VERSION ""

NS_ :

BS_:

BU_: AHLM ASBS CADM CBC DIAGNOST DPDM DTCM ECM EHPS ESC ESL ESM ETM EVCU2 GPF IC IRCM LTM OCM ORC PTS RF_HUB SCCM SGW TBM TCM

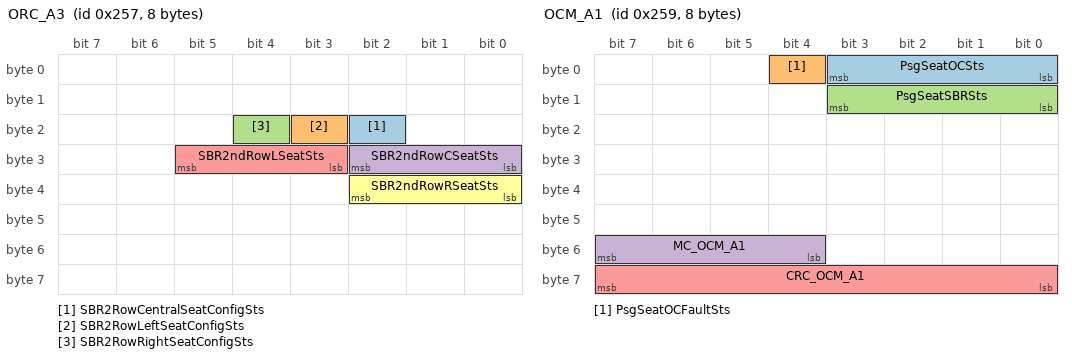
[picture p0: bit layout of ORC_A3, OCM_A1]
BO_ 599 ORC_A3: 8 ORC
 SG_ SBR2RowCentralSeatConfigSts : 18|1@1+ (1,0) [0|0] ""  IC,SGW
 SG_ SBR2RowLeftSeatConfigSts : 19|1@1+ (1,0) [0|0] ""  IC,SGW
 SG_ SBR2RowRightSeatConfigSts : 20|1@1+ (1,0) [0|0] ""  IC,SGW
 SG_ SBR2ndRowCSeatSts : 24|3@1+ (1,0) [0|0] ""  IC,SGW,TBM
 SG_ SBR2ndRowLSeatSts : 27|3@1+ (1,0) [0|0] ""  IC,SGW,TBM
 SG_ SBR2ndRowRSeatSts : 32|3@1+ (1,0) [0|0] ""  IC,SGW,TBM

BO_ 601 OCM_A1: 8 OCM
 SG_ PsgSeatOCSts : 0|4@1+ (1,0) [0|0] ""  ORC,RF_HUB,SGW
 SG_ PsgSeatOCFaultSts : 4|1@1+ (1,0) [0|0] ""  ORC,SGW
 SG_ PsgSeatSBRSts : 8|4@1+ (1,0) [0|0] ""  ORC,SGW
 SG_ MC_OCM_A1 : 52|4@1+ (1,0) [0|15] ""  ORC,SGW
 SG_ CRC_OCM_A1 : 56|8@1+ (1,0) [0|0] ""  ORC,SGW

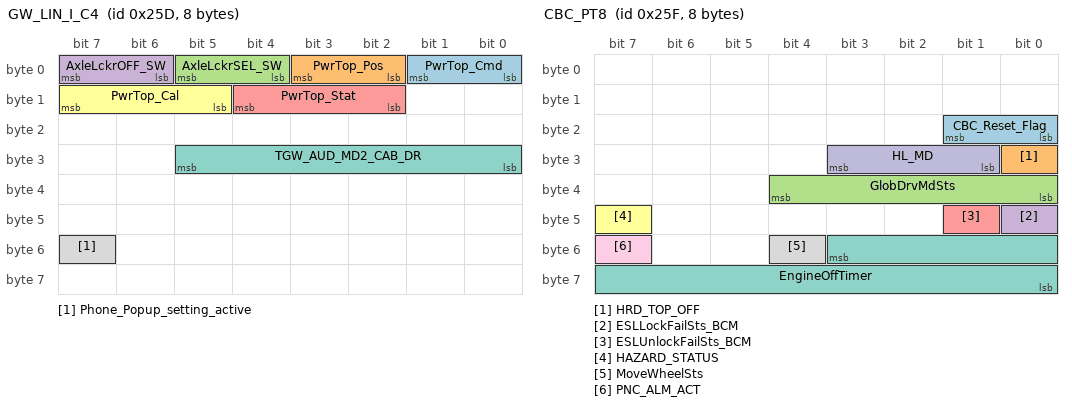
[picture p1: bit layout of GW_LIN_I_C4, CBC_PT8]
BO_ 605 GW_LIN_I_C4: 8 CBC
 SG_ PwrTop_Cmd : 0|2@1+ (1,0) [0|0] ""  SGW
 SG_ PwrTop_Pos : 2|2@1+ (1,0) [0|0] ""  SGW
 SG_ AxleLckrSEL_SW : 4|2@1+ (1,0) [0|0] ""  DTCM,SGW
 SG_ AxleLckrOFF_SW : 6|2@1+ (1,0) [0|0] ""  DTCM,SGW
 SG_ PwrTop_Stat : 10|3@1+ (1,0) [0|0] ""  IC,SGW
 SG_ PwrTop_Cal : 13|3@1+ (1,0) [0|0] ""  IC,SGW
 SG_ TGW_AUD_MD2_CAB_DR : 24|6@1+ (1,0) [0|0] ""  IC,SGW
 SG_ Phone_Popup_setting_active : 55|1@1+ (1,0) [0|0] ""  IC,SGW

BO_ 607 CBC_PT8: 8 CBC
 SG_ CBC_Reset_Flag : 16|2@1+ (1,0) [0|0] ""  ECM,SGW
 SG_ HRD_TOP_OFF : 24|1@1+ (1,0) [0|0] ""  SGW
 SG_ GlobDrvMdSts : 32|5@1+ (1,0) [0|0] ""  CADM,DTCM,ECM,ESC,EVCU2,IC,IRCM,ORC,SGW
 SG_ ESLLockFailSts_BCM : 40|1@1+ (1,0) [0|0] ""  IC,SGW
 SG_ ESLUnlockFailSts_BCM : 41|1@1+ (1,0) [0|0] ""  IC,SGW
 SG_ HAZARD_STATUS : 47|1@1+ (1,0) [0|0] ""  CADM,ORC,SGW
 SG_ EngineOffTimer : 51|12@0+ (1,0) [0|4080] "min"  ECM,ETM,SGW,TBM
 SG_ MoveWheelSts : 52|1@1+ (1,0) [0|0] ""  IC,SGW
 SG_ PNC_ALM_ACT : 55|1@1+ (1,0) [0|0] ""  SGW
 SG_ HL_MD : 25|3@1+ (1,0) [0|0] ""  CADM,SGW

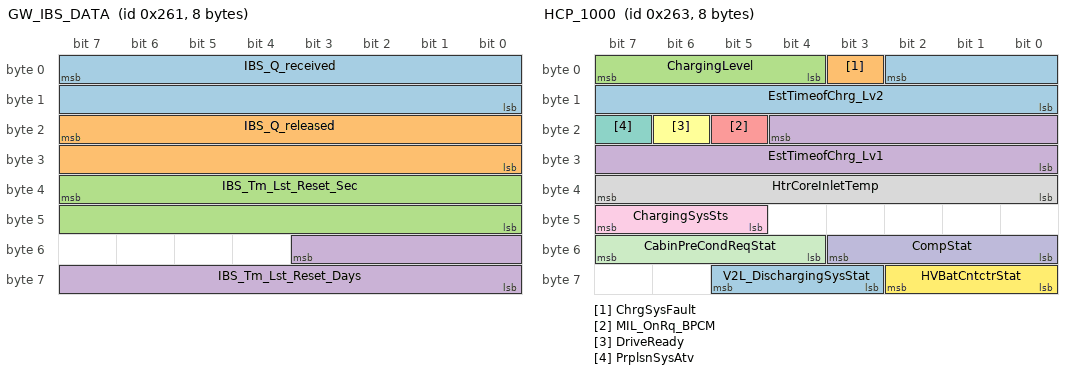
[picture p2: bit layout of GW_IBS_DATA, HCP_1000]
BO_ 609 GW_IBS_DATA: 8 CBC
 SG_ IBS_Q_received : 7|16@0+ (0.125,0) [0|8191.75] "Ah"  SGW
 SG_ IBS_Q_released : 23|16@0+ (0.125,0) [0|8191.75] "Ah"  SGW
 SG_ IBS_Tm_Lst_Reset_Sec : 39|16@0+ (2,0) [0|86398] "sec"  SGW
 SG_ IBS_Tm_Lst_Reset_Days : 51|12@0+ (1,0) [0|4094] "Days"  SGW

BO_ 611 HCP_1000: 8 EVCU2
 SG_ EstTimeofChrg_Lv2 : 2|11@0+ (1,0) [0|2046] "min"  CBC,ETM,IC,SGW,TBM
 SG_ ChrgSysFault : 3|1@1+ (1,0) [0|0] ""  ETM,IC,SGW,TBM
 SG_ ChargingLevel : 4|4@1+ (1,0) [0|0] ""  CBC,ETM,IC,SGW,TBM
 SG_ EstTimeofChrg_Lv1 : 20|13@0+ (1,0) [0|8190] "min"  CBC,ETM,IC,SGW,TBM
 SG_ MIL_OnRq_BPCM : 21|1@1+ (1,0) [0|0] ""  IC,SGW,TBM
 SG_ DriveReady : 22|1@1+ (1,0) [0|0] ""  AHLM,CADM,CBC,ETM,IC,IRCM,SGW,TBM
 SG_ PrplsnSysAtv : 23|1@1+ (1,0) [0|0] ""  CBC,ECM,EHPS,ESC,ETM,IC,RF_HUB,SGW,TBM
 SG_ HtrCoreInletTemp : 32|8@1+ (1,-40) [-40|214] "∞C"  CBC,ECM,SGW
 SG_ ChargingSysSts : 45|3@1+ (1,0) [0|0] ""  CBC,ETM,IC,SGW,TBM
 SG_ CompStat : 48|4@1+ (1,0) [0|0] ""  CBC,SGW
 SG_ CabinPreCondReqStat : 52|4@1+ (1,0) [0|0] ""  IC,SGW
 SG_ HVBatCntctrStat : 56|3@1+ (1,0) [0|0] ""  ETM,IC,ORC,SGW,TBM
 SG_ V2L_DischargingSysStat : 59|3@1+ (1,0) [0|0] ""  RF_HUB,SGW

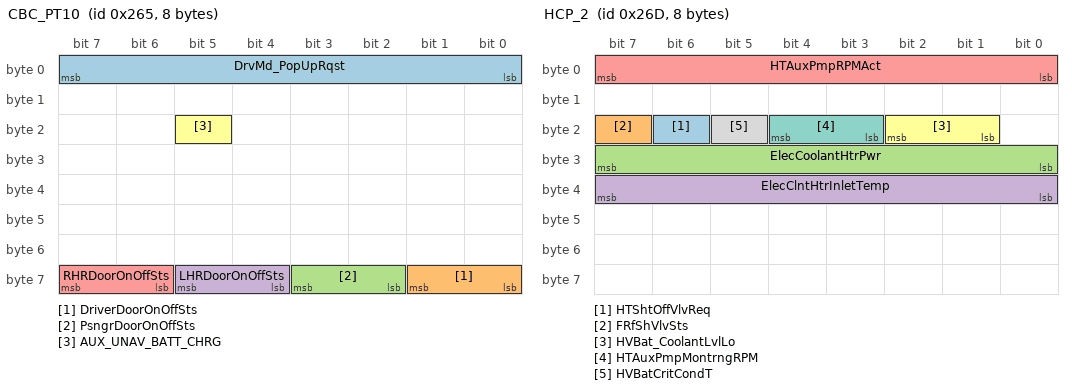
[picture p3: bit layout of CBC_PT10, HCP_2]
BO_ 613 CBC_PT10: 8 CBC
 SG_ DrvMd_PopUpRqst : 0|8@1+ (1,0) [0|0] ""  IC,SGW
 SG_ DriverDoorOnOffSts : 56|2@1+ (1,0) [0|0] ""  CADM,ESC,EVCU2,IC,IRCM,RF_HUB,SGW
 SG_ PsngrDoorOnOffSts : 58|2@1+ (1,0) [0|0] ""  RF_HUB,SGW
 SG_ LHRDoorOnOffSts : 60|2@1+ (1,0) [0|0] ""  RF_HUB,SGW
 SG_ RHRDoorOnOffSts : 62|2@1+ (1,0) [0|0] ""  RF_HUB,SGW
 SG_ AUX_UNAV_BATT_CHRG : 21|1@1+ (1,0) [0|0] ""  IC,SGW

BO_ 621 HCP_2: 8 EVCU2
 SG_ HTShtOffVlvReq : 22|1@1+ (1,0) [0|0] ""  CBC,ECM,SGW
 SG_ FRfShVlvSts : 23|1@1+ (1,0) [0|0] ""  CBC,SGW
 SG_ ElecCoolantHtrPwr : 24|8@1+ (0.04,0) [0|10.16] "kW"  CBC,ECM,SGW
 SG_ ElecClntHtrInletTemp : 32|8@1+ (1,-40) [-40|214] "∞C"  ECM,SGW
 SG_ HTAuxPmpRPMAct : 0|8@1+ (24,0) [0|6096] "rpm"  CBC,ECM,SGW
 SG_ HVBat_CoolantLvlLo : 17|2@1+ (1,0) [0|0] ""  IC,SGW
 SG_ HTAuxPmpMontrngRPM : 19|2@1+ (1,0) [0|0] ""  ECM,SGW
 SG_ HVBatCritCondT : 21|1@1+ (1,0) [0|0] ""  CBC,SGW

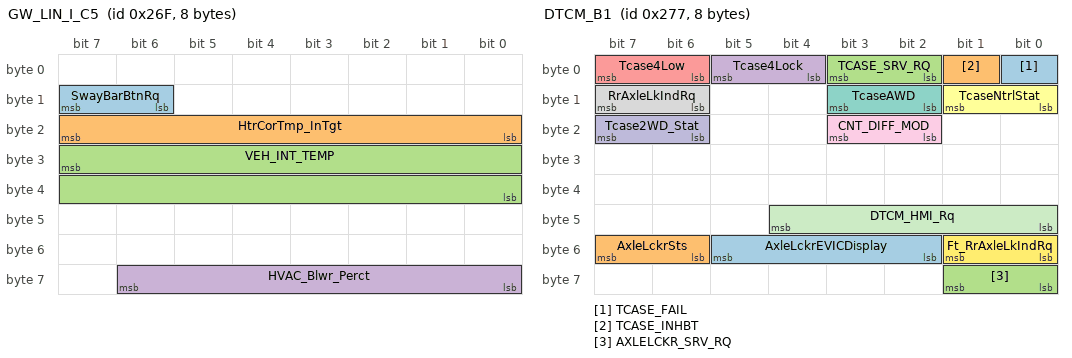
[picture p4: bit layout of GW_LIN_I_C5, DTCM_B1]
BO_ 623 GW_LIN_I_C5: 8 CBC
 SG_ SwayBarBtnRq : 14|2@1+ (1,0) [0|0] ""  ASBS,SGW
 SG_ HtrCorTmp_InTgt : 16|8@1+ (1,-40) [-40|214] "∞C"  EVCU2,SGW
 SG_ VEH_INT_TEMP : 31|16@0+ (0.01,-40) [-40|85] "∞C"  EVCU2,SGW
 SG_ HVAC_Blwr_Perct : 56|7@1+ (1,0) [0|100] "%"  EVCU2,SGW

BO_ 631 DTCM_B1: 8 DTCM
 SG_ TCASE_FAIL : 0|1@1+ (1,0) [0|0] ""  ECM,SGW
 SG_ TCASE_INHBT : 1|1@1+ (1,0) [0|0] ""  SGW
 SG_ TCASE_SRV_RQ : 2|2@1+ (1,0) [0|0] ""  ESC,ETM,EVCU2,IC,SGW,TBM
 SG_ Tcase4Lock : 4|2@1+ (1,0) [0|0] ""  CBC,ETM,IC,SGW
 SG_ Tcase4Low : 6|2@1+ (1,0) [0|0] ""  CBC,ETM,IC,SGW
 SG_ TcaseNtrlStat : 8|2@1+ (1,0) [0|0] ""  CBC,ETM,IC,SGW
 SG_ TcaseAWD : 10|2@1+ (1,0) [0|0] ""  CBC,ETM,IC,SGW
 SG_ RrAxleLkIndRq : 14|2@1+ (1,0) [0|0] ""  CBC,ETM,IC,ORC,SGW
 SG_ CNT_DIFF_MOD : 18|2@1+ (1,0) [0|0] ""  SGW
 SG_ Tcase2WD_Stat : 22|2@1+ (1,0) [0|0] ""  CBC,ETM,EVCU2,IC,SGW
 SG_ DTCM_HMI_Rq : 40|5@1+ (1,0) [0|0] ""  IC,SGW
 SG_ Ft_RrAxleLkIndRq : 48|2@1+ (1,0) [0|0] ""  CBC,ETM,IC,SGW
 SG_ AxleLckrEVICDisplay : 50|4@1+ (1,0) [0|0] ""  ETM,IC,SGW
 SG_ AxleLckrSts : 54|2@1+ (1,0) [0|0] ""  ESC,ETM,IC,ORC,SGW
 SG_ AXLELCKR_SRV_RQ : 56|2@1+ (1,0) [0|0] ""  IC,SGW

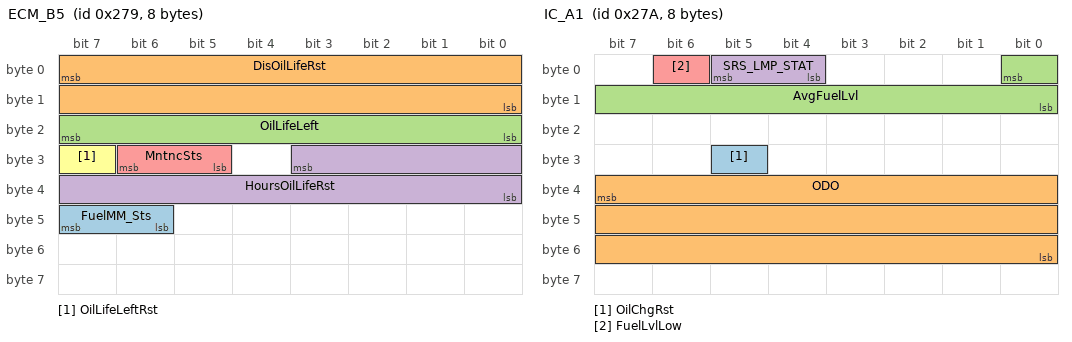
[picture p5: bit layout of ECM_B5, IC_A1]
BO_ 633 ECM_B5: 8 ECM
 SG_ FuelMM_Sts : 46|2@1+ (1,0) [0|0] ""  IC
 SG_ DisOilLifeRst : 7|16@0+ (1,0) [0|65534] "km"  CBC,IC,SGW
 SG_ OilLifeLeft : 16|8@1+ (1,0) [0|100] "%"  ETM,IC,SGW,TBM
 SG_ HoursOilLifeRst : 27|12@0+ (1,0) [0|4000] "Hours"  CBC,SGW
 SG_ MntncSts : 29|2@1+ (1,0) [0|0] ""  ETM,IC,SGW,TBM
 SG_ OilLifeLeftRst : 31|1@1+ (1,0) [0|0] ""  ETM,IC,SGW,TBM

BO_ 634 IC_A1: 8 IC
 SG_ OilChgRst : 29|1@1+ (1,0) [0|0] ""  ECM,SGW
 SG_ ODO : 39|24@0+ (0.1,0) [0|1677721.4] "km"  AHLM,ASBS,CADM,CBC,DPDM,DTCM,ECM,EHPS,ESC,ESL,ESM,ETM,EVCU2,IRCM,OCM,ORC,PTS,RF_HUB,SCCM,SGW,TBM,TCM
 SG_ AvgFuelLvl : 0|9@0+ (0.5,0) [0|255] "liters"  CBC,ECM,ETM,SGW,TBM
 SG_ SRS_LMP_STAT : 4|2@1+ (1,0) [0|0] ""  ETM,ORC,SGW,TBM
 SG_ FuelLvlLow : 6|1@1+ (1,0) [0|0] ""  CBC,ECM,ETM,EVCU2,SGW,TBM

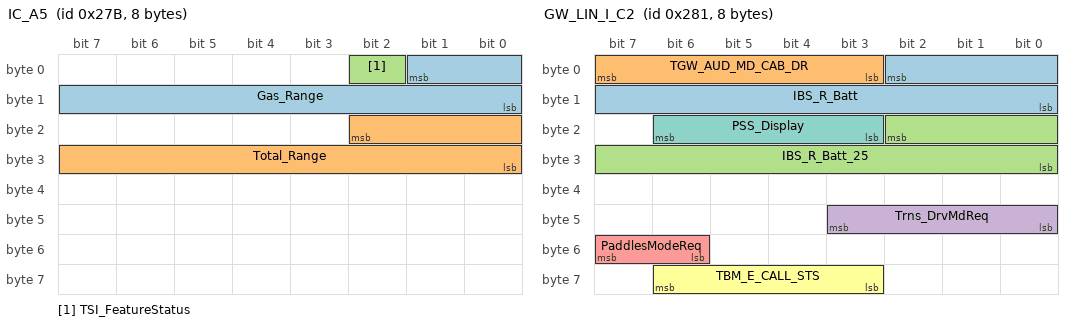
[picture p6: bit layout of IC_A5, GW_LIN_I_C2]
BO_ 635 IC_A5: 8 IC
 SG_ Gas_Range : 1|10@0+ (1,0) [0|1022] "km"  CBC,ETM,SGW,TBM
 SG_ Total_Range : 18|11@0+ (1,0) [0|2046] "km"  CBC,ETM,SGW,TBM
 SG_ TSI_FeatureStatus : 2|1@1+ (1,0) [0|0] ""  CBC,SGW

BO_ 641 GW_LIN_I_C2: 8 CBC
 SG_ IBS_R_Batt : 2|11@0+ (0.05,0) [0|20] "mOhm"  SGW
 SG_ TGW_AUD_MD_CAB_DR : 3|5@1+ (1,0) [0|0] ""  IC,SGW
 SG_ IBS_R_Batt_25 : 18|11@0+ (0.05,0) [0|20] "mOhm"  SGW
 SG_ Trns_DrvMdReq : 40|4@1+ (1,0) [0|0] ""  SGW,TCM
 SG_ PaddlesModeReq : 54|2@1+ (1,0) [0|0] ""  SGW,TCM
 SG_ TBM_E_CALL_STS : 59|4@1+ (1,0) [0|0] ""  IC,ORC,SGW
 SG_ PSS_Display : 19|4@1+ (1,0) [0|0] ""  IC,SGW

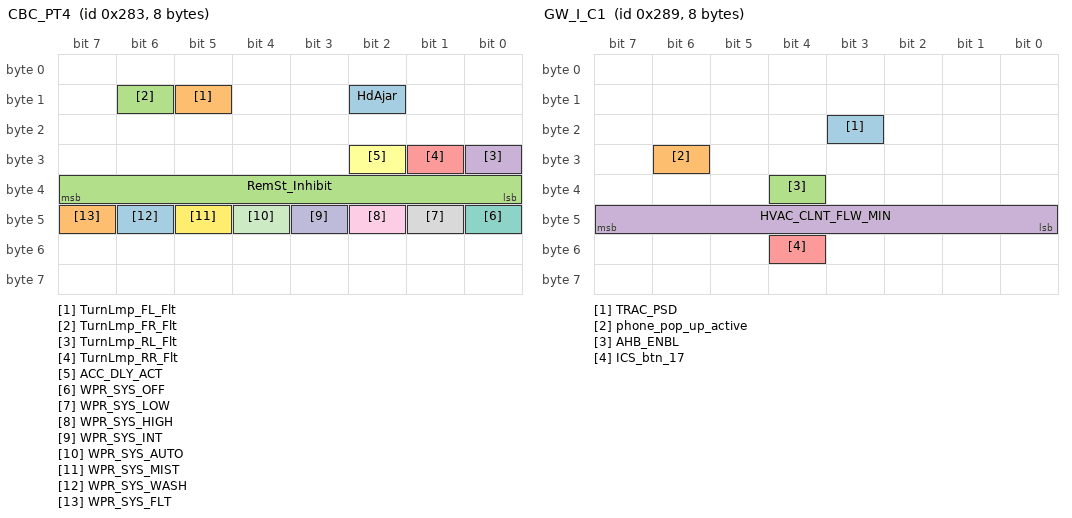
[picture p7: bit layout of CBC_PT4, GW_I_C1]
BO_ 643 CBC_PT4: 8 CBC
 SG_ HdAjar : 10|1@1+ (1,0) [0|0] ""  ETM,EVCU2,IC,SGW,TBM
 SG_ TurnLmp_FL_Flt : 13|1@1+ (1,0) [0|0] ""  ETM,IC,SGW,TBM
 SG_ TurnLmp_FR_Flt : 14|1@1+ (1,0) [0|0] ""  ETM,IC,SGW,TBM
 SG_ TurnLmp_RL_Flt : 24|1@1+ (1,0) [0|0] ""  ETM,IC,SGW,TBM
 SG_ TurnLmp_RR_Flt : 25|1@1+ (1,0) [0|0] ""  ETM,IC,SGW,TBM
 SG_ ACC_DLY_ACT : 26|1@1+ (1,0) [0|0] ""  EVCU2,IC,SGW
 SG_ WPR_SYS_OFF : 40|1@1+ (1,0) [0|0] ""  CADM,ESC,IRCM,SGW
 SG_ WPR_SYS_LOW : 41|1@1+ (1,0) [0|0] ""  CADM,ESC,IRCM,SGW
 SG_ WPR_SYS_HIGH : 42|1@1+ (1,0) [0|0] ""  CADM,ESC,IRCM,SGW
 SG_ WPR_SYS_INT : 43|1@1+ (1,0) [0|0] ""  CADM,ESC,IRCM,SGW
 SG_ WPR_SYS_AUTO : 44|1@1+ (1,0) [0|0] ""  CADM,ESC,IRCM,SGW
 SG_ WPR_SYS_MIST : 45|1@1+ (1,0) [0|0] ""  CADM,DTCM,ESC,IRCM,SGW
 SG_ WPR_SYS_WASH : 46|1@1+ (1,0) [0|0] ""  CADM,ESC,IRCM,SGW
 SG_ WPR_SYS_FLT : 47|1@1+ (1,0) [0|0] ""  CADM,ESC,IRCM,SGW
 SG_ RemSt_Inhibit : 32|8@1+ (1,0) [0|0] ""  IC,SGW,TBM

BO_ 649 GW_I_C1: 8 CBC
 SG_ TRAC_PSD : 19|1@1+ (1,0) [0|0] ""  ESC,ETM,SGW,TBM
 SG_ phone_pop_up_active : 30|1@1+ (1,0) [0|0] ""  IC,SGW
 SG_ AHB_ENBL : 36|1@1+ (1,0) [0|0] ""  CADM,IC,SGW
 SG_ HVAC_CLNT_FLW_MIN : 40|8@1+ (0.521555,0) [0.521555|131.953415] "LpM"  ECM,SGW
 SG_ ICS_btn_17 : 52|1@1+ (1,0) [0|0] ""  PTS,SGW

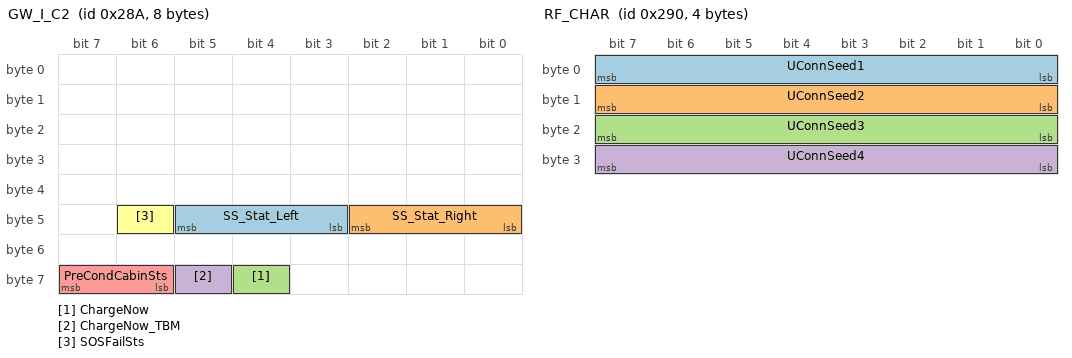
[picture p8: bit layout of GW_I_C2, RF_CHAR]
BO_ 650 GW_I_C2: 8 CBC
 SG_ SS_Stat_Left : 43|3@1+ (1,0) [0|0] ""  SGW
 SG_ SS_Stat_Right : 40|3@1+ (1,0) [0|0] ""  SGW
 SG_ ChargeNow : 60|1@1+ (1,0) [0|0] ""  EVCU2,SGW
 SG_ ChargeNow_TBM : 61|1@1+ (1,0) [0|0] ""  EVCU2,SGW
 SG_ PreCondCabinSts : 62|2@1+ (1,0) [0|0] ""  SGW
 SG_ SOSFailSts : 46|1@1+ (1,0) [0|0] ""  ORC,SGW

BO_ 651 GW_LIN_I_C3: 8 CBC
 SG_ HILL_DES_RQ_ICS : 49|2@1+ (1,0) [0|0] ""  ESC,SGW

BO_ 656 RF_CHAR: 4 RF_HUB
 SG_ UConnSeed1 : 0|8@1+ (1,0) [0|0] ""  SGW,TBM
 SG_ UConnSeed2 : 8|8@1+ (1,0) [0|0] ""  SGW,TBM
 SG_ UConnSeed3 : 16|8@1+ (1,0) [0|0] ""  SGW,TBM
 SG_ UConnSeed4 : 24|8@1+ (1,0) [0|0] ""  SGW,TBM

BO_ 657 CBC_PT1: 8 CBC
 SG_ FT_FOG_RQ : 2|1@1+ (1,0) [0|0] ""  CADM,ECM,ETM,IC,SGW,TBM
 SG_ R_FOG_RQ : 3|1@1+ (1,0) [0|0] ""  CADM,ECM,ETM,IC,SGW,TBM
 SG_ REV_GEAR : 4|1@1+ (1,0) [0|0] ""  DTCM,ESC,IC,ORC,PTS,SGW
 SG_ DR_LK_STAT : 5|2@1+ (1,0) [0|0] ""  SGW
 SG_ FOB_SrchRq : 8|2@1+ (1,0) [0|0] ""  RF_HUB,SGW
 SG_ AHB_ACT : 14|1@1+ (1,0) [0|0] ""  IC,SGW
 SG_ PARK_LMP_ON : 16|1@1+ (1,0) [0|0] ""  ETM,IC,SGW,TBM
 SG_ DRV_AJAR : 17|1@1+ (1,0) [0|0] ""  CADM,ECM,ESC,ETM,EVCU2,IC,IRCM,RF_HUB,SGW,TBM,TCM
 SG_ PSG_AJAR : 18|1@1+ (1,0) [0|0] ""  ESC,ETM,IC,RF_HUB,SGW,TBM
 SG_ L_R_AJAR : 19|1@1+ (1,0) [0|0] ""  ETM,IC,RF_HUB,SGW,TBM
 SG_ R_R_AJAR : 20|1@1+ (1,0) [0|0] ""  ETM,IC,RF_HUB,SGW,TBM
 SG_ TLG_AJAR : 22|1@1+ (1,0) [0|0] ""  ETM,IC,RF_HUB,SGW,TBM
 SG_ PARK_BRK_EGD : 23|1@1+ (1,0) [0|0] ""  CADM,ECM,ESC,EVCU2,IC,IRCM,ORC,RF_HUB,SGW,TCM
 SG_ IGN_OFF_TIME_LNG : 27|12@0+ (1,0) [0|4080] "min"  CADM,DTCM,ECM,ESC,IRCM,SGW,TCM
 SG_ SHIP_STAT : 28|2@1+ (1,0) [0|0] ""  CADM,DTCM,EVCU2,IC,IRCM,RF_HUB,SGW
 SG_ TurnInd_LT_ON : 30|1@1+ (1,0) [0|0] ""  ETM,IC,SGW,TBM
 SG_ TurnInd_RT_ON : 31|1@1+ (1,0) [0|0] ""  ETM,IC,SGW,TBM
 SG_ DAY_LGT_MD : 40|1@1+ (1,0) [0|0] ""  ESM,EVCU2,IC,ORC,RF_HUB,SGW
 SG_ PTC_REL1_STAT : 42|2@1+ (1,0) [0|0] ""  ECM,SGW
 SG_ PTC_REL2_STAT : 44|2@1+ (1,0) [0|0] ""  ECM,SGW
 SG_ PTC_REL3_STAT : 46|2@1+ (1,0) [0|0] ""  ECM,SGW
 SG_ PANEL_INTS : 48|8@1+ (0.5,0) [0|100] "%"  ESM,EVCU2,IC,RF_HUB,SGW
 SG_ FT_WPR_NOT_PRK : 56|1@1+ (1,0) [0|0] ""  CADM,DTCM,ECM,IRCM,SGW
 SG_ LOBEAM_ON : 57|1@1+ (1,0) [0|0] ""  AHLM,ECM,ETM,SGW,TBM
 SG_ HIBEAM_ON : 58|1@1+ (1,0) [0|0] ""  CADM,ECM,ETM,IC,IRCM,SGW,TBM
 SG_ BRK_FLUID_LO : 62|1@1+ (1,0) [0|0] ""  ESC,ETM,IC,SGW,TBM
 SG_ WASH_FLUID_LO : 63|1@1+ (1,0) [0|0] ""  ETM,IC,SGW,TBM

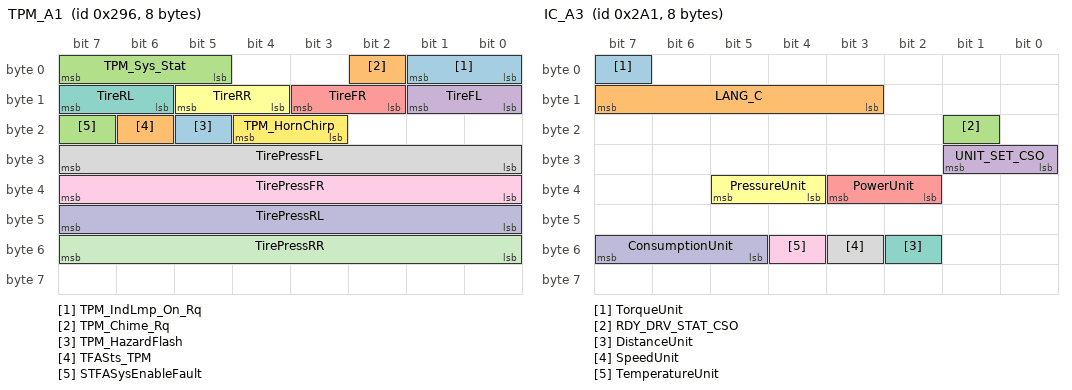
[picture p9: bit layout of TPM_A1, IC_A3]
BO_ 662 TPM_A1: 8 RF_HUB
 SG_ TPM_IndLmp_On_Rq : 0|2@1+ (1,0) [0|0] ""  ETM,IC,ORC,SGW,TBM
 SG_ TPM_Chime_Rq : 2|1@1+ (1,0) [0|0] ""  IC,SGW
 SG_ TPM_Sys_Stat : 5|3@1+ (1,0) [0|0] ""  IC,SGW
 SG_ TireFL : 8|2@1+ (1,0) [0|0] ""  ETM,IC,ORC,SGW,TBM
 SG_ TireFR : 10|2@1+ (1,0) [0|0] ""  ETM,IC,ORC,SGW,TBM
 SG_ TireRR : 12|2@1+ (1,0) [0|0] ""  ETM,IC,ORC,SGW,TBM
 SG_ TireRL : 14|2@1+ (1,0) [0|0] ""  ETM,IC,ORC,SGW,TBM
 SG_ TirePressFL : 24|8@1+ (1,0) [0|126] "psi"  ETM,IC,ORC,SGW,TBM
 SG_ TirePressFR : 32|8@1+ (1,0) [0|126] "psi"  ETM,IC,ORC,SGW,TBM
 SG_ TirePressRL : 40|8@1+ (1,0) [0|126] "psi"  ETM,IC,ORC,SGW,TBM
 SG_ TirePressRR : 48|8@1+ (1,0) [0|126] "psi"  ETM,IC,ORC,SGW,TBM
 SG_ TPM_HornChirp : 19|2@1+ (1,0) [0|0] ""  CBC,SGW
 SG_ TPM_HazardFlash : 21|1@1+ (1,0) [0|0] ""  CBC,IC,SGW
 SG_ TFASts_TPM : 22|1@1+ (1,0) [0|0] ""  CBC,SGW
 SG_ STFASysEnableFault : 23|1@1+ (1,0) [0|0] ""  CBC,SGW

BO_ 663 GW_LIN_I_C1: 8 CBC
 SG_ SpSt_Pad1 : 50|3@1+ (1,0) [0|0] ""  ECM,EVCU2,SGW
 SG_ SpSt_Pad2 : 53|3@1+ (1,0) [0|0] ""  ECM,EVCU2,SGW

BO_ 673 IC_A3: 8 IC
 SG_ TorqueUnit : 7|1@1+ (1,0) [0|0] ""  CBC,SGW
 SG_ LANG_C : 11|5@1+ (1,0) [0|0] ""  CBC,SGW,TBM
 SG_ RDY_DRV_STAT_CSO : 17|1@1+ (1,0) [0|0] ""  CBC,SGW
 SG_ UNIT_SET_CSO : 24|2@1+ (1,0) [0|0] ""  CBC,SGW
 SG_ PowerUnit : 34|2@1+ (1,0) [0|0] ""  CBC,SGW
 SG_ PressureUnit : 36|2@1+ (1,0) [0|0] ""  CBC,SGW
 SG_ DistanceUnit : 50|1@1+ (1,0) [0|0] ""  CBC,SGW
 SG_ SpeedUnit : 51|1@1+ (1,0) [0|0] ""  ASBS,CADM,CBC,ECM,EVCU2,IRCM,SGW
 SG_ TemperatureUnit : 52|1@1+ (1,0) [0|0] ""  CBC,SGW
 SG_ ConsumptionUnit : 53|3@1+ (1,0) [0|0] ""  CBC,SGW

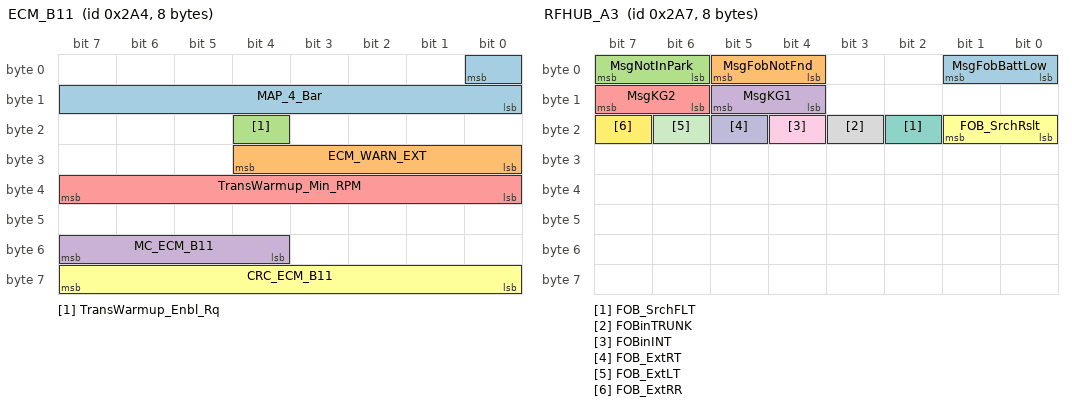
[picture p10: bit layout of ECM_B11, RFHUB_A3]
BO_ 676 ECM_B11: 8 ECM
 SG_ MAP_4_Bar : 0|9@0+ (0.8,0) [0|408] "kPa"  ETM,ORC,SGW,TBM
 SG_ ECM_WARN_EXT : 24|5@1+ (1,0) [0|0] ""  ETM,IC,SGW,TBM
 SG_ TransWarmup_Enbl_Rq : 20|1@1+ (1,0) [0|0] ""  SGW,TCM
 SG_ MC_ECM_B11 : 52|4@1+ (1,0) [0|15] ""  SGW,TCM
 SG_ TransWarmup_Min_RPM : 32|8@1+ (25,0) [0|6350] "rpm"  SGW,TCM
 SG_ CRC_ECM_B11 : 56|8@1+ (1,0) [0|0] ""  SGW,TCM

BO_ 679 RFHUB_A3: 8 RF_HUB
 SG_ MsgFobBattLow : 0|2@1+ (1,0) [0|0] ""  IC,SGW
 SG_ MsgFobNotFnd : 4|2@1+ (1,0) [0|0] ""  IC,SGW
 SG_ MsgNotInPark : 6|2@1+ (1,0) [0|0] ""  IC,SGW
 SG_ MsgKG1 : 12|2@1+ (1,0) [0|0] ""  CBC,IC,SGW
 SG_ MsgKG2 : 14|2@1+ (1,0) [0|0] ""  IC,SGW
 SG_ FOB_SrchRslt : 16|2@1+ (1,0) [0|0] ""  CBC,SGW
 SG_ FOB_SrchFLT : 18|1@1+ (1,0) [0|0] ""  CBC,SGW
 SG_ FOBinTRUNK : 19|1@1+ (1,0) [0|0] ""  SGW
 SG_ FOBinINT : 20|1@1+ (1,0) [0|0] ""  CBC,SGW
 SG_ FOB_ExtRT : 21|1@1+ (1,0) [0|0] ""  CBC,SGW
 SG_ FOB_ExtLT : 22|1@1+ (1,0) [0|0] ""  CBC,SGW
 SG_ FOB_ExtRR : 23|1@1+ (1,0) [0|0] ""  CBC,SGW

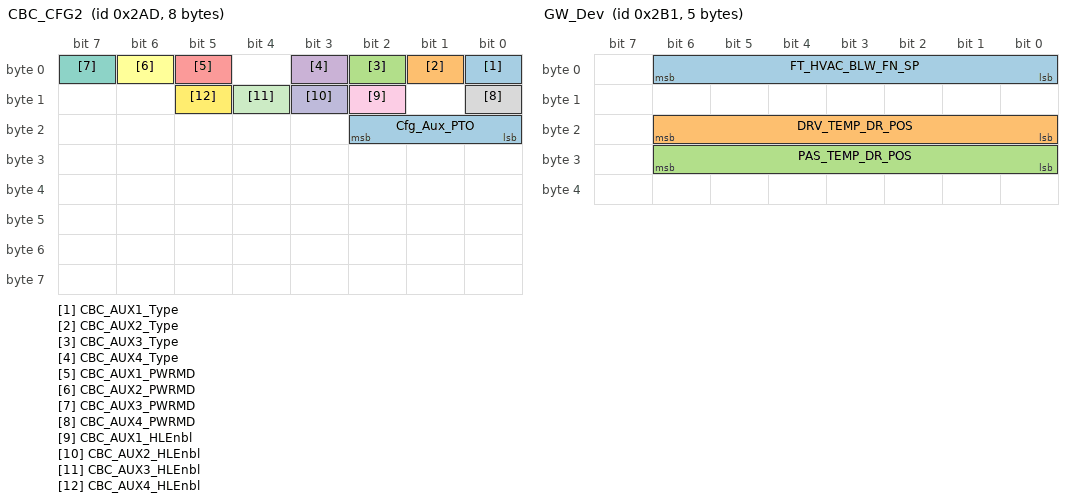
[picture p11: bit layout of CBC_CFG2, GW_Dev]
BO_ 685 CBC_CFG2: 8 CBC
 SG_ CBC_AUX1_Type : 0|1@1+ (1,0) [0|0] ""  SGW
 SG_ CBC_AUX2_Type : 1|1@1+ (1,0) [0|0] ""  SGW
 SG_ CBC_AUX3_Type : 2|1@1+ (1,0) [0|0] ""  SGW
 SG_ CBC_AUX4_Type : 3|1@1+ (1,0) [0|0] ""  SGW
 SG_ CBC_AUX1_PWRMD : 5|1@1+ (1,0) [0|0] ""  SGW
 SG_ CBC_AUX2_PWRMD : 6|1@1+ (1,0) [0|0] ""  SGW
 SG_ CBC_AUX3_PWRMD : 7|1@1+ (1,0) [0|0] ""  SGW
 SG_ CBC_AUX4_PWRMD : 8|1@1+ (1,0) [0|0] ""  SGW
 SG_ CBC_AUX1_HLEnbl : 10|1@1+ (1,0) [0|0] ""  SGW
 SG_ CBC_AUX2_HLEnbl : 11|1@1+ (1,0) [0|0] ""  SGW
 SG_ CBC_AUX3_HLEnbl : 12|1@1+ (1,0) [0|0] ""  SGW
 SG_ CBC_AUX4_HLEnbl : 13|1@1+ (1,0) [0|0] ""  SGW
 SG_ Cfg_Aux_PTO : 16|3@1+ (1,0) [0|0] ""  SGW

BO_ 689 GW_Dev: 5 CBC
 SG_ FT_HVAC_BLW_FN_SP : 0|7@1+ (1,0) [0|100] "Bars"  ECM,SGW
 SG_ DRV_TEMP_DR_POS : 16|7@1+ (1,0) [0|100] "%"  ECM,EVCU2,SGW
 SG_ PAS_TEMP_DR_POS : 24|7@1+ (1,0) [0|100] "%"  EVCU2,SGW

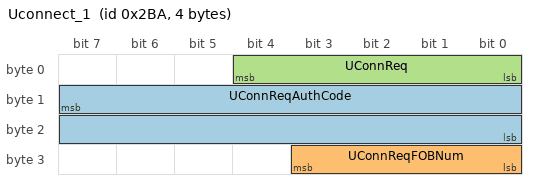
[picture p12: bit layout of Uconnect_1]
BO_ 698 Uconnect_1: 4 SGW
 SG_ UConnReqAuthCode : 15|16@0+ (1,0) [0|0] ""  RF_HUB
 SG_ UConnReqFOBNum : 24|4@1+ (1,0) [0|0] ""  RF_HUB
 SG_ UConnReq : 0|5@1+ (1,0) [0|0] ""  RF_HUB

BO_TX_BU_ 676 : ECM,EVCU2;
BO_TX_BU_ 698 : SGW,TBM;
CM_ SG_ 599 SBR2RowCentralSeatConfigSts "Second row central seatbelt switch configuration; Seat checked = [1]";
CM_ SG_ 599 SBR2RowLeftSeatConfigSts "Second row left seatbelt switch configuration; Seat checked = [1]";
CM_ SG_ 599 SBR2RowRightSeatConfigSts "Second row right seatbelt switch configuration; Seat checked = [1]";
CM_ SG_ 599 SBR2ndRowCSeatSts "Second row central seatbelt reminder status";
CM_ SG_ 599 SBR2ndRowLSeatSts "Second row left seatbelt reminder status";
CM_ SG_ 599 SBR2ndRowRSeatSts "Second row right seatbelt reminder status";
CM_ SG_ 601 PsgSeatOCSts "Occupant classification passenger";
CM_ SG_ 601 PsgSeatOCFaultSts "Passenger occupant classification fault; True = [1]";
CM_ SG_ 601 PsgSeatSBRSts "Passenger seatbelt reminder status";
CM_ SG_ 601 MC_OCM_A1 "Message counter";
CM_ SG_ 601 CRC_OCM_A1 "CRC-checksum byte 1 to 7 according to SAE J1850";
CM_ SG_ 605 PwrTop_Cmd "Power Top Switch Status";
CM_ SG_ 605 PwrTop_Pos "Power Top Roof Position";
CM_ SG_ 605 AxleLckrSEL_SW "Axle locker selection switch";
CM_ SG_ 605 AxleLckrOFF_SW "Axle locker deactivation switch";
CM_ SG_ 605 PwrTop_Stat "Power Top Operation Status";
CM_ SG_ 605 PwrTop_Cal "Power Top Calibration Status";
CM_ SG_ 605 TGW_AUD_MD2_CAB_DR "TGW additional audio modes for Cabin/Driver";
CM_ SG_ 605 Phone_Popup_setting_active "Phone call status popup active or not, Active=1";
CM_ SG_ 607 CBC_Reset_Flag "CBC reset flag";
CM_ SG_ 607 HRD_TOP_OFF "Removable hard top is off";
CM_ SG_ 607 GlobDrvMdSts "Global drive mode status";
CM_ SG_ 607 ESLLockFailSts_BCM "Display info on failed lock; Failed = [1]";
CM_ SG_ 607 ESLUnlockFailSts_BCM "Display info on failed unlock; Failed = [1]";
CM_ SG_ 607 HAZARD_STATUS "Hazard lamps; active = [1]";
CM_ SG_ 607 EngineOffTimer "Engine off timer - engine off ignition NOT lock.";
CM_ SG_ 607 MoveWheelSts "Display message to move steering wheel; Active = [1]";
CM_ SG_ 607 PNC_ALM_ACT "Panic alarm active; [1] = True";
CM_ SG_ 607 HL_MD "High Beam Lever Setting";
CM_ SG_ 609 IBS_Q_received "LifeTime charge received";
CM_ SG_ 609 IBS_Q_released "Lifetime charge released";
CM_ SG_ 609 IBS_Tm_Lst_Reset_Sec "Accumulated time since last reset in seconds";
CM_ SG_ 609 IBS_Tm_Lst_Reset_Days "Accumulated time since last reset in days";
CM_ SG_ 611 EstTimeofChrg_Lv2 "Estimated Time to charge on Level 2";
CM_ SG_ 611 ChrgSysFault "Charging System Fault status";
CM_ SG_ 611 ChargingLevel "Charging level and type.";
CM_ SG_ 611 EstTimeofChrg_Lv1 "Estimated Time to charge on Level 1";
CM_ SG_ 611 MIL_OnRq_BPCM "MIL Lamp request from BPCM.";
CM_ SG_ 611 DriveReady "Ready to Drive, [1] = Vehicle is allowed to shift out of park or neutral";
CM_ SG_ 611 PrplsnSysAtv "Propulsion system active, [1] = active";
CM_ SG_ 611 HtrCoreInletTemp "Heater Core Inlet Temp";
CM_ SG_ 611 ChargingSysSts "Charging System status";
CM_ SG_ 611 CompStat "comppressor state";
CM_ SG_ 611 CabinPreCondReqStat "Cabin Preconditioning Request Status";
CM_ SG_ 611 HVBatCntctrStat "HV Battery pack contactor state";
CM_ SG_ 611 V2L_DischargingSysStat "Discharging system status";
CM_ SG_ 613 DrvMd_PopUpRqst "Drive modes HMI pop-up message request";
CM_ SG_ 613 DriverDoorOnOffSts "Driver door on/off status";
CM_ SG_ 613 PsngrDoorOnOffSts "Passenger door on/off status";
CM_ SG_ 613 LHRDoorOnOffSts "Left rear door on/off status";
CM_ SG_ 613 RHRDoorOnOffSts "Right rear door on/off status";
CM_ SG_ 613 AUX_UNAV_BATT_CHRG "AUX unaviable due to battery charging warning, 1 = Unaviable";
CM_ SG_ 621 HTShtOffVlvReq "High temp shut off valve request; [0] = Open, [1] = Closed";
CM_ SG_ 621 FRfShVlvSts "Front Refrigerant Shutoff Valve Status";
CM_ SG_ 621 ElecCoolantHtrPwr "Electric Coolant Heater Power";
CM_ SG_ 621 ElecClntHtrInletTemp "Electric Coolant Heater Inlet Temperature";
CM_ SG_ 621 HTAuxPmpRPMAct "High Temp Aux Pump Status";
CM_ SG_ 621 HVBat_CoolantLvlLo "Battery coolant level low";
CM_ SG_ 621 HTAuxPmpMontrngRPM "High Temp Aux Pump RPM monitoring active";
CM_ SG_ 621 HVBatCritCondT "High Voltage Battery Temperature Critical Condition, [1] = True";
CM_ SG_ 623 SwayBarBtnRq "Sway bar disconnect switch request";
CM_ SG_ 623 HtrCorTmp_InTgt "Heater core temp target";
CM_ SG_ 623 VEH_INT_TEMP "Vehicle interior temperature";
CM_ SG_ 623 HVAC_Blwr_Perct "HVAC blower PWM percentage for service mode";
CM_ SG_ 631 TCASE_FAIL "T Case System Fault (Limp in)";
CM_ SG_ 631 TCASE_INHBT "All wheel drive mode inhibited";
CM_ SG_ 631 TCASE_SRV_RQ "Transfer case service indicator request";
CM_ SG_ 631 Tcase4Lock "Transfer case 4WD locked status";
CM_ SG_ 631 Tcase4Low "Transfer case low range LED status";
CM_ SG_ 631 TcaseNtrlStat "Transfer case neutral LED status";
CM_ SG_ 631 TcaseAWD "Transfer case High range / AWD LED status";
CM_ SG_ 631 RrAxleLkIndRq "Rear axle lock indicator request";
CM_ SG_ 631 CNT_DIFF_MOD "Actual mode of center differential";
CM_ SG_ 631 Tcase2WD_Stat "Transfer case 2 wheel drive status";
CM_ SG_ 631 DTCM_HMI_Rq "DTCM AWD / 4WD HMI display request";
CM_ SG_ 631 Ft_RrAxleLkIndRq "Front and Rear axle lock indicator request";
CM_ SG_ 631 AxleLckrEVICDisplay "Axle locker HMI display request";
CM_ SG_ 631 AxleLckrSts "Axle locker status";
CM_ SG_ 631 AXLELCKR_SRV_RQ "Axle locker service indicator request";
CM_ SG_ 633 FuelMM_Sts "Fuel maintenance mode status";
CM_ SG_ 633 DisOilLifeRst "Distance since last oil life reset";
CM_ SG_ 633 OilLifeLeft "Oil life left";
CM_ SG_ 633 HoursOilLifeRst "Hours since last oil life reset";
CM_ SG_ 633 MntncSts "Maintenance reminder status";
CM_ SG_ 633 OilLifeLeftRst "Oil life remaining has been reset";
CM_ SG_ 634 OilChgRst "Oil change reminder reset request";
CM_ SG_ 634 ODO "Odometer";
CM_ SG_ 634 AvgFuelLvl "Average filtered fuel level in liters";
CM_ SG_ 634 SRS_LMP_STAT "Airbag indicator lamp status";
CM_ SG_ 634 FuelLvlLow "Fuel level low";
CM_ SG_ 635 Gas_Range "Gas range or DTE";
CM_ SG_ 635 Total_Range "Total range or DTE";
CM_ SG_ 635 TSI_FeatureStatus "TSI_FeatureStatus [1 = Active, 0 = Not Active]";
CM_ SG_ 641 IBS_R_Batt "Calculated battery resistance";
CM_ SG_ 641 TGW_AUD_MD_CAB_DR "TGW audio mode for Cabin/Driver";
CM_ SG_ 641 IBS_R_Batt_25 "Batt resistance at 100% SOC and 25 degC";
CM_ SG_ 641 Trns_DrvMdReq "The requested state of the drive mode feature";
CM_ SG_ 641 PaddlesModeReq "Requested state of paddle lock-out function";
CM_ SG_ 641 TBM_E_CALL_STS "E call status messages";
CM_ SG_ 641 PSS_Display "Power side step display";
CM_ SG_ 643 HdAjar "Hood latch ajar, left or single (1=ajar)";
CM_ SG_ 643 TurnLmp_FL_Flt "Turn indication lamp front left fault";
CM_ SG_ 643 TurnLmp_FR_Flt "Turn indication lamp front right fault";
CM_ SG_ 643 TurnLmp_RL_Flt "Turn indication lamp rear left fault";
CM_ SG_ 643 TurnLmp_RR_Flt "Turn indication lamp rear right fault";
CM_ SG_ 643 ACC_DLY_ACT "Accessory Delay Active";
CM_ SG_ 643 WPR_SYS_OFF "Wiper system off; [1] = switch is OFF";
CM_ SG_ 643 WPR_SYS_LOW "Wiper system low; [1] = switch is LOW";
CM_ SG_ 643 WPR_SYS_HIGH "Wiper system high; [1] = switch is HIGH";
CM_ SG_ 643 WPR_SYS_INT "Wiper system intermittent; [1] = switch is INT";
CM_ SG_ 643 WPR_SYS_AUTO "Wiper system auto; [1] = Auto wipers equipped";
CM_ SG_ 643 WPR_SYS_MIST "Wiper system mist; [1] = mist request";
CM_ SG_ 643 WPR_SYS_WASH "Wiper system wash; [1] = wash request";
CM_ SG_ 643 WPR_SYS_FLT "Wiper system fault present; [1] = fault present";
CM_ SG_ 643 RemSt_Inhibit "Remote start inhibit";
CM_ SG_ 649 TRAC_PSD "Traction on/off button pressed; [0] = Not Pressed, [1] = Pressed";
CM_ SG_ 649 phone_pop_up_active "Phone pop up is active; True = [1]";
CM_ SG_ 649 AHB_ENBL "Auto highbeam enable";
CM_ SG_ 649 HVAC_CLNT_FLW_MIN "HVAC coolant flow minimum request";
CM_ SG_ 649 ICS_btn_17 "PTS Off pressed";
CM_ SG_ 650 SS_Stat_Left "Left power side step status";
CM_ SG_ 650 SS_Stat_Right "Right power side step status";
CM_ SG_ 650 ChargeNow "Charge Now Signal";
CM_ SG_ 650 ChargeNow_TBM "Charge Now Signal TBM";
CM_ SG_ 650 PreCondCabinSts "HVAC Pre-Condition Status";
CM_ SG_ 650 SOSFailSts "SOS System Fail Status";
CM_ SG_ 651 HILL_DES_RQ_ICS "Hill descent or select speed status";
CM_ SG_ 656 UConnSeed1 "Character 1";
CM_ SG_ 656 UConnSeed2 "Character 2";
CM_ SG_ 656 UConnSeed3 "Character 3";
CM_ SG_ 656 UConnSeed4 "Character 4";
CM_ SG_ 657 FT_FOG_RQ "Front fog request; off=[0], on=[1]";
CM_ SG_ 657 R_FOG_RQ "Rear fog request; [0] = off, [1] = on";
CM_ SG_ 657 REV_GEAR "Reverse Gear (manual trans)";
CM_ SG_ 657 DR_LK_STAT "Door lock status";
CM_ SG_ 657 FOB_SrchRq "FOB search request";
CM_ SG_ 657 AHB_ACT "Automatic high beam active";
CM_ SG_ 657 PARK_LMP_ON "Parklamps are on; off=[0], on=[1]";
CM_ SG_ 657 DRV_AJAR "Driver door ajar (1 = Door Ajar)";
CM_ SG_ 657 PSG_AJAR "Passenger door ajar";
CM_ SG_ 657 L_R_AJAR "Left rear door ajar";
CM_ SG_ 657 R_R_AJAR "Right rear door ajar";
CM_ SG_ 657 TLG_AJAR "Trunk/Liftgate ajar";
CM_ SG_ 657 PARK_BRK_EGD "Park brake switch engaged";
CM_ SG_ 657 IGN_OFF_TIME_LNG "Time since last ignition on (long)";
CM_ SG_ 657 SHIP_STAT "Shipping status";
CM_ SG_ 657 TurnInd_LT_ON "Turn indication left is on";
CM_ SG_ 657 TurnInd_RT_ON "Turn indication right is on";
CM_ SG_ 657 DAY_LGT_MD "Day light brightness mode; Night=[0], Day=[1]";
CM_ SG_ 657 PTC_REL1_STAT "PTC Relay # 1 Status";
CM_ SG_ 657 PTC_REL2_STAT "PTC Relay # 2 Status";
CM_ SG_ 657 PTC_REL3_STAT "PTC Relay # 3 Status";
CM_ SG_ 657 PANEL_INTS "Panel-/display intensity";
CM_ SG_ 657 FT_WPR_NOT_PRK "Front wiper outside park position";
CM_ SG_ 657 LOBEAM_ON "Low beam is on; off=[0], on=[1]";
CM_ SG_ 657 HIBEAM_ON "High beam is on; off=[0], on=[1]";
CM_ SG_ 657 BRK_FLUID_LO "Low brake fluid warning; low = [1]";
CM_ SG_ 657 WASH_FLUID_LO "Low washer fluid warning (1=Fluid is low)";
CM_ SG_ 662 TPM_IndLmp_On_Rq "Tire pressure indication request";
CM_ SG_ 662 TPM_Chime_Rq "TPM chime request";
CM_ SG_ 662 TPM_Sys_Stat "TPM system localization status";
CM_ SG_ 662 TireFL "Tire front left";
CM_ SG_ 662 TireFR "Tire front right";
CM_ SG_ 662 TireRR "Tire rear right";
CM_ SG_ 662 TireRL "Tire rear left";
CM_ SG_ 662 TirePressFL "Tire pressure front left";
CM_ SG_ 662 TirePressFR "Tire pressure front right";
CM_ SG_ 662 TirePressRL "Tire pressure rear left";
CM_ SG_ 662 TirePressRR "Tire pressure rear right";
CM_ SG_ 662 TPM_HornChirp "TPM horn chirp";
CM_ SG_ 662 TPM_HazardFlash "TPM hazard flash;  true = [1]";
CM_ SG_ 662 TFASts_TPM "Tire fill alert status; Disabled = [0], Enabled = [1]";
CM_ SG_ 662 STFASysEnableFault "STFA system enable fault; Absent = [0], Present = [1]";
CM_ SG_ 663 SpSt_Pad1 "Stop / start switch - pad 1";
CM_ SG_ 663 SpSt_Pad2 "Stop / start switch - pad 2";
CM_ SG_ 673 TorqueUnit "Torque units; Foot Pounds (ft-lb) = [1]";
CM_ SG_ 673 LANG_C "Language preference (5 bit)";
CM_ SG_ 673 RDY_DRV_STAT_CSO "Ready to drive popup status enable/disable; Disabled = [1]";
CM_ SG_ 673 UNIT_SET_CSO "Unit set status enable/disable";
CM_ SG_ 673 PowerUnit "Power units";
CM_ SG_ 673 PressureUnit "Pressure units";
CM_ SG_ 673 DistanceUnit "Distance (odometer) units; Miles = [1]";
CM_ SG_ 673 SpeedUnit "Speed (speedometer) units; Miles = [1]";
CM_ SG_ 673 TemperatureUnit "Temperature units; Farenheit = [1]";
CM_ SG_ 673 ConsumptionUnit "Fuel consumption units";
CM_ SG_ 676 MAP_4_Bar "Engine manifold pressure (4 bar range)";
CM_ SG_ 676 ECM_WARN_EXT "HMI extended warnings";
CM_ SG_ 676 TransWarmup_Enbl_Rq "Enable and disable flag for transmission warm up feature, 0h = WarmUp_NOT_Enabled 1h = WarmUp_Enabled";
CM_ SG_ 676 MC_ECM_B11 "Message counter";
CM_ SG_ 676 TransWarmup_Min_RPM "Minimal engine rpm request for transmission warm up feature";
CM_ SG_ 676 CRC_ECM_B11 "CRC-Checksum Byte 1 - 7 according to SAE J1850";
CM_ SG_ 679 MsgFobBattLow "Indicates battery low on FOBIK last used for RKE purposes";
CM_ SG_ 679 MsgFobNotFnd "FOB Not Detected.";
CM_ SG_ 679 MsgNotInPark "Vehicle was not in Park.";
CM_ SG_ 679 MsgKG1 "Place holder for future.";
CM_ SG_ 679 MsgKG2 "Place holder for future.";
CM_ SG_ 679 FOB_SrchRslt "FOB search result";
CM_ SG_ 679 FOB_SrchFLT "FOB search fault";
CM_ SG_ 679 FOBinTRUNK "FOB is in zone trunk";
CM_ SG_ 679 FOBinINT "FOB is in zone interior";
CM_ SG_ 679 FOB_ExtRT "FOB is in zone exterior right";
CM_ SG_ 679 FOB_ExtLT "FOB is in zone exterior left";
CM_ SG_ 679 FOB_ExtRR "FOB is in zone exterior rear";
CM_ SG_ 685 CBC_AUX1_Type "Aux switch 1 behavior; Latching = [0], Momentary = [1]";
CM_ SG_ 685 CBC_AUX2_Type "Aux switch 2 behavior; Latching = [0], Momentary = [1]";
CM_ SG_ 685 CBC_AUX3_Type "Aux switch 3 behavior; Latching = [0], Momentary = [1]";
CM_ SG_ 685 CBC_AUX4_Type "Aux switch 4 behavior; Latching = [0], Momentary = [1]";
CM_ SG_ 685 CBC_AUX1_PWRMD "Aux switch 1 power mode; ignition = [0], battery = [1]";
CM_ SG_ 685 CBC_AUX2_PWRMD "Aux switch 2 power mode; ignition = [0], battery = [1]";
CM_ SG_ 685 CBC_AUX3_PWRMD "Aux switch 3 power mode; ignition = [0], battery = [1]";
CM_ SG_ 685 CBC_AUX4_PWRMD "Aux switch 4 power mode; ignition = [0], battery = [1]";
CM_ SG_ 685 CBC_AUX1_HLEnbl "Aux switch 1 enable holding last state; enabled = [1]";
CM_ SG_ 685 CBC_AUX2_HLEnbl "Aux switch 2 enable holding last state; enabled = [1]";
CM_ SG_ 685 CBC_AUX3_HLEnbl "Aux switch 3 enable holding last state; enabled = [1]";
CM_ SG_ 685 CBC_AUX4_HLEnbl "Aux switch 4 enable holding last state; enabled = [1]";
CM_ SG_ 685 Cfg_Aux_PTO "AUX Switches Configuration";
CM_ SG_ 689 FT_HVAC_BLW_FN_SP "Front HVAC blower fan speed status in 'bars'";
CM_ SG_ 689 DRV_TEMP_DR_POS "Driver temperature door postion";
CM_ SG_ 689 PAS_TEMP_DR_POS "Passenger temperature door postion";
CM_ SG_ 698 UConnReqAuthCode "Authorization for requests";
CM_ SG_ 698 UConnReqFOBNum "FOB number making the request";
CM_ SG_ 698 UConnReq "Basic Uconnect request";
BA_DEF_ BO_  "App-Botschaft" ENUM  "nein","ja";
BA_DEF_ BO_  "CanMsgMinLen" INT 0 8;
BA_DEF_ BO_  "DiagRequest" ENUM  "nein","ja";
BA_DEF_ BO_  "DiagResponse" ENUM  "nein","ja";
BA_DEF_ BO_  "DiagState" ENUM  "nein","ja";
BA_DEF_ BO_  "GenMsgCycleTime" INT 0 65535;
BA_DEF_ BO_  "GenMsgCycleTimeActive" INT 0 65535;
BA_DEF_ BO_  "GenMsgDelayTime" INT 0 65535;
BA_DEF_ BO_  "GenMsgNrOfRepetitions" INT 0 65535;
BA_DEF_ BO_  "GenMsgSendType" ENUM  "cyclicX","spontanX","cyclicIfActiveX","spontanWithDelay","cyclicAndSpontanX","cyclicAndSpontanWithDelay","spontanWithRepitition","cyclicIfActiveAndSpontanWD","cyclicIfActiveFast","cyclicWithRepeatOnDemand","none";
BA_DEF_ BO_  "GenMsgStartDelayTime" INT 0 65535;
BA_DEF_ BO_  "GenMsgStartValue" STRING ;
BA_DEF_ BO_  "NWM-Botschaft" ENUM  "nein","ja";
BA_DEF_ BO_  "TpTxIndex" INT 0 99;
BA_DEF_ SG_  "FlexKomComment" STRING ;
BA_DEF_ SG_  "FlexKomIsMotorola" ENUM  "nein","ja";
BA_DEF_ SG_  "FlexKomSID" INT 0 2147483647;
BA_DEF_ SG_  "FlexKomSigLaenge" INT 0 64;
BA_DEF_ SG_  "FlexKomSigName" STRING ;
BA_DEF_ SG_  "FlexKomSigStartPos" INT 0 63;
BA_DEF_ SG_  "FlexKomSigStartValue" STRING ;
BA_DEF_ SG_  "GenSigCycleTime" INT 0 65535;
BA_DEF_ SG_  "GenSigCycleTimeActive" INT 0 65535;
BA_DEF_ SG_  "GenSigSendType" ENUM  "cyclicX","spontanX","cyclicIfActiveX","spontanWithDelay","cyclicAndSpontanX","cyclicAndSpontanWithDelay","spontanWithRepitition","cyclicIfActiveAndSpontanWD","cyclicIfActiveFast","cyclicWithRepeatOnDemand","none";
BA_DEF_ SG_  "GenSigSNA" STRING ;
BA_DEF_ SG_  "GenSigStartValue" HEX 0 2147483648;
BA_DEF_ SG_  "GenSigTimeout_AHLM" INT 0 65535;
BA_DEF_ SG_  "GenSigTimeout_ASBS" INT 0 65535;
BA_DEF_ SG_  "GenSigTimeout_CBC" INT 0 65535;
BA_DEF_ SG_  "GenSigTimeout_DPDM" INT 0 65535;
BA_DEF_ SG_  "GenSigTimeout_DTCM" INT 0 65535;
BA_DEF_ SG_  "GenSigTimeout_EHPS" INT 0 65535;
BA_DEF_ SG_  "GenSigTimeout_ESC" INT 0 65535;
BA_DEF_ SG_  "GenSigTimeout_ESL" INT 0 65535;
BA_DEF_ SG_  "GenSigTimeout_ESM" INT 0 65535;
BA_DEF_ SG_  "GenSigTimeout_ETM" INT 0 65535;
BA_DEF_ SG_  "GenSigTimeout_IC" INT 0 65535;
BA_DEF_ SG_  "GenSigTimeout_OCM" INT 0 65535;
BA_DEF_ SG_  "GenSigTimeout_ORC" INT 0 65535;
BA_DEF_ SG_  "GenSigTimeout_PTS" INT 0 65535;
BA_DEF_ SG_  "GenSigTimeout_RF_HUB" INT 0 65535;
BA_DEF_ SG_  "GenSigTimeout_SCCM" INT 0 65535;
BA_DEF_ SG_  "GenSigTimeout_TBM" INT 0 65535;
BA_DEF_ SG_  "GenSigTimeout_TCM" INT 0 65535;
BA_DEF_ SG_  "GenSigTimeout_TPM" INT 0 65535;
BA_DEF_ SG_  "RID" STRING ;
BA_DEF_ SG_  "SystemSignalLongSymbol" STRING ;
BA_DEF_DEF_  "App-Botschaft" "nein";
BA_DEF_DEF_  "CanMsgMinLen" 0;
BA_DEF_DEF_  "DiagRequest" "nein";
BA_DEF_DEF_  "DiagResponse" "nein";
BA_DEF_DEF_  "DiagState" "nein";
BA_DEF_DEF_  "GenMsgCycleTime" 0;
BA_DEF_DEF_  "GenMsgCycleTimeActive" 0;
BA_DEF_DEF_  "GenMsgDelayTime" 0;
BA_DEF_DEF_  "GenMsgNrOfRepetitions" 0;
BA_DEF_DEF_  "GenMsgSendType" "cyclicX";
BA_DEF_DEF_  "GenMsgStartDelayTime" 0;
BA_DEF_DEF_  "GenMsgStartValue" "";
BA_DEF_DEF_  "NWM-Botschaft" "nein";
BA_DEF_DEF_  "TpTxIndex" 0;
BA_DEF_DEF_  "FlexKomComment" "";
BA_DEF_DEF_  "FlexKomIsMotorola" "nein";
BA_DEF_DEF_  "FlexKomSID" 0;
BA_DEF_DEF_  "FlexKomSigLaenge" 0;
BA_DEF_DEF_  "FlexKomSigName" "";
BA_DEF_DEF_  "FlexKomSigStartPos" 0;
BA_DEF_DEF_  "FlexKomSigStartValue" "";
BA_DEF_DEF_  "GenSigCycleTime" 0;
BA_DEF_DEF_  "GenSigCycleTimeActive" 0;
BA_DEF_DEF_  "GenSigSendType" "cyclicX";
BA_DEF_DEF_  "GenSigSNA" "";
BA_DEF_DEF_  "GenSigStartValue" 0;
BA_DEF_DEF_  "GenSigTimeout_AHLM" 0;
BA_DEF_DEF_  "GenSigTimeout_ASBS" 0;
BA_DEF_DEF_  "GenSigTimeout_CBC" 0;
BA_DEF_DEF_  "GenSigTimeout_DPDM" 0;
BA_DEF_DEF_  "GenSigTimeout_DTCM" 0;
BA_DEF_DEF_  "GenSigTimeout_EHPS" 0;
BA_DEF_DEF_  "GenSigTimeout_ESC" 0;
BA_DEF_DEF_  "GenSigTimeout_ESL" 0;
BA_DEF_DEF_  "GenSigTimeout_ESM" 0;
BA_DEF_DEF_  "GenSigTimeout_ETM" 0;
BA_DEF_DEF_  "GenSigTimeout_IC" 0;
BA_DEF_DEF_  "GenSigTimeout_OCM" 0;
BA_DEF_DEF_  "GenSigTimeout_ORC" 0;
BA_DEF_DEF_  "GenSigTimeout_PTS" 0;
BA_DEF_DEF_  "GenSigTimeout_RF_HUB" 0;
BA_DEF_DEF_  "GenSigTimeout_SCCM" 0;
BA_DEF_DEF_  "GenSigTimeout_TBM" 0;
BA_DEF_DEF_  "GenSigTimeout_TCM" 0;
BA_DEF_DEF_  "GenSigTimeout_TPM" 0;
BA_DEF_DEF_  "RID" "";
BA_DEF_DEF_  "SystemSignalLongSymbol" "";
BA_ "GenMsgStartValue" BO_ 599 "FF0F000000000000h";
BA_ "GenMsgSendType" BO_ 599 5;
BA_ "GenMsgNrOfRepetitions" BO_ 599 2;
BA_ "GenMsgDelayTime" BO_ 599 20;
BA_ "GenMsgCycleTime" BO_ 599 1000;
BA_ "GenMsgStartValue" BO_ 601 "0F0F0000000000FFh";
BA_ "GenMsgSendType" BO_ 601 5;
BA_ "GenMsgNrOfRepetitions" BO_ 601 2;
BA_ "GenMsgDelayTime" BO_ 601 20;
BA_ "GenMsgCycleTime" BO_ 601 1000;
BA_ "GenMsgStartValue" BO_ 605 "000000007F7F7F7Fh";
BA_ "GenMsgSendType" BO_ 605 5;
BA_ "GenMsgNrOfRepetitions" BO_ 605 2;
BA_ "GenMsgDelayTime" BO_ 605 20;
BA_ "GenMsgCycleTime" BO_ 605 1000;
BA_ "GenMsgStartValue" BO_ 607 "0000000000000FFFh";
BA_ "GenMsgStartDelayTime" BO_ 607 40;
BA_ "GenMsgSendType" BO_ 607 5;
BA_ "GenMsgNrOfRepetitions" BO_ 607 2;
BA_ "GenMsgDelayTime" BO_ 607 20;
BA_ "GenMsgCycleTime" BO_ 607 1000;
BA_ "GenMsgStartValue" BO_ 609 "FFFFFFFF00000000h";
BA_ "GenMsgStartDelayTime" BO_ 609 90;
BA_ "GenMsgNrOfRepetitions" BO_ 609 2;
BA_ "GenMsgDelayTime" BO_ 609 20;
BA_ "GenMsgCycleTime" BO_ 609 1000;
BA_ "GenMsgStartValue" BO_ 611 "0000000000000000h";
BA_ "GenMsgSendType" BO_ 611 5;
BA_ "GenMsgNrOfRepetitions" BO_ 611 2;
BA_ "GenMsgDelayTime" BO_ 611 20;
BA_ "GenMsgCycleTime" BO_ 611 1000;
BA_ "GenMsgStartValue" BO_ 613 "00000000003F06FFh";
BA_ "GenMsgSendType" BO_ 613 5;
BA_ "GenMsgNrOfRepetitions" BO_ 613 2;
BA_ "GenMsgDelayTime" BO_ 613 20;
BA_ "GenMsgCycleTime" BO_ 613 1000;
BA_ "GenMsgStartValue" BO_ 621 "00001E0000000000h";
BA_ "GenMsgSendType" BO_ 621 5;
BA_ "GenMsgNrOfRepetitions" BO_ 621 2;
BA_ "GenMsgDelayTime" BO_ 621 20;
BA_ "GenMsgCycleTime" BO_ 621 1000;
BA_ "GenMsgStartValue" BO_ 623 "0000FFFFFF7F7F7Fh";
BA_ "GenMsgSendType" BO_ 623 5;
BA_ "GenMsgNrOfRepetitions" BO_ 623 2;
BA_ "GenMsgDelayTime" BO_ 623 20;
BA_ "GenMsgCycleTime" BO_ 623 1000;
BA_ "GenMsgStartValue" BO_ 631 "0000000000000000h";
BA_ "GenMsgSendType" BO_ 631 5;
BA_ "GenMsgNrOfRepetitions" BO_ 631 2;
BA_ "GenMsgDelayTime" BO_ 631 20;
BA_ "GenMsgCycleTime" BO_ 631 1000;
BA_ "GenMsgStartValue" BO_ 633 "FFFFFF0FFF00FF00h";
BA_ "GenMsgNrOfRepetitions" BO_ 633 2;
BA_ "GenMsgDelayTime" BO_ 633 20;
BA_ "GenMsgCycleTime" BO_ 633 1000;
BA_ "GenMsgStartValue" BO_ 634 "01FF0000FFFFFF07h";
BA_ "GenMsgSendType" BO_ 634 5;
BA_ "GenMsgNrOfRepetitions" BO_ 634 2;
BA_ "GenMsgDelayTime" BO_ 634 20;
BA_ "GenMsgCycleTime" BO_ 634 1000;
BA_ "GenMsgStartValue" BO_ 635 "A3FF07FF00000000h";
BA_ "GenMsgSendType" BO_ 635 5;
BA_ "GenMsgNrOfRepetitions" BO_ 635 2;
BA_ "GenMsgDelayTime" BO_ 635 20;
BA_ "GenMsgCycleTime" BO_ 635 1000;
BA_ "GenMsgStartValue" BO_ 641 "07FF07FF00000004h";
BA_ "GenMsgStartDelayTime" BO_ 641 130;
BA_ "GenMsgSendType" BO_ 641 5;
BA_ "GenMsgNrOfRepetitions" BO_ 641 2;
BA_ "GenMsgDelayTime" BO_ 641 20;
BA_ "GenMsgCycleTime" BO_ 641 1000;
BA_ "GenMsgStartValue" BO_ 643 "000C000000010000h";
BA_ "GenMsgStartDelayTime" BO_ 643 30;
BA_ "GenMsgSendType" BO_ 643 5;
BA_ "GenMsgNrOfRepetitions" BO_ 643 2;
BA_ "GenMsgDelayTime" BO_ 643 20;
BA_ "GenMsgCycleTime" BO_ 643 1000;
BA_ "GenMsgStartValue" BO_ 649 "3000071EC0FF8000h";
BA_ "GenMsgStartDelayTime" BO_ 649 80;
BA_ "GenMsgSendType" BO_ 649 5;
BA_ "GenMsgNrOfRepetitions" BO_ 649 2;
BA_ "GenMsgDelayTime" BO_ 649 20;
BA_ "GenMsgCycleTime" BO_ 649 1000;
BA_ "GenMsgStartValue" BO_ 650 "00000000003F0000h";
BA_ "GenMsgSendType" BO_ 650 5;
BA_ "GenMsgNrOfRepetitions" BO_ 650 2;
BA_ "GenMsgDelayTime" BO_ 650 20;
BA_ "GenMsgCycleTime" BO_ 650 1000;
BA_ "GenMsgStartValue" BO_ 651 "00000000001E0000h";
BA_ "GenMsgSendType" BO_ 651 5;
BA_ "GenMsgNrOfRepetitions" BO_ 651 2;
BA_ "GenMsgDelayTime" BO_ 651 20;
BA_ "GenMsgCycleTime" BO_ 651 1000;
BA_ "GenMsgStartValue" BO_ 656 "00000000h";
BA_ "GenMsgSendType" BO_ 656 1;
BA_ "GenMsgNrOfRepetitions" BO_ 656 2;
BA_ "GenMsgDelayTime" BO_ 656 20;
BA_ "GenMsgStartValue" BO_ 657 "6000003FFFFC0000h";
BA_ "GenMsgStartDelayTime" BO_ 657 20;
BA_ "GenMsgSendType" BO_ 657 5;
BA_ "GenMsgNrOfRepetitions" BO_ 657 2;
BA_ "GenMsgDelayTime" BO_ 657 20;
BA_ "GenMsgCycleTime" BO_ 657 1000;
BA_ "GenMsgStartValue" BO_ 662 "000000FFFFFFFFFFh";
BA_ "GenMsgSendType" BO_ 662 5;
BA_ "GenMsgNrOfRepetitions" BO_ 662 2;
BA_ "GenMsgDelayTime" BO_ 662 20;
BA_ "GenMsgCycleTime" BO_ 662 1000;
BA_ "GenMsgStartValue" BO_ 663 "F0FF0300000C00FFh";
BA_ "GenMsgStartDelayTime" BO_ 663 100;
BA_ "GenMsgSendType" BO_ 663 5;
BA_ "GenMsgNrOfRepetitions" BO_ 663 2;
BA_ "GenMsgDelayTime" BO_ 663 20;
BA_ "GenMsgCycleTime" BO_ 663 1000;
BA_ "GenMsgStartValue" BO_ 673 "00F8FCF001FE01FEh";
BA_ "GenMsgSendType" BO_ 673 5;
BA_ "GenMsgNrOfRepetitions" BO_ 673 2;
BA_ "GenMsgDelayTime" BO_ 673 20;
BA_ "GenMsgCycleTime" BO_ 673 1000;
BA_ "GenMsgStartValue" BO_ 676 "01FF0700000000FFh";
BA_ "GenMsgNrOfRepetitions" BO_ 676 2;
BA_ "GenMsgDelayTime" BO_ 676 20;
BA_ "GenMsgCycleTime" BO_ 676 100;
BA_ "GenMsgStartValue" BO_ 679 "0000000000000000h";
BA_ "GenMsgSendType" BO_ 679 5;
BA_ "GenMsgNrOfRepetitions" BO_ 679 2;
BA_ "GenMsgDelayTime" BO_ 679 20;
BA_ "GenMsgCycleTime" BO_ 679 1000;
BA_ "GenMsgStartValue" BO_ 685 "000007000000FFFFh";
BA_ "GenMsgStartDelayTime" BO_ 685 110;
BA_ "GenMsgSendType" BO_ 685 5;
BA_ "GenMsgNrOfRepetitions" BO_ 685 2;
BA_ "GenMsgDelayTime" BO_ 685 20;
BA_ "GenMsgCycleTime" BO_ 685 1000;
BA_ "GenMsgStartValue" BO_ 689 "7F8FFFFF7Fh";
BA_ "GenMsgStartDelayTime" BO_ 689 70;
BA_ "GenMsgSendType" BO_ 689 5;
BA_ "GenMsgNrOfRepetitions" BO_ 689 2;
BA_ "GenMsgDelayTime" BO_ 689 20;
BA_ "GenMsgCycleTime" BO_ 689 1000;
BA_ "GenMsgStartValue" BO_ 698 "00000000h";
BA_ "GenMsgSendType" BO_ 698 8;
BA_ "GenMsgNrOfRepetitions" BO_ 698 2;
BA_ "GenMsgDelayTime" BO_ 698 20;
BA_ "GenMsgCycleTimeActive" BO_ 698 100;
BA_ "GenSigTimeout_IC" SG_ 599 SBR2RowCentralSeatConfigSts 10500;
BA_ "GenSigSNA" SG_ 599 SBR2RowCentralSeatConfigSts "0h";
BA_ "GenSigSendType" SG_ 599 SBR2RowCentralSeatConfigSts 5;
BA_ "GenSigCycleTime" SG_ 599 SBR2RowCentralSeatConfigSts 1000;
BA_ "FlexKomSigStartValue" SG_ 599 SBR2RowCentralSeatConfigSts "00h";
BA_ "FlexKomSigStartPos" SG_ 599 SBR2RowCentralSeatConfigSts 18;
BA_ "FlexKomSigName" SG_ 599 SBR2RowCentralSeatConfigSts "SBR2RowCentralSeatConfigSts";
BA_ "FlexKomSigLaenge" SG_ 599 SBR2RowCentralSeatConfigSts 1;
BA_ "FlexKomSID" SG_ 599 SBR2RowCentralSeatConfigSts 1975;
BA_ "FlexKomIsMotorola" SG_ 599 SBR2RowCentralSeatConfigSts 1;
BA_ "FlexKomComment" SG_ 599 SBR2RowCentralSeatConfigSts "Second row central seatbelt switch configuration; ";
BA_ "GenSigTimeout_IC" SG_ 599 SBR2RowLeftSeatConfigSts 10500;
BA_ "GenSigSNA" SG_ 599 SBR2RowLeftSeatConfigSts "0h";
BA_ "GenSigSendType" SG_ 599 SBR2RowLeftSeatConfigSts 5;
BA_ "GenSigCycleTime" SG_ 599 SBR2RowLeftSeatConfigSts 1000;
BA_ "FlexKomSigStartValue" SG_ 599 SBR2RowLeftSeatConfigSts "00h";
BA_ "FlexKomSigStartPos" SG_ 599 SBR2RowLeftSeatConfigSts 19;
BA_ "FlexKomSigName" SG_ 599 SBR2RowLeftSeatConfigSts "SBR2RowLeftSeatConfigSts";
BA_ "FlexKomSigLaenge" SG_ 599 SBR2RowLeftSeatConfigSts 1;
BA_ "FlexKomSID" SG_ 599 SBR2RowLeftSeatConfigSts 1976;
BA_ "FlexKomIsMotorola" SG_ 599 SBR2RowLeftSeatConfigSts 1;
BA_ "FlexKomComment" SG_ 599 SBR2RowLeftSeatConfigSts "Second row left seatbelt switch configuration; Sea";
BA_ "GenSigTimeout_IC" SG_ 599 SBR2RowRightSeatConfigSts 10500;
BA_ "GenSigSNA" SG_ 599 SBR2RowRightSeatConfigSts "0h";
BA_ "GenSigSendType" SG_ 599 SBR2RowRightSeatConfigSts 5;
BA_ "GenSigCycleTime" SG_ 599 SBR2RowRightSeatConfigSts 1000;
BA_ "FlexKomSigStartValue" SG_ 599 SBR2RowRightSeatConfigSts "00h";
BA_ "FlexKomSigStartPos" SG_ 599 SBR2RowRightSeatConfigSts 20;
BA_ "FlexKomSigName" SG_ 599 SBR2RowRightSeatConfigSts "SBR2RowRightSeatConfigSts";
BA_ "FlexKomSigLaenge" SG_ 599 SBR2RowRightSeatConfigSts 1;
BA_ "FlexKomSID" SG_ 599 SBR2RowRightSeatConfigSts 1977;
BA_ "FlexKomIsMotorola" SG_ 599 SBR2RowRightSeatConfigSts 1;
BA_ "FlexKomComment" SG_ 599 SBR2RowRightSeatConfigSts "Second row right seatbelt switch configuration; Se";
BA_ "GenSigTimeout_IC" SG_ 599 SBR2ndRowCSeatSts 10500;
BA_ "GenSigStartValue" SG_ 599 SBR2ndRowCSeatSts 6;
BA_ "GenSigSNA" SG_ 599 SBR2ndRowCSeatSts "6h";
BA_ "GenSigSendType" SG_ 599 SBR2ndRowCSeatSts 5;
BA_ "GenSigCycleTime" SG_ 599 SBR2ndRowCSeatSts 1000;
BA_ "FlexKomSigStartValue" SG_ 599 SBR2ndRowCSeatSts "06h";
BA_ "FlexKomSigStartPos" SG_ 599 SBR2ndRowCSeatSts 26;
BA_ "FlexKomSigName" SG_ 599 SBR2ndRowCSeatSts "SBR2ndRowCSeatSts";
BA_ "FlexKomSigLaenge" SG_ 599 SBR2ndRowCSeatSts 3;
BA_ "FlexKomSID" SG_ 599 SBR2ndRowCSeatSts 2766;
BA_ "FlexKomIsMotorola" SG_ 599 SBR2ndRowCSeatSts 1;
BA_ "FlexKomComment" SG_ 599 SBR2ndRowCSeatSts "Second row central seatbelt reminder status";
BA_ "GenSigTimeout_IC" SG_ 599 SBR2ndRowLSeatSts 10500;
BA_ "GenSigStartValue" SG_ 599 SBR2ndRowLSeatSts 6;
BA_ "GenSigSNA" SG_ 599 SBR2ndRowLSeatSts "6h";
BA_ "GenSigSendType" SG_ 599 SBR2ndRowLSeatSts 5;
BA_ "GenSigCycleTime" SG_ 599 SBR2ndRowLSeatSts 1000;
BA_ "FlexKomSigStartValue" SG_ 599 SBR2ndRowLSeatSts "06h";
BA_ "FlexKomSigStartPos" SG_ 599 SBR2ndRowLSeatSts 29;
BA_ "FlexKomSigName" SG_ 599 SBR2ndRowLSeatSts "SBR2ndRowLSeatSts";
BA_ "FlexKomSigLaenge" SG_ 599 SBR2ndRowLSeatSts 3;
BA_ "FlexKomSID" SG_ 599 SBR2ndRowLSeatSts 2767;
BA_ "FlexKomIsMotorola" SG_ 599 SBR2ndRowLSeatSts 1;
BA_ "FlexKomComment" SG_ 599 SBR2ndRowLSeatSts "Second row left seatbelt reminder status";
BA_ "GenSigTimeout_IC" SG_ 599 SBR2ndRowRSeatSts 10500;
BA_ "GenSigStartValue" SG_ 599 SBR2ndRowRSeatSts 6;
BA_ "GenSigSNA" SG_ 599 SBR2ndRowRSeatSts "6h";
BA_ "GenSigSendType" SG_ 599 SBR2ndRowRSeatSts 5;
BA_ "GenSigCycleTime" SG_ 599 SBR2ndRowRSeatSts 1000;
BA_ "FlexKomSigStartValue" SG_ 599 SBR2ndRowRSeatSts "06h";
BA_ "FlexKomSigStartPos" SG_ 599 SBR2ndRowRSeatSts 34;
BA_ "FlexKomSigName" SG_ 599 SBR2ndRowRSeatSts "SBR2ndRowRSeatSts";
BA_ "FlexKomSigLaenge" SG_ 599 SBR2ndRowRSeatSts 3;
BA_ "FlexKomSID" SG_ 599 SBR2ndRowRSeatSts 2768;
BA_ "FlexKomIsMotorola" SG_ 599 SBR2ndRowRSeatSts 1;
BA_ "FlexKomComment" SG_ 599 SBR2ndRowRSeatSts "Second row right seatbelt reminder status";
BA_ "GenSigTimeout_ORC" SG_ 601 PsgSeatOCSts 3500;
BA_ "GenSigStartValue" SG_ 601 PsgSeatOCSts 15;
BA_ "GenSigSNA" SG_ 601 PsgSeatOCSts "Fh";
BA_ "GenSigSendType" SG_ 601 PsgSeatOCSts 5;
BA_ "GenSigCycleTime" SG_ 601 PsgSeatOCSts 1000;
BA_ "FlexKomSigStartValue" SG_ 601 PsgSeatOCSts "0F0F0000000000FFh";
BA_ "FlexKomSigStartPos" SG_ 601 PsgSeatOCSts 7;
BA_ "FlexKomSigName" SG_ 601 PsgSeatOCSts "OC_P_Stat";
BA_ "FlexKomSigLaenge" SG_ 601 PsgSeatOCSts 64;
BA_ "FlexKomSID" SG_ 601 PsgSeatOCSts 1586;
BA_ "FlexKomIsMotorola" SG_ 601 PsgSeatOCSts 1;
BA_ "FlexKomComment" SG_ 601 PsgSeatOCSts "Passenger occupant classification system status";
BA_ "GenSigTimeout_ORC" SG_ 601 PsgSeatOCFaultSts 3500;
BA_ "GenSigSNA" SG_ 601 PsgSeatOCFaultSts "0h";
BA_ "GenSigSendType" SG_ 601 PsgSeatOCFaultSts 5;
BA_ "GenSigCycleTime" SG_ 601 PsgSeatOCFaultSts 1000;
BA_ "FlexKomSigStartValue" SG_ 601 PsgSeatOCFaultSts "0F0F0000000000FFh";
BA_ "FlexKomSigStartPos" SG_ 601 PsgSeatOCFaultSts 7;
BA_ "FlexKomSigName" SG_ 601 PsgSeatOCFaultSts "OC_P_Stat";
BA_ "FlexKomSigLaenge" SG_ 601 PsgSeatOCFaultSts 64;
BA_ "FlexKomSID" SG_ 601 PsgSeatOCFaultSts 1586;
BA_ "FlexKomIsMotorola" SG_ 601 PsgSeatOCFaultSts 1;
BA_ "FlexKomComment" SG_ 601 PsgSeatOCFaultSts "Passenger occupant classification system status";
BA_ "GenSigTimeout_ORC" SG_ 601 PsgSeatSBRSts 3500;
BA_ "GenSigStartValue" SG_ 601 PsgSeatSBRSts 15;
BA_ "GenSigSNA" SG_ 601 PsgSeatSBRSts "Fh";
BA_ "GenSigSendType" SG_ 601 PsgSeatSBRSts 5;
BA_ "GenSigCycleTime" SG_ 601 PsgSeatSBRSts 1000;
BA_ "FlexKomSigStartValue" SG_ 601 PsgSeatSBRSts "0F0F0000000000FFh";
BA_ "FlexKomSigStartPos" SG_ 601 PsgSeatSBRSts 7;
BA_ "FlexKomSigName" SG_ 601 PsgSeatSBRSts "OC_P_Stat";
BA_ "FlexKomSigLaenge" SG_ 601 PsgSeatSBRSts 64;
BA_ "FlexKomSID" SG_ 601 PsgSeatSBRSts 1586;
BA_ "FlexKomIsMotorola" SG_ 601 PsgSeatSBRSts 1;
BA_ "FlexKomComment" SG_ 601 PsgSeatSBRSts "Passenger occupant classification system status";
BA_ "GenSigTimeout_ORC" SG_ 601 MC_OCM_A1 3500;
BA_ "GenSigSNA" SG_ 601 MC_OCM_A1 "0h";
BA_ "GenSigSendType" SG_ 601 MC_OCM_A1 5;
BA_ "GenSigCycleTime" SG_ 601 MC_OCM_A1 1000;
BA_ "FlexKomSigStartValue" SG_ 601 MC_OCM_A1 "0F0F0000000000FFh";
BA_ "FlexKomSigStartPos" SG_ 601 MC_OCM_A1 7;
BA_ "FlexKomSigName" SG_ 601 MC_OCM_A1 "OC_P_Stat";
BA_ "FlexKomSigLaenge" SG_ 601 MC_OCM_A1 64;
BA_ "FlexKomSID" SG_ 601 MC_OCM_A1 1586;
BA_ "FlexKomIsMotorola" SG_ 601 MC_OCM_A1 1;
BA_ "FlexKomComment" SG_ 601 MC_OCM_A1 "Passenger occupant classification system status";
BA_ "GenSigTimeout_ORC" SG_ 601 CRC_OCM_A1 3500;
BA_ "GenSigStartValue" SG_ 601 CRC_OCM_A1 255;
BA_ "GenSigSNA" SG_ 601 CRC_OCM_A1 "FFh";
BA_ "GenSigSendType" SG_ 601 CRC_OCM_A1 5;
BA_ "GenSigCycleTime" SG_ 601 CRC_OCM_A1 1000;
BA_ "FlexKomSigStartValue" SG_ 601 CRC_OCM_A1 "0F0F0000000000FFh";
BA_ "FlexKomSigStartPos" SG_ 601 CRC_OCM_A1 7;
BA_ "FlexKomSigName" SG_ 601 CRC_OCM_A1 "OC_P_Stat";
BA_ "FlexKomSigLaenge" SG_ 601 CRC_OCM_A1 64;
BA_ "FlexKomSID" SG_ 601 CRC_OCM_A1 1586;
BA_ "FlexKomIsMotorola" SG_ 601 CRC_OCM_A1 1;
BA_ "FlexKomComment" SG_ 601 CRC_OCM_A1 "Passenger occupant classification system status";
BA_ "RID" SG_ 605 PwrTop_Cmd "5074";
BA_ "GenSigTimeout_IC" SG_ 605 PwrTop_Cmd 10500;
BA_ "GenSigSNA" SG_ 605 PwrTop_Cmd "3h";
BA_ "GenSigSendType" SG_ 605 PwrTop_Cmd 5;
BA_ "GenSigCycleTime" SG_ 605 PwrTop_Cmd 1000;
BA_ "FlexKomSigStartValue" SG_ 605 PwrTop_Cmd "00h";
BA_ "FlexKomSigStartPos" SG_ 605 PwrTop_Cmd 1;
BA_ "FlexKomSigName" SG_ 605 PwrTop_Cmd "PwrTop_Cmd";
BA_ "FlexKomSigLaenge" SG_ 605 PwrTop_Cmd 2;
BA_ "FlexKomSID" SG_ 605 PwrTop_Cmd 2634;
BA_ "FlexKomIsMotorola" SG_ 605 PwrTop_Cmd 1;
BA_ "FlexKomComment" SG_ 605 PwrTop_Cmd "Power Top Switch Status";
BA_ "RID" SG_ 605 PwrTop_Pos "5075";
BA_ "GenSigTimeout_IC" SG_ 605 PwrTop_Pos 10500;
BA_ "GenSigSNA" SG_ 605 PwrTop_Pos "0h";
BA_ "GenSigSendType" SG_ 605 PwrTop_Pos 5;
BA_ "GenSigCycleTime" SG_ 605 PwrTop_Pos 1000;
BA_ "FlexKomSigStartValue" SG_ 605 PwrTop_Pos "00h";
BA_ "FlexKomSigStartPos" SG_ 605 PwrTop_Pos 3;
BA_ "FlexKomSigName" SG_ 605 PwrTop_Pos "PwrTop_Pos";
BA_ "FlexKomSigLaenge" SG_ 605 PwrTop_Pos 2;
BA_ "FlexKomSID" SG_ 605 PwrTop_Pos 2635;
BA_ "FlexKomIsMotorola" SG_ 605 PwrTop_Pos 1;
BA_ "FlexKomComment" SG_ 605 PwrTop_Pos "Power Top Roof Position";
BA_ "RID" SG_ 605 AxleLckrSEL_SW "5152";
BA_ "GenSigSNA" SG_ 605 AxleLckrSEL_SW "3h";
BA_ "GenSigSendType" SG_ 605 AxleLckrSEL_SW 5;
BA_ "GenSigCycleTime" SG_ 605 AxleLckrSEL_SW 1000;
BA_ "FlexKomSigStartValue" SG_ 605 AxleLckrSEL_SW "00h";
BA_ "FlexKomSigStartPos" SG_ 605 AxleLckrSEL_SW 5;
BA_ "FlexKomSigName" SG_ 605 AxleLckrSEL_SW "AxleLckrSEL_SW";
BA_ "FlexKomSigLaenge" SG_ 605 AxleLckrSEL_SW 2;
BA_ "FlexKomSID" SG_ 605 AxleLckrSEL_SW 2640;
BA_ "FlexKomIsMotorola" SG_ 605 AxleLckrSEL_SW 1;
BA_ "FlexKomComment" SG_ 605 AxleLckrSEL_SW "Axle locker selection switch";
BA_ "RID" SG_ 605 AxleLckrOFF_SW "5153";
BA_ "GenSigSNA" SG_ 605 AxleLckrOFF_SW "3h";
BA_ "GenSigSendType" SG_ 605 AxleLckrOFF_SW 5;
BA_ "GenSigCycleTime" SG_ 605 AxleLckrOFF_SW 1000;
BA_ "FlexKomSigStartValue" SG_ 605 AxleLckrOFF_SW "00h";
BA_ "FlexKomSigStartPos" SG_ 605 AxleLckrOFF_SW 7;
BA_ "FlexKomSigName" SG_ 605 AxleLckrOFF_SW "AxleLckrOFF_SW";
BA_ "FlexKomSigLaenge" SG_ 605 AxleLckrOFF_SW 2;
BA_ "FlexKomSID" SG_ 605 AxleLckrOFF_SW 2641;
BA_ "FlexKomIsMotorola" SG_ 605 AxleLckrOFF_SW 1;
BA_ "FlexKomComment" SG_ 605 AxleLckrOFF_SW "Axle locker deactivation switch";
BA_ "RID" SG_ 605 PwrTop_Stat "5072";
BA_ "GenSigTimeout_IC" SG_ 605 PwrTop_Stat 10500;
BA_ "GenSigSNA" SG_ 605 PwrTop_Stat "7h";
BA_ "GenSigSendType" SG_ 605 PwrTop_Stat 5;
BA_ "GenSigCycleTime" SG_ 605 PwrTop_Stat 1000;
BA_ "FlexKomSigStartValue" SG_ 605 PwrTop_Stat "00h";
BA_ "FlexKomSigStartPos" SG_ 605 PwrTop_Stat 12;
BA_ "FlexKomSigName" SG_ 605 PwrTop_Stat "PwrTop_Stat";
BA_ "FlexKomSigLaenge" SG_ 605 PwrTop_Stat 3;
BA_ "FlexKomSID" SG_ 605 PwrTop_Stat 2636;
BA_ "FlexKomIsMotorola" SG_ 605 PwrTop_Stat 1;
BA_ "FlexKomComment" SG_ 605 PwrTop_Stat "Power Top Operation Status";
BA_ "RID" SG_ 605 PwrTop_Cal "5073";
BA_ "GenSigTimeout_IC" SG_ 605 PwrTop_Cal 10500;
BA_ "GenSigSNA" SG_ 605 PwrTop_Cal "7h";
BA_ "GenSigSendType" SG_ 605 PwrTop_Cal 5;
BA_ "GenSigCycleTime" SG_ 605 PwrTop_Cal 1000;
BA_ "FlexKomSigStartValue" SG_ 605 PwrTop_Cal "00h";
BA_ "FlexKomSigStartPos" SG_ 605 PwrTop_Cal 15;
BA_ "FlexKomSigName" SG_ 605 PwrTop_Cal "PwrTop_Cal";
BA_ "FlexKomSigLaenge" SG_ 605 PwrTop_Cal 3;
BA_ "FlexKomSID" SG_ 605 PwrTop_Cal 2633;
BA_ "FlexKomIsMotorola" SG_ 605 PwrTop_Cal 1;
BA_ "FlexKomComment" SG_ 605 PwrTop_Cal "Power Top Calibration Status";
BA_ "RID" SG_ 605 TGW_AUD_MD2_CAB_DR "6336";
BA_ "GenSigTimeout_IC" SG_ 605 TGW_AUD_MD2_CAB_DR 10500;
BA_ "GenSigSNA" SG_ 605 TGW_AUD_MD2_CAB_DR "3Fh";
BA_ "GenSigSendType" SG_ 605 TGW_AUD_MD2_CAB_DR 5;
BA_ "GenSigCycleTime" SG_ 605 TGW_AUD_MD2_CAB_DR 1000;
BA_ "FlexKomSigStartValue" SG_ 605 TGW_AUD_MD2_CAB_DR "00h";
BA_ "FlexKomSigStartPos" SG_ 605 TGW_AUD_MD2_CAB_DR 29;
BA_ "FlexKomSigName" SG_ 605 TGW_AUD_MD2_CAB_DR "TGW_AUD_MD2_CAB_DR";
BA_ "FlexKomSigLaenge" SG_ 605 TGW_AUD_MD2_CAB_DR 6;
BA_ "FlexKomSID" SG_ 605 TGW_AUD_MD2_CAB_DR 2717;
BA_ "FlexKomIsMotorola" SG_ 605 TGW_AUD_MD2_CAB_DR 1;
BA_ "FlexKomComment" SG_ 605 TGW_AUD_MD2_CAB_DR "TGW additional audio modes for Cabin/Driver";
BA_ "RID" SG_ 605 Phone_Popup_setting_active "6384";
BA_ "GenSigTimeout_IC" SG_ 605 Phone_Popup_setting_active 10500;
BA_ "GenSigSNA" SG_ 605 Phone_Popup_setting_active "0h";
BA_ "GenSigSendType" SG_ 605 Phone_Popup_setting_active 5;
BA_ "GenSigCycleTime" SG_ 605 Phone_Popup_setting_active 1000;
BA_ "FlexKomSigStartValue" SG_ 605 Phone_Popup_setting_active "00h";
BA_ "FlexKomSigStartPos" SG_ 605 Phone_Popup_setting_active 55;
BA_ "FlexKomSigName" SG_ 605 Phone_Popup_setting_active "Phone_Popup_setting_active";
BA_ "FlexKomSigLaenge" SG_ 605 Phone_Popup_setting_active 1;
BA_ "FlexKomSID" SG_ 605 Phone_Popup_setting_active 2745;
BA_ "FlexKomIsMotorola" SG_ 605 Phone_Popup_setting_active 1;
BA_ "FlexKomComment" SG_ 605 Phone_Popup_setting_active "Phone call status popup active or not, Active=1";
BA_ "GenSigSNA" SG_ 607 CBC_Reset_Flag "3h";
BA_ "GenSigSendType" SG_ 607 CBC_Reset_Flag 5;
BA_ "GenSigCycleTime" SG_ 607 CBC_Reset_Flag 1000;
BA_ "FlexKomSigStartValue" SG_ 607 CBC_Reset_Flag "00h";
BA_ "FlexKomSigStartPos" SG_ 607 CBC_Reset_Flag 17;
BA_ "FlexKomSigName" SG_ 607 CBC_Reset_Flag "CBC_Reset_Flag";
BA_ "FlexKomSigLaenge" SG_ 607 CBC_Reset_Flag 2;
BA_ "FlexKomSID" SG_ 607 CBC_Reset_Flag 2530;
BA_ "FlexKomIsMotorola" SG_ 607 CBC_Reset_Flag 1;
BA_ "FlexKomComment" SG_ 607 CBC_Reset_Flag "CBC reset flag";
BA_ "GenSigTimeout_IC" SG_ 607 HRD_TOP_OFF 10500;
BA_ "GenSigSNA" SG_ 607 HRD_TOP_OFF "0h";
BA_ "GenSigSendType" SG_ 607 HRD_TOP_OFF 5;
BA_ "GenSigCycleTime" SG_ 607 HRD_TOP_OFF 1000;
BA_ "FlexKomSigStartValue" SG_ 607 HRD_TOP_OFF "00h";
BA_ "FlexKomSigStartPos" SG_ 607 HRD_TOP_OFF 24;
BA_ "FlexKomSigName" SG_ 607 HRD_TOP_OFF "HRD_TOP_OFF";
BA_ "FlexKomSigLaenge" SG_ 607 HRD_TOP_OFF 1;
BA_ "FlexKomSID" SG_ 607 HRD_TOP_OFF 2637;
BA_ "FlexKomIsMotorola" SG_ 607 HRD_TOP_OFF 1;
BA_ "FlexKomComment" SG_ 607 HRD_TOP_OFF "Removable hard top is off";
BA_ "GenSigTimeout_IC" SG_ 607 GlobDrvMdSts 10500;
BA_ "GenSigSNA" SG_ 607 GlobDrvMdSts "1Fh";
BA_ "GenSigSendType" SG_ 607 GlobDrvMdSts 5;
BA_ "GenSigCycleTime" SG_ 607 GlobDrvMdSts 1000;
BA_ "FlexKomSigStartValue" SG_ 607 GlobDrvMdSts "00h";
BA_ "FlexKomSigStartPos" SG_ 607 GlobDrvMdSts 36;
BA_ "FlexKomSigName" SG_ 607 GlobDrvMdSts "GlobDrvMdSts";
BA_ "FlexKomSigLaenge" SG_ 607 GlobDrvMdSts 5;
BA_ "FlexKomSID" SG_ 607 GlobDrvMdSts 2392;
BA_ "FlexKomIsMotorola" SG_ 607 GlobDrvMdSts 1;
BA_ "FlexKomComment" SG_ 607 GlobDrvMdSts "Global drive mode status";
BA_ "GenSigTimeout_IC" SG_ 607 ESLLockFailSts_BCM 10500;
BA_ "GenSigSNA" SG_ 607 ESLLockFailSts_BCM "0h";
BA_ "GenSigSendType" SG_ 607 ESLLockFailSts_BCM 5;
BA_ "GenSigCycleTime" SG_ 607 ESLLockFailSts_BCM 1000;
BA_ "FlexKomSigStartValue" SG_ 607 ESLLockFailSts_BCM "00h";
BA_ "FlexKomSigStartPos" SG_ 607 ESLLockFailSts_BCM 40;
BA_ "FlexKomSigName" SG_ 607 ESLLockFailSts_BCM "ESLLockFailSts_BCM";
BA_ "FlexKomSigLaenge" SG_ 607 ESLLockFailSts_BCM 1;
BA_ "FlexKomSID" SG_ 607 ESLLockFailSts_BCM 2369;
BA_ "FlexKomIsMotorola" SG_ 607 ESLLockFailSts_BCM 1;
BA_ "FlexKomComment" SG_ 607 ESLLockFailSts_BCM "Display info on failed lock; Failed = [1]";
BA_ "GenSigTimeout_IC" SG_ 607 ESLUnlockFailSts_BCM 10500;
BA_ "GenSigSNA" SG_ 607 ESLUnlockFailSts_BCM "0h";
BA_ "GenSigSendType" SG_ 607 ESLUnlockFailSts_BCM 5;
BA_ "GenSigCycleTime" SG_ 607 ESLUnlockFailSts_BCM 1000;
BA_ "FlexKomSigStartValue" SG_ 607 ESLUnlockFailSts_BCM "00h";
BA_ "FlexKomSigStartPos" SG_ 607 ESLUnlockFailSts_BCM 41;
BA_ "FlexKomSigName" SG_ 607 ESLUnlockFailSts_BCM "ESLUnlockFailSts_BCM";
BA_ "FlexKomSigLaenge" SG_ 607 ESLUnlockFailSts_BCM 1;
BA_ "FlexKomSID" SG_ 607 ESLUnlockFailSts_BCM 2370;
BA_ "FlexKomIsMotorola" SG_ 607 ESLUnlockFailSts_BCM 1;
BA_ "FlexKomComment" SG_ 607 ESLUnlockFailSts_BCM "Display info on failed unlock; Failed = [1]";
BA_ "GenSigSNA" SG_ 607 HAZARD_STATUS "0h";
BA_ "GenSigSendType" SG_ 607 HAZARD_STATUS 5;
BA_ "GenSigCycleTime" SG_ 607 HAZARD_STATUS 1000;
BA_ "FlexKomSigStartValue" SG_ 607 HAZARD_STATUS "00h";
BA_ "FlexKomSigStartPos" SG_ 607 HAZARD_STATUS 47;
BA_ "FlexKomSigName" SG_ 607 HAZARD_STATUS "HAZARD_STATUS";
BA_ "FlexKomSigLaenge" SG_ 607 HAZARD_STATUS 1;
BA_ "FlexKomSID" SG_ 607 HAZARD_STATUS 1958;
BA_ "FlexKomIsMotorola" SG_ 607 HAZARD_STATUS 1;
BA_ "FlexKomComment" SG_ 607 HAZARD_STATUS "Hazard lamps; active = [1]";
BA_ "GenSigTimeout_TBM" SG_ 607 EngineOffTimer 10500;
BA_ "GenSigStartValue" SG_ 607 EngineOffTimer 4095;
BA_ "GenSigSNA" SG_ 607 EngineOffTimer "FFFh";
BA_ "GenSigCycleTime" SG_ 607 EngineOffTimer 1000;
BA_ "FlexKomSigStartValue" SG_ 607 EngineOffTimer "0FFFh";
BA_ "FlexKomSigStartPos" SG_ 607 EngineOffTimer 55;
BA_ "FlexKomSigName" SG_ 607 EngineOffTimer "EngineOffTimer";
BA_ "FlexKomSigLaenge" SG_ 607 EngineOffTimer 16;
BA_ "FlexKomSID" SG_ 607 EngineOffTimer 1906;
BA_ "FlexKomIsMotorola" SG_ 607 EngineOffTimer 1;
BA_ "FlexKomComment" SG_ 607 EngineOffTimer "Engine off timer - engine off ignition NOT lock.";
BA_ "GenSigTimeout_IC" SG_ 607 MoveWheelSts 10500;
BA_ "GenSigSNA" SG_ 607 MoveWheelSts "0h";
BA_ "GenSigSendType" SG_ 607 MoveWheelSts 5;
BA_ "GenSigCycleTime" SG_ 607 MoveWheelSts 1000;
BA_ "FlexKomSigStartValue" SG_ 607 MoveWheelSts "00h";
BA_ "FlexKomSigStartPos" SG_ 607 MoveWheelSts 52;
BA_ "FlexKomSigName" SG_ 607 MoveWheelSts "MoveWheelSts";
BA_ "FlexKomSigLaenge" SG_ 607 MoveWheelSts 1;
BA_ "FlexKomSID" SG_ 607 MoveWheelSts 2371;
BA_ "FlexKomIsMotorola" SG_ 607 MoveWheelSts 1;
BA_ "FlexKomComment" SG_ 607 MoveWheelSts "Display message to move steering wheel; Active = [";
BA_ "GenSigSNA" SG_ 607 PNC_ALM_ACT "0h";
BA_ "GenSigSendType" SG_ 607 PNC_ALM_ACT 5;
BA_ "GenSigCycleTime" SG_ 607 PNC_ALM_ACT 1000;
BA_ "FlexKomSigStartValue" SG_ 607 PNC_ALM_ACT "00h";
BA_ "FlexKomSigStartPos" SG_ 607 PNC_ALM_ACT 55;
BA_ "FlexKomSigName" SG_ 607 PNC_ALM_ACT "PNC_ALM_ACT";
BA_ "FlexKomSigLaenge" SG_ 607 PNC_ALM_ACT 1;
BA_ "FlexKomSID" SG_ 607 PNC_ALM_ACT 756;
BA_ "FlexKomIsMotorola" SG_ 607 PNC_ALM_ACT 1;
BA_ "FlexKomComment" SG_ 607 PNC_ALM_ACT "Panic alarm active; [1] = True";
BA_ "GenSigSNA" SG_ 607 HL_MD "7h";
BA_ "GenSigSendType" SG_ 607 HL_MD 5;
BA_ "GenSigCycleTime" SG_ 607 HL_MD 1000;
BA_ "FlexKomSigStartValue" SG_ 607 HL_MD "00h";
BA_ "FlexKomSigStartPos" SG_ 607 HL_MD 27;
BA_ "FlexKomSigName" SG_ 607 HL_MD "HL_MD";
BA_ "FlexKomSigLaenge" SG_ 607 HL_MD 3;
BA_ "FlexKomSID" SG_ 607 HL_MD 3285;
BA_ "FlexKomIsMotorola" SG_ 607 HL_MD 1;
BA_ "RID" SG_ 609 IBS_Q_received "1817";
BA_ "GenSigStartValue" SG_ 609 IBS_Q_received 65535;
BA_ "GenSigSNA" SG_ 609 IBS_Q_received "FFFFh";
BA_ "GenSigCycleTime" SG_ 609 IBS_Q_received 1000;
BA_ "FlexKomSigStartValue" SG_ 609 IBS_Q_received "FFFFFFFF00000000h";
BA_ "FlexKomSigStartPos" SG_ 609 IBS_Q_received 7;
BA_ "FlexKomSigName" SG_ 609 IBS_Q_received "GW_IBS_DataPkt";
BA_ "FlexKomSigLaenge" SG_ 609 IBS_Q_received 64;
BA_ "FlexKomSID" SG_ 609 IBS_Q_received 1855;
BA_ "FlexKomIsMotorola" SG_ 609 IBS_Q_received 1;
BA_ "FlexKomComment" SG_ 609 IBS_Q_received "LIN to CAN C IBS data";
BA_ "RID" SG_ 609 IBS_Q_released "1815";
BA_ "GenSigStartValue" SG_ 609 IBS_Q_released 65535;
BA_ "GenSigSNA" SG_ 609 IBS_Q_released "FFFFh";
BA_ "GenSigCycleTime" SG_ 609 IBS_Q_released 1000;
BA_ "FlexKomSigStartValue" SG_ 609 IBS_Q_released "FFFFFFFF00000000h";
BA_ "FlexKomSigStartPos" SG_ 609 IBS_Q_released 7;
BA_ "FlexKomSigName" SG_ 609 IBS_Q_released "GW_IBS_DataPkt";
BA_ "FlexKomSigLaenge" SG_ 609 IBS_Q_released 64;
BA_ "FlexKomSID" SG_ 609 IBS_Q_released 1855;
BA_ "FlexKomIsMotorola" SG_ 609 IBS_Q_released 1;
BA_ "FlexKomComment" SG_ 609 IBS_Q_released "LIN to CAN C IBS data";
BA_ "RID" SG_ 609 IBS_Tm_Lst_Reset_Sec "1826";
BA_ "GenSigSNA" SG_ 609 IBS_Tm_Lst_Reset_Sec "FFFFh";
BA_ "GenSigCycleTime" SG_ 609 IBS_Tm_Lst_Reset_Sec 1000;
BA_ "FlexKomSigStartValue" SG_ 609 IBS_Tm_Lst_Reset_Sec "FFFFFFFF00000000h";
BA_ "FlexKomSigStartPos" SG_ 609 IBS_Tm_Lst_Reset_Sec 7;
BA_ "FlexKomSigName" SG_ 609 IBS_Tm_Lst_Reset_Sec "GW_IBS_DataPkt";
BA_ "FlexKomSigLaenge" SG_ 609 IBS_Tm_Lst_Reset_Sec 64;
BA_ "FlexKomSID" SG_ 609 IBS_Tm_Lst_Reset_Sec 1855;
BA_ "FlexKomIsMotorola" SG_ 609 IBS_Tm_Lst_Reset_Sec 1;
BA_ "FlexKomComment" SG_ 609 IBS_Tm_Lst_Reset_Sec "LIN to CAN C IBS data";
BA_ "RID" SG_ 609 IBS_Tm_Lst_Reset_Days "1807";
BA_ "GenSigSNA" SG_ 609 IBS_Tm_Lst_Reset_Days "FFFh";
BA_ "GenSigCycleTime" SG_ 609 IBS_Tm_Lst_Reset_Days 1000;
BA_ "FlexKomSigStartValue" SG_ 609 IBS_Tm_Lst_Reset_Days "FFFFFFFF00000000h";
BA_ "FlexKomSigStartPos" SG_ 609 IBS_Tm_Lst_Reset_Days 7;
BA_ "FlexKomSigName" SG_ 609 IBS_Tm_Lst_Reset_Days "GW_IBS_DataPkt";
BA_ "FlexKomSigLaenge" SG_ 609 IBS_Tm_Lst_Reset_Days 64;
BA_ "FlexKomSID" SG_ 609 IBS_Tm_Lst_Reset_Days 1855;
BA_ "FlexKomIsMotorola" SG_ 609 IBS_Tm_Lst_Reset_Days 1;
BA_ "FlexKomComment" SG_ 609 IBS_Tm_Lst_Reset_Days "LIN to CAN C IBS data";
BA_ "RID" SG_ 611 EstTimeofChrg_Lv2 "6507";
BA_ "GenSigTimeout_IC" SG_ 611 EstTimeofChrg_Lv2 10500;
BA_ "GenSigTimeout_CBC" SG_ 611 EstTimeofChrg_Lv2 10500;
BA_ "GenSigSNA" SG_ 611 EstTimeofChrg_Lv2 "7FFh";
BA_ "GenSigSendType" SG_ 611 EstTimeofChrg_Lv2 5;
BA_ "GenSigCycleTime" SG_ 611 EstTimeofChrg_Lv2 1000;
BA_ "FlexKomSigStartValue" SG_ 611 EstTimeofChrg_Lv2 "0000000000000000h";
BA_ "FlexKomSigStartPos" SG_ 611 EstTimeofChrg_Lv2 7;
BA_ "FlexKomSigName" SG_ 611 EstTimeofChrg_Lv2 "HCP_1000";
BA_ "FlexKomSigLaenge" SG_ 611 EstTimeofChrg_Lv2 64;
BA_ "FlexKomSID" SG_ 611 EstTimeofChrg_Lv2 2373;
BA_ "FlexKomIsMotorola" SG_ 611 EstTimeofChrg_Lv2 1;
BA_ "FlexKomComment" SG_ 611 EstTimeofChrg_Lv2 "HCP 1000ms packet";
BA_ "GenSigTimeout_IC" SG_ 611 ChrgSysFault 10500;
BA_ "GenSigSNA" SG_ 611 ChrgSysFault "0h";
BA_ "GenSigSendType" SG_ 611 ChrgSysFault 5;
BA_ "GenSigCycleTime" SG_ 611 ChrgSysFault 1000;
BA_ "FlexKomSigStartValue" SG_ 611 ChrgSysFault "0000000000000000h";
BA_ "FlexKomSigStartPos" SG_ 611 ChrgSysFault 7;
BA_ "FlexKomSigName" SG_ 611 ChrgSysFault "HCP_1000";
BA_ "FlexKomSigLaenge" SG_ 611 ChrgSysFault 64;
BA_ "FlexKomSID" SG_ 611 ChrgSysFault 2373;
BA_ "FlexKomIsMotorola" SG_ 611 ChrgSysFault 1;
BA_ "FlexKomComment" SG_ 611 ChrgSysFault "HCP 1000ms packet";
BA_ "RID" SG_ 611 ChargingLevel "6518";
BA_ "GenSigTimeout_IC" SG_ 611 ChargingLevel 10500;
BA_ "GenSigTimeout_CBC" SG_ 611 ChargingLevel 10500;
BA_ "GenSigSNA" SG_ 611 ChargingLevel "Fh";
BA_ "GenSigSendType" SG_ 611 ChargingLevel 5;
BA_ "GenSigCycleTime" SG_ 611 ChargingLevel 1000;
BA_ "FlexKomSigStartValue" SG_ 611 ChargingLevel "0000000000000000h";
BA_ "FlexKomSigStartPos" SG_ 611 ChargingLevel 7;
BA_ "FlexKomSigName" SG_ 611 ChargingLevel "HCP_1000";
BA_ "FlexKomSigLaenge" SG_ 611 ChargingLevel 64;
BA_ "FlexKomSID" SG_ 611 ChargingLevel 2373;
BA_ "FlexKomIsMotorola" SG_ 611 ChargingLevel 1;
BA_ "FlexKomComment" SG_ 611 ChargingLevel "HCP 1000ms packet";
BA_ "RID" SG_ 611 EstTimeofChrg_Lv1 "6508";
BA_ "GenSigTimeout_IC" SG_ 611 EstTimeofChrg_Lv1 10500;
BA_ "GenSigTimeout_CBC" SG_ 611 EstTimeofChrg_Lv1 10500;
BA_ "GenSigSNA" SG_ 611 EstTimeofChrg_Lv1 "1FFFh";
BA_ "GenSigSendType" SG_ 611 EstTimeofChrg_Lv1 5;
BA_ "GenSigCycleTime" SG_ 611 EstTimeofChrg_Lv1 1000;
BA_ "FlexKomSigStartValue" SG_ 611 EstTimeofChrg_Lv1 "0000000000000000h";
BA_ "FlexKomSigStartPos" SG_ 611 EstTimeofChrg_Lv1 7;
BA_ "FlexKomSigName" SG_ 611 EstTimeofChrg_Lv1 "HCP_1000";
BA_ "FlexKomSigLaenge" SG_ 611 EstTimeofChrg_Lv1 64;
BA_ "FlexKomSID" SG_ 611 EstTimeofChrg_Lv1 2373;
BA_ "FlexKomIsMotorola" SG_ 611 EstTimeofChrg_Lv1 1;
BA_ "FlexKomComment" SG_ 611 EstTimeofChrg_Lv1 "HCP 1000ms packet";
BA_ "GenSigTimeout_IC" SG_ 611 MIL_OnRq_BPCM 10500;
BA_ "GenSigSNA" SG_ 611 MIL_OnRq_BPCM "0h";
BA_ "GenSigSendType" SG_ 611 MIL_OnRq_BPCM 5;
BA_ "GenSigCycleTime" SG_ 611 MIL_OnRq_BPCM 1000;
BA_ "FlexKomSigStartValue" SG_ 611 MIL_OnRq_BPCM "0000000000000000h";
BA_ "FlexKomSigStartPos" SG_ 611 MIL_OnRq_BPCM 7;
BA_ "FlexKomSigName" SG_ 611 MIL_OnRq_BPCM "HCP_1000";
BA_ "FlexKomSigLaenge" SG_ 611 MIL_OnRq_BPCM 64;
BA_ "FlexKomSID" SG_ 611 MIL_OnRq_BPCM 2373;
BA_ "FlexKomIsMotorola" SG_ 611 MIL_OnRq_BPCM 1;
BA_ "FlexKomComment" SG_ 611 MIL_OnRq_BPCM "HCP 1000ms packet";
BA_ "GenSigTimeout_IC" SG_ 611 DriveReady 10500;
BA_ "GenSigSNA" SG_ 611 DriveReady "0h";
BA_ "GenSigSendType" SG_ 611 DriveReady 5;
BA_ "GenSigCycleTime" SG_ 611 DriveReady 1000;
BA_ "FlexKomSigStartValue" SG_ 611 DriveReady "0000000000000000h";
BA_ "FlexKomSigStartPos" SG_ 611 DriveReady 7;
BA_ "FlexKomSigName" SG_ 611 DriveReady "HCP_1000";
BA_ "FlexKomSigLaenge" SG_ 611 DriveReady 64;
BA_ "FlexKomSID" SG_ 611 DriveReady 2373;
BA_ "FlexKomIsMotorola" SG_ 611 DriveReady 1;
BA_ "FlexKomComment" SG_ 611 DriveReady "HCP 1000ms packet";
BA_ "RID" SG_ 611 PrplsnSysAtv "3065";
BA_ "GenSigTimeout_IC" SG_ 611 PrplsnSysAtv 10500;
BA_ "GenSigSNA" SG_ 611 PrplsnSysAtv "0h";
BA_ "GenSigSendType" SG_ 611 PrplsnSysAtv 5;
BA_ "GenSigCycleTime" SG_ 611 PrplsnSysAtv 1000;
BA_ "FlexKomSigStartValue" SG_ 611 PrplsnSysAtv "0000000000000000h";
BA_ "FlexKomSigStartPos" SG_ 611 PrplsnSysAtv 7;
BA_ "FlexKomSigName" SG_ 611 PrplsnSysAtv "HCP_1000";
BA_ "FlexKomSigLaenge" SG_ 611 PrplsnSysAtv 64;
BA_ "FlexKomSID" SG_ 611 PrplsnSysAtv 2373;
BA_ "FlexKomIsMotorola" SG_ 611 PrplsnSysAtv 1;
BA_ "FlexKomComment" SG_ 611 PrplsnSysAtv "HCP 1000ms packet";
BA_ "GenSigSNA" SG_ 611 HtrCoreInletTemp "FFh";
BA_ "GenSigSendType" SG_ 611 HtrCoreInletTemp 5;
BA_ "GenSigCycleTime" SG_ 611 HtrCoreInletTemp 1000;
BA_ "FlexKomSigStartValue" SG_ 611 HtrCoreInletTemp "0000000000000000h";
BA_ "FlexKomSigStartPos" SG_ 611 HtrCoreInletTemp 7;
BA_ "FlexKomSigName" SG_ 611 HtrCoreInletTemp "HCP_1000";
BA_ "FlexKomSigLaenge" SG_ 611 HtrCoreInletTemp 64;
BA_ "FlexKomSID" SG_ 611 HtrCoreInletTemp 2373;
BA_ "FlexKomIsMotorola" SG_ 611 HtrCoreInletTemp 1;
BA_ "FlexKomComment" SG_ 611 HtrCoreInletTemp "HCP 1000ms packet";
BA_ "RID" SG_ 611 ChargingSysSts "6523";
BA_ "GenSigTimeout_IC" SG_ 611 ChargingSysSts 10500;
BA_ "GenSigTimeout_CBC" SG_ 611 ChargingSysSts 10500;
BA_ "GenSigSNA" SG_ 611 ChargingSysSts "7h";
BA_ "GenSigSendType" SG_ 611 ChargingSysSts 5;
BA_ "GenSigCycleTime" SG_ 611 ChargingSysSts 1000;
BA_ "FlexKomSigStartValue" SG_ 611 ChargingSysSts "0000000000000000h";
BA_ "FlexKomSigStartPos" SG_ 611 ChargingSysSts 7;
BA_ "FlexKomSigName" SG_ 611 ChargingSysSts "HCP_1000";
BA_ "FlexKomSigLaenge" SG_ 611 ChargingSysSts 64;
BA_ "FlexKomSID" SG_ 611 ChargingSysSts 2373;
BA_ "FlexKomIsMotorola" SG_ 611 ChargingSysSts 1;
BA_ "FlexKomComment" SG_ 611 ChargingSysSts "HCP 1000ms packet";
BA_ "RID" SG_ 611 CompStat "3581 3587";
BA_ "GenSigTimeout_CBC" SG_ 611 CompStat 10500;
BA_ "GenSigSNA" SG_ 611 CompStat "Fh";
BA_ "GenSigSendType" SG_ 611 CompStat 5;
BA_ "GenSigCycleTime" SG_ 611 CompStat 1000;
BA_ "FlexKomSigStartValue" SG_ 611 CompStat "0000000000000000h";
BA_ "FlexKomSigStartPos" SG_ 611 CompStat 7;
BA_ "FlexKomSigName" SG_ 611 CompStat "HCP_1000";
BA_ "FlexKomSigLaenge" SG_ 611 CompStat 64;
BA_ "FlexKomSID" SG_ 611 CompStat 2373;
BA_ "FlexKomIsMotorola" SG_ 611 CompStat 1;
BA_ "FlexKomComment" SG_ 611 CompStat "HCP 1000ms packet";
BA_ "RID" SG_ 611 CabinPreCondReqStat "2868";
BA_ "GenSigTimeout_CBC" SG_ 611 CabinPreCondReqStat 10500;
BA_ "GenSigSNA" SG_ 611 CabinPreCondReqStat "Fh";
BA_ "GenSigSendType" SG_ 611 CabinPreCondReqStat 5;
BA_ "GenSigCycleTime" SG_ 611 CabinPreCondReqStat 1000;
BA_ "FlexKomSigStartValue" SG_ 611 CabinPreCondReqStat "0000000000000000h";
BA_ "FlexKomSigStartPos" SG_ 611 CabinPreCondReqStat 7;
BA_ "FlexKomSigName" SG_ 611 CabinPreCondReqStat "HCP_1000";
BA_ "FlexKomSigLaenge" SG_ 611 CabinPreCondReqStat 64;
BA_ "FlexKomSID" SG_ 611 CabinPreCondReqStat 2373;
BA_ "FlexKomIsMotorola" SG_ 611 CabinPreCondReqStat 1;
BA_ "FlexKomComment" SG_ 611 CabinPreCondReqStat "HCP 1000ms packet";
BA_ "GenSigTimeout_IC" SG_ 611 HVBatCntctrStat 10500;
BA_ "GenSigSNA" SG_ 611 HVBatCntctrStat "7h";
BA_ "GenSigSendType" SG_ 611 HVBatCntctrStat 5;
BA_ "GenSigCycleTime" SG_ 611 HVBatCntctrStat 1000;
BA_ "FlexKomSigStartValue" SG_ 611 HVBatCntctrStat "0000000000000000h";
BA_ "FlexKomSigStartPos" SG_ 611 HVBatCntctrStat 7;
BA_ "FlexKomSigName" SG_ 611 HVBatCntctrStat "HCP_1000";
BA_ "FlexKomSigLaenge" SG_ 611 HVBatCntctrStat 64;
BA_ "FlexKomSID" SG_ 611 HVBatCntctrStat 2373;
BA_ "FlexKomIsMotorola" SG_ 611 HVBatCntctrStat 1;
BA_ "FlexKomComment" SG_ 611 HVBatCntctrStat "HCP 1000ms packet";
BA_ "GenSigSNA" SG_ 611 V2L_DischargingSysStat "7h";
BA_ "GenSigSendType" SG_ 611 V2L_DischargingSysStat 5;
BA_ "GenSigCycleTime" SG_ 611 V2L_DischargingSysStat 1000;
BA_ "FlexKomSigStartValue" SG_ 611 V2L_DischargingSysStat "0000000000000000h";
BA_ "FlexKomSigStartPos" SG_ 611 V2L_DischargingSysStat 7;
BA_ "FlexKomSigName" SG_ 611 V2L_DischargingSysStat "HCP_1000";
BA_ "FlexKomSigLaenge" SG_ 611 V2L_DischargingSysStat 64;
BA_ "FlexKomSID" SG_ 611 V2L_DischargingSysStat 2373;
BA_ "FlexKomIsMotorola" SG_ 611 V2L_DischargingSysStat 1;
BA_ "FlexKomComment" SG_ 611 V2L_DischargingSysStat "HCP 1000ms packet";
BA_ "GenSigTimeout_IC" SG_ 613 DrvMd_PopUpRqst 10500;
BA_ "GenSigSNA" SG_ 613 DrvMd_PopUpRqst "FFh";
BA_ "GenSigSendType" SG_ 613 DrvMd_PopUpRqst 5;
BA_ "GenSigCycleTime" SG_ 613 DrvMd_PopUpRqst 1000;
BA_ "FlexKomSigStartValue" SG_ 613 DrvMd_PopUpRqst "00000000003F06FFh";
BA_ "FlexKomSigStartPos" SG_ 613 DrvMd_PopUpRqst 7;
BA_ "FlexKomSigName" SG_ 613 DrvMd_PopUpRqst "CBC_PT10_Pkt";
BA_ "FlexKomSigLaenge" SG_ 613 DrvMd_PopUpRqst 64;
BA_ "FlexKomSID" SG_ 613 DrvMd_PopUpRqst 2499;
BA_ "FlexKomIsMotorola" SG_ 613 DrvMd_PopUpRqst 1;
BA_ "FlexKomComment" SG_ 613 DrvMd_PopUpRqst "CBC message 10 packet";
BA_ "GenSigStartValue" SG_ 613 DriverDoorOnOffSts 3;
BA_ "GenSigSNA" SG_ 613 DriverDoorOnOffSts "3h";
BA_ "GenSigSendType" SG_ 613 DriverDoorOnOffSts 5;
BA_ "GenSigCycleTime" SG_ 613 DriverDoorOnOffSts 1000;
BA_ "FlexKomSigStartValue" SG_ 613 DriverDoorOnOffSts "00000000003F06FFh";
BA_ "FlexKomSigStartPos" SG_ 613 DriverDoorOnOffSts 7;
BA_ "FlexKomSigName" SG_ 613 DriverDoorOnOffSts "CBC_PT10_Pkt";
BA_ "FlexKomSigLaenge" SG_ 613 DriverDoorOnOffSts 64;
BA_ "FlexKomSID" SG_ 613 DriverDoorOnOffSts 2499;
BA_ "FlexKomIsMotorola" SG_ 613 DriverDoorOnOffSts 1;
BA_ "FlexKomComment" SG_ 613 DriverDoorOnOffSts "CBC message 10 packet";
BA_ "GenSigStartValue" SG_ 613 PsngrDoorOnOffSts 3;
BA_ "GenSigSNA" SG_ 613 PsngrDoorOnOffSts "3h";
BA_ "GenSigSendType" SG_ 613 PsngrDoorOnOffSts 5;
BA_ "GenSigCycleTime" SG_ 613 PsngrDoorOnOffSts 1000;
BA_ "FlexKomSigStartValue" SG_ 613 PsngrDoorOnOffSts "00000000003F06FFh";
BA_ "FlexKomSigStartPos" SG_ 613 PsngrDoorOnOffSts 7;
BA_ "FlexKomSigName" SG_ 613 PsngrDoorOnOffSts "CBC_PT10_Pkt";
BA_ "FlexKomSigLaenge" SG_ 613 PsngrDoorOnOffSts 64;
BA_ "FlexKomSID" SG_ 613 PsngrDoorOnOffSts 2499;
BA_ "FlexKomIsMotorola" SG_ 613 PsngrDoorOnOffSts 1;
BA_ "FlexKomComment" SG_ 613 PsngrDoorOnOffSts "CBC message 10 packet";
BA_ "GenSigStartValue" SG_ 613 LHRDoorOnOffSts 3;
BA_ "GenSigSNA" SG_ 613 LHRDoorOnOffSts "3h";
BA_ "GenSigSendType" SG_ 613 LHRDoorOnOffSts 5;
BA_ "GenSigCycleTime" SG_ 613 LHRDoorOnOffSts 1000;
BA_ "FlexKomSigStartValue" SG_ 613 LHRDoorOnOffSts "00000000003F06FFh";
BA_ "FlexKomSigStartPos" SG_ 613 LHRDoorOnOffSts 7;
BA_ "FlexKomSigName" SG_ 613 LHRDoorOnOffSts "CBC_PT10_Pkt";
BA_ "FlexKomSigLaenge" SG_ 613 LHRDoorOnOffSts 64;
BA_ "FlexKomSID" SG_ 613 LHRDoorOnOffSts 2499;
BA_ "FlexKomIsMotorola" SG_ 613 LHRDoorOnOffSts 1;
BA_ "FlexKomComment" SG_ 613 LHRDoorOnOffSts "CBC message 10 packet";
BA_ "GenSigStartValue" SG_ 613 RHRDoorOnOffSts 3;
BA_ "GenSigSNA" SG_ 613 RHRDoorOnOffSts "3h";
BA_ "GenSigSendType" SG_ 613 RHRDoorOnOffSts 5;
BA_ "GenSigCycleTime" SG_ 613 RHRDoorOnOffSts 1000;
BA_ "FlexKomSigStartValue" SG_ 613 RHRDoorOnOffSts "00000000003F06FFh";
BA_ "FlexKomSigStartPos" SG_ 613 RHRDoorOnOffSts 7;
BA_ "FlexKomSigName" SG_ 613 RHRDoorOnOffSts "CBC_PT10_Pkt";
BA_ "FlexKomSigLaenge" SG_ 613 RHRDoorOnOffSts 64;
BA_ "FlexKomSID" SG_ 613 RHRDoorOnOffSts 2499;
BA_ "FlexKomIsMotorola" SG_ 613 RHRDoorOnOffSts 1;
BA_ "FlexKomComment" SG_ 613 RHRDoorOnOffSts "CBC message 10 packet";
BA_ "GenSigTimeout_IC" SG_ 613 AUX_UNAV_BATT_CHRG 10500;
BA_ "GenSigSNA" SG_ 613 AUX_UNAV_BATT_CHRG "0h";
BA_ "GenSigSendType" SG_ 613 AUX_UNAV_BATT_CHRG 5;
BA_ "GenSigCycleTime" SG_ 613 AUX_UNAV_BATT_CHRG 1000;
BA_ "FlexKomSigStartValue" SG_ 613 AUX_UNAV_BATT_CHRG "00000000003F06FFh";
BA_ "FlexKomSigStartPos" SG_ 613 AUX_UNAV_BATT_CHRG 7;
BA_ "FlexKomSigName" SG_ 613 AUX_UNAV_BATT_CHRG "CBC_PT10_Pkt";
BA_ "FlexKomSigLaenge" SG_ 613 AUX_UNAV_BATT_CHRG 64;
BA_ "FlexKomSID" SG_ 613 AUX_UNAV_BATT_CHRG 2499;
BA_ "FlexKomIsMotorola" SG_ 613 AUX_UNAV_BATT_CHRG 1;
BA_ "FlexKomComment" SG_ 613 AUX_UNAV_BATT_CHRG "CBC message 10 packet";
BA_ "RID" SG_ 621 HTShtOffVlvReq "3066";
BA_ "GenSigSNA" SG_ 621 HTShtOffVlvReq "0h";
BA_ "GenSigSendType" SG_ 621 HTShtOffVlvReq 5;
BA_ "GenSigCycleTime" SG_ 621 HTShtOffVlvReq 1000;
BA_ "FlexKomSigStartValue" SG_ 621 HTShtOffVlvReq "00001E000001FF00h";
BA_ "FlexKomSigStartPos" SG_ 621 HTShtOffVlvReq 7;
BA_ "FlexKomSigName" SG_ 621 HTShtOffVlvReq "HCP_2";
BA_ "FlexKomSigLaenge" SG_ 621 HTShtOffVlvReq 64;
BA_ "FlexKomSID" SG_ 621 HTShtOffVlvReq 2512;
BA_ "FlexKomIsMotorola" SG_ 621 HTShtOffVlvReq 1;
BA_ "FlexKomComment" SG_ 621 HTShtOffVlvReq "HCP message 2 packet";
BA_ "RID" SG_ 621 FRfShVlvSts "2871";
BA_ "GenSigSNA" SG_ 621 FRfShVlvSts "0h";
BA_ "GenSigSendType" SG_ 621 FRfShVlvSts 5;
BA_ "GenSigCycleTime" SG_ 621 FRfShVlvSts 1000;
BA_ "FlexKomSigStartValue" SG_ 621 FRfShVlvSts "00001E000001FF00h";
BA_ "FlexKomSigStartPos" SG_ 621 FRfShVlvSts 7;
BA_ "FlexKomSigName" SG_ 621 FRfShVlvSts "HCP_2";
BA_ "FlexKomSigLaenge" SG_ 621 FRfShVlvSts 64;
BA_ "FlexKomSID" SG_ 621 FRfShVlvSts 2512;
BA_ "FlexKomIsMotorola" SG_ 621 FRfShVlvSts 1;
BA_ "FlexKomComment" SG_ 621 FRfShVlvSts "HCP message 2 packet";
BA_ "RID" SG_ 621 ElecCoolantHtrPwr "5018";
BA_ "GenSigTimeout_CBC" SG_ 621 ElecCoolantHtrPwr 10500;
BA_ "GenSigSNA" SG_ 621 ElecCoolantHtrPwr "FFh";
BA_ "GenSigSendType" SG_ 621 ElecCoolantHtrPwr 5;
BA_ "GenSigCycleTime" SG_ 621 ElecCoolantHtrPwr 1000;
BA_ "FlexKomSigStartValue" SG_ 621 ElecCoolantHtrPwr "00001E000001FF00h";
BA_ "FlexKomSigStartPos" SG_ 621 ElecCoolantHtrPwr 7;
BA_ "FlexKomSigName" SG_ 621 ElecCoolantHtrPwr "HCP_2";
BA_ "FlexKomSigLaenge" SG_ 621 ElecCoolantHtrPwr 64;
BA_ "FlexKomSID" SG_ 621 ElecCoolantHtrPwr 2512;
BA_ "FlexKomIsMotorola" SG_ 621 ElecCoolantHtrPwr 1;
BA_ "FlexKomComment" SG_ 621 ElecCoolantHtrPwr "HCP message 2 packet";
BA_ "GenSigSNA" SG_ 621 ElecClntHtrInletTemp "FFh";
BA_ "GenSigSendType" SG_ 621 ElecClntHtrInletTemp 5;
BA_ "GenSigCycleTime" SG_ 621 ElecClntHtrInletTemp 1000;
BA_ "FlexKomSigStartValue" SG_ 621 ElecClntHtrInletTemp "00001E000001FF00h";
BA_ "FlexKomSigStartPos" SG_ 621 ElecClntHtrInletTemp 7;
BA_ "FlexKomSigName" SG_ 621 ElecClntHtrInletTemp "HCP_2";
BA_ "FlexKomSigLaenge" SG_ 621 ElecClntHtrInletTemp 64;
BA_ "FlexKomSID" SG_ 621 ElecClntHtrInletTemp 2512;
BA_ "FlexKomIsMotorola" SG_ 621 ElecClntHtrInletTemp 1;
BA_ "FlexKomComment" SG_ 621 ElecClntHtrInletTemp "HCP message 2 packet";
BA_ "RID" SG_ 621 HTAuxPmpRPMAct "5020";
BA_ "GenSigTimeout_CBC" SG_ 621 HTAuxPmpRPMAct 10500;
BA_ "GenSigSNA" SG_ 621 HTAuxPmpRPMAct "FFh";
BA_ "GenSigSendType" SG_ 621 HTAuxPmpRPMAct 5;
BA_ "GenSigCycleTime" SG_ 621 HTAuxPmpRPMAct 1000;
BA_ "FlexKomSigStartValue" SG_ 621 HTAuxPmpRPMAct "00001E000001FF00h";
BA_ "FlexKomSigStartPos" SG_ 621 HTAuxPmpRPMAct 7;
BA_ "FlexKomSigName" SG_ 621 HTAuxPmpRPMAct "HCP_2";
BA_ "FlexKomSigLaenge" SG_ 621 HTAuxPmpRPMAct 64;
BA_ "FlexKomSID" SG_ 621 HTAuxPmpRPMAct 2512;
BA_ "FlexKomIsMotorola" SG_ 621 HTAuxPmpRPMAct 1;
BA_ "FlexKomComment" SG_ 621 HTAuxPmpRPMAct "HCP message 2 packet";
BA_ "GenSigTimeout_IC" SG_ 621 HVBat_CoolantLvlLo 10500;
BA_ "GenSigStartValue" SG_ 621 HVBat_CoolantLvlLo 3;
BA_ "GenSigSNA" SG_ 621 HVBat_CoolantLvlLo "3h";
BA_ "GenSigSendType" SG_ 621 HVBat_CoolantLvlLo 5;
BA_ "GenSigCycleTime" SG_ 621 HVBat_CoolantLvlLo 1000;
BA_ "FlexKomSigStartValue" SG_ 621 HVBat_CoolantLvlLo "00001E000001FF00h";
BA_ "FlexKomSigStartPos" SG_ 621 HVBat_CoolantLvlLo 7;
BA_ "FlexKomSigName" SG_ 621 HVBat_CoolantLvlLo "HCP_2";
BA_ "FlexKomSigLaenge" SG_ 621 HVBat_CoolantLvlLo 64;
BA_ "FlexKomSID" SG_ 621 HVBat_CoolantLvlLo 2512;
BA_ "FlexKomIsMotorola" SG_ 621 HVBat_CoolantLvlLo 1;
BA_ "FlexKomComment" SG_ 621 HVBat_CoolantLvlLo "HCP message 2 packet";
BA_ "GenSigStartValue" SG_ 621 HTAuxPmpMontrngRPM 3;
BA_ "GenSigSNA" SG_ 621 HTAuxPmpMontrngRPM "3h";
BA_ "GenSigSendType" SG_ 621 HTAuxPmpMontrngRPM 5;
BA_ "GenSigCycleTime" SG_ 621 HTAuxPmpMontrngRPM 1000;
BA_ "FlexKomSigStartValue" SG_ 621 HTAuxPmpMontrngRPM "00001E000001FF00h";
BA_ "FlexKomSigStartPos" SG_ 621 HTAuxPmpMontrngRPM 7;
BA_ "FlexKomSigName" SG_ 621 HTAuxPmpMontrngRPM "HCP_2";
BA_ "FlexKomSigLaenge" SG_ 621 HTAuxPmpMontrngRPM 64;
BA_ "FlexKomSID" SG_ 621 HTAuxPmpMontrngRPM 2512;
BA_ "FlexKomIsMotorola" SG_ 621 HTAuxPmpMontrngRPM 1;
BA_ "FlexKomComment" SG_ 621 HTAuxPmpMontrngRPM "HCP message 2 packet";
BA_ "RID" SG_ 621 HVBatCritCondT "5019";
BA_ "GenSigSNA" SG_ 621 HVBatCritCondT "0h";
BA_ "GenSigSendType" SG_ 621 HVBatCritCondT 5;
BA_ "GenSigCycleTime" SG_ 621 HVBatCritCondT 1000;
BA_ "FlexKomSigStartValue" SG_ 621 HVBatCritCondT "00001E000001FF00h";
BA_ "FlexKomSigStartPos" SG_ 621 HVBatCritCondT 7;
BA_ "FlexKomSigName" SG_ 621 HVBatCritCondT "HCP_2";
BA_ "FlexKomSigLaenge" SG_ 621 HVBatCritCondT 64;
BA_ "FlexKomSID" SG_ 621 HVBatCritCondT 2512;
BA_ "FlexKomIsMotorola" SG_ 621 HVBatCritCondT 1;
BA_ "FlexKomComment" SG_ 621 HVBatCritCondT "HCP message 2 packet";
BA_ "RID" SG_ 623 SwayBarBtnRq "5136";
BA_ "GenSigTimeout_ASBS" SG_ 623 SwayBarBtnRq 10500;
BA_ "GenSigSNA" SG_ 623 SwayBarBtnRq "3h";
BA_ "GenSigSendType" SG_ 623 SwayBarBtnRq 5;
BA_ "GenSigCycleTime" SG_ 623 SwayBarBtnRq 1000;
BA_ "FlexKomSigStartValue" SG_ 623 SwayBarBtnRq "0000FFFFFF7F7F7Fh";
BA_ "FlexKomSigStartPos" SG_ 623 SwayBarBtnRq 7;
BA_ "FlexKomSigName" SG_ 623 SwayBarBtnRq "GW_LIN_I_C5_Pkt";
BA_ "FlexKomSigLaenge" SG_ 623 SwayBarBtnRq 64;
BA_ "FlexKomSID" SG_ 623 SwayBarBtnRq 2511;
BA_ "FlexKomIsMotorola" SG_ 623 SwayBarBtnRq 1;
BA_ "FlexKomComment" SG_ 623 SwayBarBtnRq "-";
BA_ "RID" SG_ 623 HtrCorTmp_InTgt "2874";
BA_ "GenSigStartValue" SG_ 623 HtrCorTmp_InTgt 255;
BA_ "GenSigSNA" SG_ 623 HtrCorTmp_InTgt "FFh";
BA_ "GenSigSendType" SG_ 623 HtrCorTmp_InTgt 5;
BA_ "GenSigCycleTime" SG_ 623 HtrCorTmp_InTgt 1000;
BA_ "FlexKomSigStartValue" SG_ 623 HtrCorTmp_InTgt "0000FFFFFF7F7F7Fh";
BA_ "FlexKomSigStartPos" SG_ 623 HtrCorTmp_InTgt 7;
BA_ "FlexKomSigName" SG_ 623 HtrCorTmp_InTgt "GW_LIN_I_C5_Pkt";
BA_ "FlexKomSigLaenge" SG_ 623 HtrCorTmp_InTgt 64;
BA_ "FlexKomSID" SG_ 623 HtrCorTmp_InTgt 2511;
BA_ "FlexKomIsMotorola" SG_ 623 HtrCorTmp_InTgt 1;
BA_ "FlexKomComment" SG_ 623 HtrCorTmp_InTgt "-";
BA_ "RID" SG_ 623 VEH_INT_TEMP "2879";
BA_ "GenSigStartValue" SG_ 623 VEH_INT_TEMP 65535;
BA_ "GenSigSNA" SG_ 623 VEH_INT_TEMP "FFFFh";
BA_ "GenSigSendType" SG_ 623 VEH_INT_TEMP 5;
BA_ "GenSigCycleTime" SG_ 623 VEH_INT_TEMP 1000;
BA_ "FlexKomSigStartValue" SG_ 623 VEH_INT_TEMP "0000FFFFFF7F7F7Fh";
BA_ "FlexKomSigStartPos" SG_ 623 VEH_INT_TEMP 7;
BA_ "FlexKomSigName" SG_ 623 VEH_INT_TEMP "GW_LIN_I_C5_Pkt";
BA_ "FlexKomSigLaenge" SG_ 623 VEH_INT_TEMP 64;
BA_ "FlexKomSID" SG_ 623 VEH_INT_TEMP 2511;
BA_ "FlexKomIsMotorola" SG_ 623 VEH_INT_TEMP 1;
BA_ "FlexKomComment" SG_ 623 VEH_INT_TEMP "-";
BA_ "RID" SG_ 623 HVAC_Blwr_Perct "2873";
BA_ "GenSigStartValue" SG_ 623 HVAC_Blwr_Perct 127;
BA_ "GenSigSNA" SG_ 623 HVAC_Blwr_Perct "7Fh";
BA_ "GenSigSendType" SG_ 623 HVAC_Blwr_Perct 5;
BA_ "GenSigCycleTime" SG_ 623 HVAC_Blwr_Perct 1000;
BA_ "FlexKomSigStartValue" SG_ 623 HVAC_Blwr_Perct "0000FFFFFF7F7F7Fh";
BA_ "FlexKomSigStartPos" SG_ 623 HVAC_Blwr_Perct 7;
BA_ "FlexKomSigName" SG_ 623 HVAC_Blwr_Perct "GW_LIN_I_C5_Pkt";
BA_ "FlexKomSigLaenge" SG_ 623 HVAC_Blwr_Perct 64;
BA_ "FlexKomSID" SG_ 623 HVAC_Blwr_Perct 2511;
BA_ "FlexKomIsMotorola" SG_ 623 HVAC_Blwr_Perct 1;
BA_ "FlexKomComment" SG_ 623 HVAC_Blwr_Perct "-";
BA_ "GenSigTimeout_IC" SG_ 631 TCASE_FAIL 10500;
BA_ "GenSigTimeout_ETM" SG_ 631 TCASE_FAIL 10500;
BA_ "GenSigSNA" SG_ 631 TCASE_FAIL "0h";
BA_ "GenSigSendType" SG_ 631 TCASE_FAIL 5;
BA_ "GenSigCycleTime" SG_ 631 TCASE_FAIL 1000;
BA_ "FlexKomSigStartValue" SG_ 631 TCASE_FAIL "0000000000000000h";
BA_ "FlexKomSigStartPos" SG_ 631 TCASE_FAIL 7;
BA_ "FlexKomSigName" SG_ 631 TCASE_FAIL "DTCM_B1_PKT";
BA_ "FlexKomSigLaenge" SG_ 631 TCASE_FAIL 64;
BA_ "FlexKomSID" SG_ 631 TCASE_FAIL 808;
BA_ "FlexKomIsMotorola" SG_ 631 TCASE_FAIL 1;
BA_ "FlexKomComment" SG_ 631 TCASE_FAIL "DTCM_B1_PKT";
BA_ "GenSigTimeout_IC" SG_ 631 TCASE_INHBT 10500;
BA_ "GenSigTimeout_ETM" SG_ 631 TCASE_INHBT 10500;
BA_ "GenSigSNA" SG_ 631 TCASE_INHBT "0h";
BA_ "GenSigSendType" SG_ 631 TCASE_INHBT 5;
BA_ "GenSigCycleTime" SG_ 631 TCASE_INHBT 1000;
BA_ "FlexKomSigStartValue" SG_ 631 TCASE_INHBT "0000000000000000h";
BA_ "FlexKomSigStartPos" SG_ 631 TCASE_INHBT 7;
BA_ "FlexKomSigName" SG_ 631 TCASE_INHBT "DTCM_B1_PKT";
BA_ "FlexKomSigLaenge" SG_ 631 TCASE_INHBT 64;
BA_ "FlexKomSID" SG_ 631 TCASE_INHBT 808;
BA_ "FlexKomIsMotorola" SG_ 631 TCASE_INHBT 1;
BA_ "FlexKomComment" SG_ 631 TCASE_INHBT "DTCM_B1_PKT";
BA_ "GenSigTimeout_IC" SG_ 631 TCASE_SRV_RQ 10500;
BA_ "GenSigTimeout_ETM" SG_ 631 TCASE_SRV_RQ 10500;
BA_ "GenSigSNA" SG_ 631 TCASE_SRV_RQ "3h";
BA_ "GenSigSendType" SG_ 631 TCASE_SRV_RQ 5;
BA_ "GenSigCycleTime" SG_ 631 TCASE_SRV_RQ 1000;
BA_ "FlexKomSigStartValue" SG_ 631 TCASE_SRV_RQ "0000000000000000h";
BA_ "FlexKomSigStartPos" SG_ 631 TCASE_SRV_RQ 7;
BA_ "FlexKomSigName" SG_ 631 TCASE_SRV_RQ "DTCM_B1_PKT";
BA_ "FlexKomSigLaenge" SG_ 631 TCASE_SRV_RQ 64;
BA_ "FlexKomSID" SG_ 631 TCASE_SRV_RQ 808;
BA_ "FlexKomIsMotorola" SG_ 631 TCASE_SRV_RQ 1;
BA_ "FlexKomComment" SG_ 631 TCASE_SRV_RQ "DTCM_B1_PKT";
BA_ "RID" SG_ 631 Tcase4Lock "6524";
BA_ "GenSigTimeout_IC" SG_ 631 Tcase4Lock 10500;
BA_ "GenSigTimeout_ETM" SG_ 631 Tcase4Lock 10500;
BA_ "GenSigTimeout_CBC" SG_ 631 Tcase4Lock 10500;
BA_ "GenSigSNA" SG_ 631 Tcase4Lock "3h";
BA_ "GenSigSendType" SG_ 631 Tcase4Lock 5;
BA_ "GenSigCycleTime" SG_ 631 Tcase4Lock 1000;
BA_ "FlexKomSigStartValue" SG_ 631 Tcase4Lock "0000000000000000h";
BA_ "FlexKomSigStartPos" SG_ 631 Tcase4Lock 7;
BA_ "FlexKomSigName" SG_ 631 Tcase4Lock "DTCM_B1_PKT";
BA_ "FlexKomSigLaenge" SG_ 631 Tcase4Lock 64;
BA_ "FlexKomSID" SG_ 631 Tcase4Lock 808;
BA_ "FlexKomIsMotorola" SG_ 631 Tcase4Lock 1;
BA_ "FlexKomComment" SG_ 631 Tcase4Lock "DTCM_B1_PKT";
BA_ "RID" SG_ 631 Tcase4Low "1640 1747";
BA_ "GenSigTimeout_IC" SG_ 631 Tcase4Low 10500;
BA_ "GenSigTimeout_ETM" SG_ 631 Tcase4Low 10500;
BA_ "GenSigTimeout_CBC" SG_ 631 Tcase4Low 10500;
BA_ "GenSigSNA" SG_ 631 Tcase4Low "3h";
BA_ "GenSigSendType" SG_ 631 Tcase4Low 5;
BA_ "GenSigCycleTime" SG_ 631 Tcase4Low 1000;
BA_ "FlexKomSigStartValue" SG_ 631 Tcase4Low "0000000000000000h";
BA_ "FlexKomSigStartPos" SG_ 631 Tcase4Low 7;
BA_ "FlexKomSigName" SG_ 631 Tcase4Low "DTCM_B1_PKT";
BA_ "FlexKomSigLaenge" SG_ 631 Tcase4Low 64;
BA_ "FlexKomSID" SG_ 631 Tcase4Low 808;
BA_ "FlexKomIsMotorola" SG_ 631 Tcase4Low 1;
BA_ "FlexKomComment" SG_ 631 Tcase4Low "DTCM_B1_PKT";
BA_ "RID" SG_ 631 TcaseNtrlStat "1638 1705";
BA_ "GenSigTimeout_IC" SG_ 631 TcaseNtrlStat 10500;
BA_ "GenSigTimeout_ETM" SG_ 631 TcaseNtrlStat 10500;
BA_ "GenSigTimeout_CBC" SG_ 631 TcaseNtrlStat 10500;
BA_ "GenSigSNA" SG_ 631 TcaseNtrlStat "3h";
BA_ "GenSigSendType" SG_ 631 TcaseNtrlStat 5;
BA_ "GenSigCycleTime" SG_ 631 TcaseNtrlStat 1000;
BA_ "FlexKomSigStartValue" SG_ 631 TcaseNtrlStat "0000000000000000h";
BA_ "FlexKomSigStartPos" SG_ 631 TcaseNtrlStat 7;
BA_ "FlexKomSigName" SG_ 631 TcaseNtrlStat "DTCM_B1_PKT";
BA_ "FlexKomSigLaenge" SG_ 631 TcaseNtrlStat 64;
BA_ "FlexKomSID" SG_ 631 TcaseNtrlStat 808;
BA_ "FlexKomIsMotorola" SG_ 631 TcaseNtrlStat 1;
BA_ "FlexKomComment" SG_ 631 TcaseNtrlStat "DTCM_B1_PKT";
BA_ "RID" SG_ 631 TcaseAWD "1635 1746";
BA_ "GenSigTimeout_IC" SG_ 631 TcaseAWD 10500;
BA_ "GenSigTimeout_ETM" SG_ 631 TcaseAWD 10500;
BA_ "GenSigTimeout_CBC" SG_ 631 TcaseAWD 10500;
BA_ "GenSigSNA" SG_ 631 TcaseAWD "3h";
BA_ "GenSigSendType" SG_ 631 TcaseAWD 5;
BA_ "GenSigCycleTime" SG_ 631 TcaseAWD 1000;
BA_ "FlexKomSigStartValue" SG_ 631 TcaseAWD "0000000000000000h";
BA_ "FlexKomSigStartPos" SG_ 631 TcaseAWD 7;
BA_ "FlexKomSigName" SG_ 631 TcaseAWD "DTCM_B1_PKT";
BA_ "FlexKomSigLaenge" SG_ 631 TcaseAWD 64;
BA_ "FlexKomSID" SG_ 631 TcaseAWD 808;
BA_ "FlexKomIsMotorola" SG_ 631 TcaseAWD 1;
BA_ "FlexKomComment" SG_ 631 TcaseAWD "DTCM_B1_PKT";
BA_ "RID" SG_ 631 RrAxleLkIndRq "2884 3589 5126";
BA_ "GenSigTimeout_IC" SG_ 631 RrAxleLkIndRq 10500;
BA_ "GenSigSNA" SG_ 631 RrAxleLkIndRq "3h";
BA_ "GenSigSendType" SG_ 631 RrAxleLkIndRq 5;
BA_ "GenSigCycleTime" SG_ 631 RrAxleLkIndRq 1000;
BA_ "FlexKomSigStartValue" SG_ 631 RrAxleLkIndRq "0000000000000000h";
BA_ "FlexKomSigStartPos" SG_ 631 RrAxleLkIndRq 7;
BA_ "FlexKomSigName" SG_ 631 RrAxleLkIndRq "DTCM_B1_PKT";
BA_ "FlexKomSigLaenge" SG_ 631 RrAxleLkIndRq 64;
BA_ "FlexKomSID" SG_ 631 RrAxleLkIndRq 808;
BA_ "FlexKomIsMotorola" SG_ 631 RrAxleLkIndRq 1;
BA_ "FlexKomComment" SG_ 631 RrAxleLkIndRq "DTCM_B1_PKT";
BA_ "GenSigTimeout_IC" SG_ 631 CNT_DIFF_MOD 10500;
BA_ "GenSigSNA" SG_ 631 CNT_DIFF_MOD "3h";
BA_ "GenSigSendType" SG_ 631 CNT_DIFF_MOD 5;
BA_ "GenSigCycleTime" SG_ 631 CNT_DIFF_MOD 1000;
BA_ "FlexKomSigStartValue" SG_ 631 CNT_DIFF_MOD "0000000000000000h";
BA_ "FlexKomSigStartPos" SG_ 631 CNT_DIFF_MOD 7;
BA_ "FlexKomSigName" SG_ 631 CNT_DIFF_MOD "DTCM_B1_PKT";
BA_ "FlexKomSigLaenge" SG_ 631 CNT_DIFF_MOD 64;
BA_ "FlexKomSID" SG_ 631 CNT_DIFF_MOD 808;
BA_ "FlexKomIsMotorola" SG_ 631 CNT_DIFF_MOD 1;
BA_ "FlexKomComment" SG_ 631 CNT_DIFF_MOD "DTCM_B1_PKT";
BA_ "RID" SG_ 631 Tcase2WD_Stat "1641 5141";
BA_ "GenSigTimeout_IC" SG_ 631 Tcase2WD_Stat 10500;
BA_ "GenSigTimeout_CBC" SG_ 631 Tcase2WD_Stat 10500;
BA_ "GenSigSNA" SG_ 631 Tcase2WD_Stat "3h";
BA_ "GenSigSendType" SG_ 631 Tcase2WD_Stat 5;
BA_ "GenSigCycleTime" SG_ 631 Tcase2WD_Stat 1000;
BA_ "FlexKomSigStartValue" SG_ 631 Tcase2WD_Stat "0000000000000000h";
BA_ "FlexKomSigStartPos" SG_ 631 Tcase2WD_Stat 7;
BA_ "FlexKomSigName" SG_ 631 Tcase2WD_Stat "DTCM_B1_PKT";
BA_ "FlexKomSigLaenge" SG_ 631 Tcase2WD_Stat 64;
BA_ "FlexKomSID" SG_ 631 Tcase2WD_Stat 808;
BA_ "FlexKomIsMotorola" SG_ 631 Tcase2WD_Stat 1;
BA_ "FlexKomComment" SG_ 631 Tcase2WD_Stat "DTCM_B1_PKT";
BA_ "GenSigTimeout_IC" SG_ 631 DTCM_HMI_Rq 10500;
BA_ "GenSigSNA" SG_ 631 DTCM_HMI_Rq "1Fh";
BA_ "GenSigSendType" SG_ 631 DTCM_HMI_Rq 5;
BA_ "GenSigCycleTime" SG_ 631 DTCM_HMI_Rq 1000;
BA_ "FlexKomSigStartValue" SG_ 631 DTCM_HMI_Rq "0000000000000000h";
BA_ "FlexKomSigStartPos" SG_ 631 DTCM_HMI_Rq 7;
BA_ "FlexKomSigName" SG_ 631 DTCM_HMI_Rq "DTCM_B1_PKT";
BA_ "FlexKomSigLaenge" SG_ 631 DTCM_HMI_Rq 64;
BA_ "FlexKomSID" SG_ 631 DTCM_HMI_Rq 808;
BA_ "FlexKomIsMotorola" SG_ 631 DTCM_HMI_Rq 1;
BA_ "FlexKomComment" SG_ 631 DTCM_HMI_Rq "DTCM_B1_PKT";
BA_ "RID" SG_ 631 Ft_RrAxleLkIndRq "5154";
BA_ "GenSigTimeout_IC" SG_ 631 Ft_RrAxleLkIndRq 10500;
BA_ "GenSigTimeout_CBC" SG_ 631 Ft_RrAxleLkIndRq 10500;
BA_ "GenSigSNA" SG_ 631 Ft_RrAxleLkIndRq "3h";
BA_ "GenSigSendType" SG_ 631 Ft_RrAxleLkIndRq 5;
BA_ "GenSigCycleTime" SG_ 631 Ft_RrAxleLkIndRq 1000;
BA_ "FlexKomSigStartValue" SG_ 631 Ft_RrAxleLkIndRq "0000000000000000h";
BA_ "FlexKomSigStartPos" SG_ 631 Ft_RrAxleLkIndRq 7;
BA_ "FlexKomSigName" SG_ 631 Ft_RrAxleLkIndRq "DTCM_B1_PKT";
BA_ "FlexKomSigLaenge" SG_ 631 Ft_RrAxleLkIndRq 64;
BA_ "FlexKomSID" SG_ 631 Ft_RrAxleLkIndRq 808;
BA_ "FlexKomIsMotorola" SG_ 631 Ft_RrAxleLkIndRq 1;
BA_ "FlexKomComment" SG_ 631 Ft_RrAxleLkIndRq "DTCM_B1_PKT";
BA_ "GenSigTimeout_IC" SG_ 631 AxleLckrEVICDisplay 10500;
BA_ "GenSigSNA" SG_ 631 AxleLckrEVICDisplay "Fh";
BA_ "GenSigSendType" SG_ 631 AxleLckrEVICDisplay 5;
BA_ "GenSigCycleTime" SG_ 631 AxleLckrEVICDisplay 1000;
BA_ "FlexKomSigStartValue" SG_ 631 AxleLckrEVICDisplay "0000000000000000h";
BA_ "FlexKomSigStartPos" SG_ 631 AxleLckrEVICDisplay 7;
BA_ "FlexKomSigName" SG_ 631 AxleLckrEVICDisplay "DTCM_B1_PKT";
BA_ "FlexKomSigLaenge" SG_ 631 AxleLckrEVICDisplay 64;
BA_ "FlexKomSID" SG_ 631 AxleLckrEVICDisplay 808;
BA_ "FlexKomIsMotorola" SG_ 631 AxleLckrEVICDisplay 1;
BA_ "FlexKomComment" SG_ 631 AxleLckrEVICDisplay "DTCM_B1_PKT";
BA_ "GenSigTimeout_IC" SG_ 631 AxleLckrSts 10500;
BA_ "GenSigSNA" SG_ 631 AxleLckrSts "3h";
BA_ "GenSigSendType" SG_ 631 AxleLckrSts 5;
BA_ "GenSigCycleTime" SG_ 631 AxleLckrSts 1000;
BA_ "FlexKomSigStartValue" SG_ 631 AxleLckrSts "0000000000000000h";
BA_ "FlexKomSigStartPos" SG_ 631 AxleLckrSts 7;
BA_ "FlexKomSigName" SG_ 631 AxleLckrSts "DTCM_B1_PKT";
BA_ "FlexKomSigLaenge" SG_ 631 AxleLckrSts 64;
BA_ "FlexKomSID" SG_ 631 AxleLckrSts 808;
BA_ "FlexKomIsMotorola" SG_ 631 AxleLckrSts 1;
BA_ "FlexKomComment" SG_ 631 AxleLckrSts "DTCM_B1_PKT";
BA_ "GenSigTimeout_IC" SG_ 631 AXLELCKR_SRV_RQ 10500;
BA_ "GenSigTimeout_ETM" SG_ 631 AXLELCKR_SRV_RQ 10500;
BA_ "GenSigSNA" SG_ 631 AXLELCKR_SRV_RQ "3h";
BA_ "GenSigSendType" SG_ 631 AXLELCKR_SRV_RQ 5;
BA_ "GenSigCycleTime" SG_ 631 AXLELCKR_SRV_RQ 1000;
BA_ "FlexKomSigStartValue" SG_ 631 AXLELCKR_SRV_RQ "0000000000000000h";
BA_ "FlexKomSigStartPos" SG_ 631 AXLELCKR_SRV_RQ 7;
BA_ "FlexKomSigName" SG_ 631 AXLELCKR_SRV_RQ "DTCM_B1_PKT";
BA_ "FlexKomSigLaenge" SG_ 631 AXLELCKR_SRV_RQ 64;
BA_ "FlexKomSID" SG_ 631 AXLELCKR_SRV_RQ 808;
BA_ "FlexKomIsMotorola" SG_ 631 AXLELCKR_SRV_RQ 1;
BA_ "FlexKomComment" SG_ 631 AXLELCKR_SRV_RQ "DTCM_B1_PKT";
BA_ "GenSigTimeout_IC" SG_ 633 FuelMM_Sts 10500;
BA_ "GenSigSNA" SG_ 633 FuelMM_Sts "0h";
BA_ "GenSigCycleTime" SG_ 633 FuelMM_Sts 1000;
BA_ "FlexKomSigStartValue" SG_ 633 FuelMM_Sts "00h";
BA_ "FlexKomSigStartPos" SG_ 633 FuelMM_Sts 47;
BA_ "FlexKomSigName" SG_ 633 FuelMM_Sts "FuelMM_Sts";
BA_ "FlexKomSigLaenge" SG_ 633 FuelMM_Sts 8;
BA_ "FlexKomSID" SG_ 633 FuelMM_Sts 2550;
BA_ "FlexKomIsMotorola" SG_ 633 FuelMM_Sts 1;
BA_ "FlexKomComment" SG_ 633 FuelMM_Sts "Fuel maintenance mode status";
BA_ "GenSigTimeout_IC" SG_ 633 DisOilLifeRst 10500;
BA_ "GenSigTimeout_ETM" SG_ 633 DisOilLifeRst 10500;
BA_ "GenSigTimeout_CBC" SG_ 633 DisOilLifeRst 10500;
BA_ "GenSigStartValue" SG_ 633 DisOilLifeRst 65535;
BA_ "GenSigSNA" SG_ 633 DisOilLifeRst "FFFFh";
BA_ "GenSigCycleTime" SG_ 633 DisOilLifeRst 1000;
BA_ "FlexKomSigStartValue" SG_ 633 DisOilLifeRst "FFFFFF0FFFh";
BA_ "FlexKomSigStartPos" SG_ 633 DisOilLifeRst 7;
BA_ "FlexKomSigName" SG_ 633 DisOilLifeRst "OilLifePkt";
BA_ "FlexKomSigLaenge" SG_ 633 DisOilLifeRst 40;
BA_ "FlexKomSID" SG_ 633 DisOilLifeRst 1668;
BA_ "FlexKomIsMotorola" SG_ 633 DisOilLifeRst 1;
BA_ "FlexKomComment" SG_ 633 DisOilLifeRst "Oil life packet";
BA_ "GenSigTimeout_TBM" SG_ 633 OilLifeLeft 10500;
BA_ "GenSigTimeout_IC" SG_ 633 OilLifeLeft 10500;
BA_ "GenSigTimeout_ETM" SG_ 633 OilLifeLeft 10500;
BA_ "GenSigStartValue" SG_ 633 OilLifeLeft 255;
BA_ "GenSigSNA" SG_ 633 OilLifeLeft "FFh";
BA_ "GenSigCycleTime" SG_ 633 OilLifeLeft 1000;
BA_ "FlexKomSigStartValue" SG_ 633 OilLifeLeft "FFFFFF0FFFh";
BA_ "FlexKomSigStartPos" SG_ 633 OilLifeLeft 7;
BA_ "FlexKomSigName" SG_ 633 OilLifeLeft "OilLifePkt";
BA_ "FlexKomSigLaenge" SG_ 633 OilLifeLeft 40;
BA_ "FlexKomSID" SG_ 633 OilLifeLeft 1668;
BA_ "FlexKomIsMotorola" SG_ 633 OilLifeLeft 1;
BA_ "FlexKomComment" SG_ 633 OilLifeLeft "Oil life packet";
BA_ "GenSigTimeout_TBM" SG_ 633 HoursOilLifeRst 10500;
BA_ "GenSigTimeout_IC" SG_ 633 HoursOilLifeRst 10500;
BA_ "GenSigTimeout_ETM" SG_ 633 HoursOilLifeRst 10500;
BA_ "GenSigTimeout_CBC" SG_ 633 HoursOilLifeRst 10500;
BA_ "GenSigStartValue" SG_ 633 HoursOilLifeRst 4095;
BA_ "GenSigSNA" SG_ 633 HoursOilLifeRst "FFFh";
BA_ "GenSigCycleTime" SG_ 633 HoursOilLifeRst 1000;
BA_ "FlexKomSigStartValue" SG_ 633 HoursOilLifeRst "FFFFFF0FFFh";
BA_ "FlexKomSigStartPos" SG_ 633 HoursOilLifeRst 7;
BA_ "FlexKomSigName" SG_ 633 HoursOilLifeRst "OilLifePkt";
BA_ "FlexKomSigLaenge" SG_ 633 HoursOilLifeRst 40;
BA_ "FlexKomSID" SG_ 633 HoursOilLifeRst 1668;
BA_ "FlexKomIsMotorola" SG_ 633 HoursOilLifeRst 1;
BA_ "FlexKomComment" SG_ 633 HoursOilLifeRst "Oil life packet";
BA_ "GenSigTimeout_TBM" SG_ 633 MntncSts 10500;
BA_ "GenSigTimeout_IC" SG_ 633 MntncSts 10500;
BA_ "GenSigTimeout_ETM" SG_ 633 MntncSts 10500;
BA_ "GenSigSNA" SG_ 633 MntncSts "3h";
BA_ "GenSigCycleTime" SG_ 633 MntncSts 1000;
BA_ "FlexKomSigStartValue" SG_ 633 MntncSts "FFFFFF0FFFh";
BA_ "FlexKomSigStartPos" SG_ 633 MntncSts 7;
BA_ "FlexKomSigName" SG_ 633 MntncSts "OilLifePkt";
BA_ "FlexKomSigLaenge" SG_ 633 MntncSts 40;
BA_ "FlexKomSID" SG_ 633 MntncSts 1668;
BA_ "FlexKomIsMotorola" SG_ 633 MntncSts 1;
BA_ "FlexKomComment" SG_ 633 MntncSts "Oil life packet";
BA_ "RID" SG_ 633 OilLifeLeftRst "1619";
BA_ "GenSigTimeout_TBM" SG_ 633 OilLifeLeftRst 10500;
BA_ "GenSigTimeout_IC" SG_ 633 OilLifeLeftRst 10500;
BA_ "GenSigTimeout_ETM" SG_ 633 OilLifeLeftRst 10500;
BA_ "GenSigSNA" SG_ 633 OilLifeLeftRst "0h";
BA_ "GenSigCycleTime" SG_ 633 OilLifeLeftRst 1000;
BA_ "FlexKomSigStartValue" SG_ 633 OilLifeLeftRst "FFFFFF0FFFh";
BA_ "FlexKomSigStartPos" SG_ 633 OilLifeLeftRst 7;
BA_ "FlexKomSigName" SG_ 633 OilLifeLeftRst "OilLifePkt";
BA_ "FlexKomSigLaenge" SG_ 633 OilLifeLeftRst 40;
BA_ "FlexKomSID" SG_ 633 OilLifeLeftRst 1668;
BA_ "FlexKomIsMotorola" SG_ 633 OilLifeLeftRst 1;
BA_ "FlexKomComment" SG_ 633 OilLifeLeftRst "Oil life packet";
BA_ "GenSigSNA" SG_ 634 OilChgRst "0h";
BA_ "GenSigSendType" SG_ 634 OilChgRst 5;
BA_ "GenSigCycleTime" SG_ 634 OilChgRst 1000;
BA_ "FlexKomSigStartValue" SG_ 634 OilChgRst "00h";
BA_ "FlexKomSigStartPos" SG_ 634 OilChgRst 29;
BA_ "FlexKomSigName" SG_ 634 OilChgRst "OilChgRst";
BA_ "FlexKomSigLaenge" SG_ 634 OilChgRst 1;
BA_ "FlexKomSID" SG_ 634 OilChgRst 1819;
BA_ "FlexKomIsMotorola" SG_ 634 OilChgRst 1;
BA_ "FlexKomComment" SG_ 634 OilChgRst "Oil change reminder reset request";
BA_ "RID" SG_ 634 ODO "1177 2112";
BA_ "GenSigTimeout_TCM" SG_ 634 ODO 3500;
BA_ "GenSigTimeout_SCCM" SG_ 634 ODO 10500;
BA_ "GenSigTimeout_RF_HUB" SG_ 634 ODO 10500;
BA_ "GenSigTimeout_ORC" SG_ 634 ODO 3500;
BA_ "GenSigTimeout_ESM" SG_ 634 ODO 10500;
BA_ "GenSigTimeout_EHPS" SG_ 634 ODO 10500;
BA_ "GenSigTimeout_DTCM" SG_ 634 ODO 10500;
BA_ "GenSigTimeout_CBC" SG_ 634 ODO 10500;
BA_ "GenSigStartValue" SG_ 634 ODO 16777215;
BA_ "GenSigSNA" SG_ 634 ODO "FFFFFFh";
BA_ "GenSigSendType" SG_ 634 ODO 5;
BA_ "GenSigCycleTime" SG_ 634 ODO 1000;
BA_ "FlexKomSigStartValue" SG_ 634 ODO "FFFFFFh";
BA_ "FlexKomSigStartPos" SG_ 634 ODO 39;
BA_ "FlexKomSigName" SG_ 634 ODO "ODO";
BA_ "FlexKomSigLaenge" SG_ 634 ODO 24;
BA_ "FlexKomSID" SG_ 634 ODO 804;
BA_ "FlexKomIsMotorola" SG_ 634 ODO 1;
BA_ "FlexKomComment" SG_ 634 ODO "Odometer";
BA_ "RID" SG_ 634 AvgFuelLvl "1196";
BA_ "GenSigTimeout_TBM" SG_ 634 AvgFuelLvl 10500;
BA_ "GenSigTimeout_ETM" SG_ 634 AvgFuelLvl 10500;
BA_ "GenSigTimeout_CBC" SG_ 634 AvgFuelLvl 10500;
BA_ "GenSigStartValue" SG_ 634 AvgFuelLvl 511;
BA_ "GenSigSNA" SG_ 634 AvgFuelLvl "1FFh";
BA_ "GenSigSendType" SG_ 634 AvgFuelLvl 5;
BA_ "GenSigCycleTime" SG_ 634 AvgFuelLvl 1000;
BA_ "FlexKomSigStartValue" SG_ 634 AvgFuelLvl "01FFh";
BA_ "FlexKomSigStartPos" SG_ 634 AvgFuelLvl 7;
BA_ "FlexKomSigName" SG_ 634 AvgFuelLvl "AvgFuelLvl";
BA_ "FlexKomSigLaenge" SG_ 634 AvgFuelLvl 16;
BA_ "FlexKomSID" SG_ 634 AvgFuelLvl 848;
BA_ "FlexKomIsMotorola" SG_ 634 AvgFuelLvl 1;
BA_ "FlexKomComment" SG_ 634 AvgFuelLvl "Average filtered fuel level in liters";
BA_ "GenSigTimeout_TBM" SG_ 634 SRS_LMP_STAT 10500;
BA_ "GenSigTimeout_ORC" SG_ 634 SRS_LMP_STAT 3500;
BA_ "GenSigTimeout_ETM" SG_ 634 SRS_LMP_STAT 10500;
BA_ "GenSigSNA" SG_ 634 SRS_LMP_STAT "3h";
BA_ "GenSigSendType" SG_ 634 SRS_LMP_STAT 5;
BA_ "GenSigCycleTime" SG_ 634 SRS_LMP_STAT 1000;
BA_ "FlexKomSigStartValue" SG_ 634 SRS_LMP_STAT "00h";
BA_ "FlexKomSigStartPos" SG_ 634 SRS_LMP_STAT 5;
BA_ "FlexKomSigName" SG_ 634 SRS_LMP_STAT "SRS_LMP_STAT";
BA_ "FlexKomSigLaenge" SG_ 634 SRS_LMP_STAT 2;
BA_ "FlexKomSID" SG_ 634 SRS_LMP_STAT 851;
BA_ "FlexKomIsMotorola" SG_ 634 SRS_LMP_STAT 1;
BA_ "FlexKomComment" SG_ 634 SRS_LMP_STAT "Airbag indicator lamp status";
BA_ "GenSigTimeout_CBC" SG_ 634 FuelLvlLow 10500;
BA_ "GenSigSNA" SG_ 634 FuelLvlLow "0h";
BA_ "GenSigSendType" SG_ 634 FuelLvlLow 5;
BA_ "GenSigCycleTime" SG_ 634 FuelLvlLow 1000;
BA_ "FlexKomSigStartValue" SG_ 634 FuelLvlLow "00h";
BA_ "FlexKomSigStartPos" SG_ 634 FuelLvlLow 6;
BA_ "FlexKomSigName" SG_ 634 FuelLvlLow "FuelLvlLow";
BA_ "FlexKomSigLaenge" SG_ 634 FuelLvlLow 1;
BA_ "FlexKomSID" SG_ 634 FuelLvlLow 1049;
BA_ "FlexKomIsMotorola" SG_ 634 FuelLvlLow 1;
BA_ "FlexKomComment" SG_ 634 FuelLvlLow "Fuel level low";
BA_ "RID" SG_ 635 Gas_Range "3068";
BA_ "GenSigTimeout_CBC" SG_ 635 Gas_Range 10500;
BA_ "GenSigStartValue" SG_ 635 Gas_Range 1023;
BA_ "GenSigSNA" SG_ 635 Gas_Range "3FFh";
BA_ "GenSigSendType" SG_ 635 Gas_Range 5;
BA_ "GenSigCycleTime" SG_ 635 Gas_Range 1000;
BA_ "FlexKomSigStartValue" SG_ 635 Gas_Range "A3FF07FF00000000h";
BA_ "FlexKomSigStartPos" SG_ 635 Gas_Range 7;
BA_ "FlexKomSigName" SG_ 635 Gas_Range "IC_A5_Pkt";
BA_ "FlexKomSigLaenge" SG_ 635 Gas_Range 64;
BA_ "FlexKomSID" SG_ 635 Gas_Range 2522;
BA_ "FlexKomIsMotorola" SG_ 635 Gas_Range 1;
BA_ "FlexKomComment" SG_ 635 Gas_Range "IC_A5 packet";
BA_ "RID" SG_ 635 Total_Range "3064";
BA_ "GenSigTimeout_CBC" SG_ 635 Total_Range 10500;
BA_ "GenSigStartValue" SG_ 635 Total_Range 2047;
BA_ "GenSigSNA" SG_ 635 Total_Range "7FFh";
BA_ "GenSigSendType" SG_ 635 Total_Range 5;
BA_ "GenSigCycleTime" SG_ 635 Total_Range 1000;
BA_ "FlexKomSigStartValue" SG_ 635 Total_Range "A3FF07FF00000000h";
BA_ "FlexKomSigStartPos" SG_ 635 Total_Range 7;
BA_ "FlexKomSigName" SG_ 635 Total_Range "IC_A5_Pkt";
BA_ "FlexKomSigLaenge" SG_ 635 Total_Range 64;
BA_ "FlexKomSID" SG_ 635 Total_Range 2522;
BA_ "FlexKomIsMotorola" SG_ 635 Total_Range 1;
BA_ "FlexKomComment" SG_ 635 Total_Range "IC_A5 packet";
BA_ "RID" SG_ 635 TSI_FeatureStatus "6330";
BA_ "GenSigSNA" SG_ 635 TSI_FeatureStatus "0h";
BA_ "GenSigSendType" SG_ 635 TSI_FeatureStatus 5;
BA_ "GenSigCycleTime" SG_ 635 TSI_FeatureStatus 1000;
BA_ "FlexKomSigStartValue" SG_ 635 TSI_FeatureStatus "A3FF07FF00000000h";
BA_ "FlexKomSigStartPos" SG_ 635 TSI_FeatureStatus 7;
BA_ "FlexKomSigName" SG_ 635 TSI_FeatureStatus "IC_A5_Pkt";
BA_ "FlexKomSigLaenge" SG_ 635 TSI_FeatureStatus 64;
BA_ "FlexKomSID" SG_ 635 TSI_FeatureStatus 2522;
BA_ "FlexKomIsMotorola" SG_ 635 TSI_FeatureStatus 1;
BA_ "FlexKomComment" SG_ 635 TSI_FeatureStatus "IC_A5 packet";
BA_ "RID" SG_ 641 IBS_R_Batt "1917";
BA_ "GenSigStartValue" SG_ 641 IBS_R_Batt 2047;
BA_ "GenSigSNA" SG_ 641 IBS_R_Batt "7FFh";
BA_ "GenSigCycleTime" SG_ 641 IBS_R_Batt 1000;
BA_ "FlexKomSigStartValue" SG_ 641 IBS_R_Batt "07FFh";
BA_ "FlexKomSigStartPos" SG_ 641 IBS_R_Batt 7;
BA_ "FlexKomSigName" SG_ 641 IBS_R_Batt "IBS_R_Batt";
BA_ "FlexKomSigLaenge" SG_ 641 IBS_R_Batt 16;
BA_ "FlexKomSID" SG_ 641 IBS_R_Batt 1948;
BA_ "FlexKomIsMotorola" SG_ 641 IBS_R_Batt 1;
BA_ "FlexKomComment" SG_ 641 IBS_R_Batt "Calculated battery resistance";
BA_ "RID" SG_ 641 TGW_AUD_MD_CAB_DR "2058";
BA_ "GenSigTimeout_IC" SG_ 641 TGW_AUD_MD_CAB_DR 10500;
BA_ "GenSigSNA" SG_ 641 TGW_AUD_MD_CAB_DR "1Fh";
BA_ "GenSigSendType" SG_ 641 TGW_AUD_MD_CAB_DR 5;
BA_ "GenSigCycleTime" SG_ 641 TGW_AUD_MD_CAB_DR 1000;
BA_ "FlexKomSigStartValue" SG_ 641 TGW_AUD_MD_CAB_DR "00h";
BA_ "FlexKomSigStartPos" SG_ 641 TGW_AUD_MD_CAB_DR 7;
BA_ "FlexKomSigName" SG_ 641 TGW_AUD_MD_CAB_DR "TGW_AUD_MD_CAB_DR";
BA_ "FlexKomSigLaenge" SG_ 641 TGW_AUD_MD_CAB_DR 5;
BA_ "FlexKomSID" SG_ 641 TGW_AUD_MD_CAB_DR 672;
BA_ "FlexKomIsMotorola" SG_ 641 TGW_AUD_MD_CAB_DR 1;
BA_ "FlexKomComment" SG_ 641 TGW_AUD_MD_CAB_DR "TGW audio mode for Cabin/Driver";
BA_ "RID" SG_ 641 IBS_R_Batt_25 "1912";
BA_ "GenSigStartValue" SG_ 641 IBS_R_Batt_25 2047;
BA_ "GenSigSNA" SG_ 641 IBS_R_Batt_25 "7FFh";
BA_ "GenSigCycleTime" SG_ 641 IBS_R_Batt_25 1000;
BA_ "FlexKomSigStartValue" SG_ 641 IBS_R_Batt_25 "07FFh";
BA_ "FlexKomSigStartPos" SG_ 641 IBS_R_Batt_25 23;
BA_ "FlexKomSigName" SG_ 641 IBS_R_Batt_25 "IBS_R_Batt_25";
BA_ "FlexKomSigLaenge" SG_ 641 IBS_R_Batt_25 16;
BA_ "FlexKomSID" SG_ 641 IBS_R_Batt_25 1947;
BA_ "FlexKomIsMotorola" SG_ 641 IBS_R_Batt_25 1;
BA_ "FlexKomComment" SG_ 641 IBS_R_Batt_25 "Batt resistance at 100% SOC and 25 degC";
BA_ "RID" SG_ 641 Trns_DrvMdReq "6575";
BA_ "GenSigTimeout_IC" SG_ 641 Trns_DrvMdReq 10500;
BA_ "GenSigSNA" SG_ 641 Trns_DrvMdReq "Fh";
BA_ "GenSigSendType" SG_ 641 Trns_DrvMdReq 5;
BA_ "GenSigCycleTime" SG_ 641 Trns_DrvMdReq 1000;
BA_ "FlexKomSigStartValue" SG_ 641 Trns_DrvMdReq "00h";
BA_ "FlexKomSigStartPos" SG_ 641 Trns_DrvMdReq 43;
BA_ "FlexKomSigName" SG_ 641 Trns_DrvMdReq "Trns_DrvMdReq";
BA_ "FlexKomSigLaenge" SG_ 641 Trns_DrvMdReq 4;
BA_ "FlexKomSID" SG_ 641 Trns_DrvMdReq 2081;
BA_ "FlexKomIsMotorola" SG_ 641 Trns_DrvMdReq 1;
BA_ "FlexKomComment" SG_ 641 Trns_DrvMdReq "The requested state of the drive mode feature";
BA_ "GenSigTimeout_IC" SG_ 641 PaddlesModeReq 10500;
BA_ "GenSigSNA" SG_ 641 PaddlesModeReq "3h";
BA_ "GenSigSendType" SG_ 641 PaddlesModeReq 5;
BA_ "GenSigCycleTime" SG_ 641 PaddlesModeReq 1000;
BA_ "FlexKomSigStartValue" SG_ 641 PaddlesModeReq "00h";
BA_ "FlexKomSigStartPos" SG_ 641 PaddlesModeReq 55;
BA_ "FlexKomSigName" SG_ 641 PaddlesModeReq "PaddlesModeReq";
BA_ "FlexKomSigLaenge" SG_ 641 PaddlesModeReq 2;
BA_ "FlexKomSID" SG_ 641 PaddlesModeReq 2080;
BA_ "FlexKomIsMotorola" SG_ 641 PaddlesModeReq 1;
BA_ "FlexKomComment" SG_ 641 PaddlesModeReq "Requested state of paddle lock-out function";
BA_ "RID" SG_ 641 TBM_E_CALL_STS "2196";
BA_ "GenSigTimeout_IC" SG_ 641 TBM_E_CALL_STS 10500;
BA_ "GenSigSNA" SG_ 641 TBM_E_CALL_STS "Fh";
BA_ "GenSigSendType" SG_ 641 TBM_E_CALL_STS 5;
BA_ "GenSigCycleTime" SG_ 641 TBM_E_CALL_STS 1000;
BA_ "FlexKomSigStartValue" SG_ 641 TBM_E_CALL_STS "00h";
BA_ "FlexKomSigStartPos" SG_ 641 TBM_E_CALL_STS 62;
BA_ "FlexKomSigName" SG_ 641 TBM_E_CALL_STS "TBM_E_CALL_STS";
BA_ "FlexKomSigLaenge" SG_ 641 TBM_E_CALL_STS 4;
BA_ "FlexKomSID" SG_ 641 TBM_E_CALL_STS 2438;
BA_ "FlexKomIsMotorola" SG_ 641 TBM_E_CALL_STS 1;
BA_ "FlexKomComment" SG_ 641 TBM_E_CALL_STS "E call status messages";
BA_ "RID" SG_ 641 PSS_Display "6375";
BA_ "GenSigSNA" SG_ 641 PSS_Display "Fh";
BA_ "GenSigSendType" SG_ 641 PSS_Display 5;
BA_ "GenSigCycleTime" SG_ 641 PSS_Display 1000;
BA_ "FlexKomSigStartValue" SG_ 641 PSS_Display "00h";
BA_ "FlexKomSigStartPos" SG_ 641 PSS_Display 22;
BA_ "FlexKomSigName" SG_ 641 PSS_Display "PSSM_A1_Pkt";
BA_ "FlexKomSigLaenge" SG_ 641 PSS_Display 4;
BA_ "FlexKomSID" SG_ 641 PSS_Display 2736;
BA_ "FlexKomIsMotorola" SG_ 641 PSS_Display 1;
BA_ "FlexKomComment" SG_ 641 PSS_Display "Power Side Step Packet";
BA_ "GenSigTimeout_IC" SG_ 643 HdAjar 10500;
BA_ "GenSigStartValue" SG_ 643 HdAjar 1;
BA_ "GenSigSNA" SG_ 643 HdAjar "1h";
BA_ "GenSigSendType" SG_ 643 HdAjar 5;
BA_ "GenSigCycleTime" SG_ 643 HdAjar 1000;
BA_ "FlexKomSigStartValue" SG_ 643 HdAjar "01h";
BA_ "FlexKomSigStartPos" SG_ 643 HdAjar 10;
BA_ "FlexKomSigName" SG_ 643 HdAjar "HdAjar";
BA_ "FlexKomSigLaenge" SG_ 643 HdAjar 1;
BA_ "FlexKomSID" SG_ 643 HdAjar 1818;
BA_ "FlexKomIsMotorola" SG_ 643 HdAjar 1;
BA_ "FlexKomComment" SG_ 643 HdAjar "Hood latch ajar, left or single (1=ajar)";
BA_ "GenSigTimeout_IC" SG_ 643 TurnLmp_FL_Flt 10500;
BA_ "GenSigSNA" SG_ 643 TurnLmp_FL_Flt "0h";
BA_ "GenSigSendType" SG_ 643 TurnLmp_FL_Flt 5;
BA_ "GenSigCycleTime" SG_ 643 TurnLmp_FL_Flt 1000;
BA_ "FlexKomSigStartValue" SG_ 643 TurnLmp_FL_Flt "00h";
BA_ "FlexKomSigStartPos" SG_ 643 TurnLmp_FL_Flt 14;
BA_ "FlexKomSigName" SG_ 643 TurnLmp_FL_Flt "TurnLmp_F_Flt";
BA_ "FlexKomSigLaenge" SG_ 643 TurnLmp_FL_Flt 2;
BA_ "FlexKomSID" SG_ 643 TurnLmp_FL_Flt 973;
BA_ "FlexKomIsMotorola" SG_ 643 TurnLmp_FL_Flt 1;
BA_ "FlexKomComment" SG_ 643 TurnLmp_FL_Flt "Turn indication lamp front fault";
BA_ "GenSigTimeout_IC" SG_ 643 TurnLmp_FR_Flt 10500;
BA_ "GenSigSNA" SG_ 643 TurnLmp_FR_Flt "0h";
BA_ "GenSigSendType" SG_ 643 TurnLmp_FR_Flt 5;
BA_ "GenSigCycleTime" SG_ 643 TurnLmp_FR_Flt 1000;
BA_ "FlexKomSigStartValue" SG_ 643 TurnLmp_FR_Flt "00h";
BA_ "FlexKomSigStartPos" SG_ 643 TurnLmp_FR_Flt 14;
BA_ "FlexKomSigName" SG_ 643 TurnLmp_FR_Flt "TurnLmp_F_Flt";
BA_ "FlexKomSigLaenge" SG_ 643 TurnLmp_FR_Flt 2;
BA_ "FlexKomSID" SG_ 643 TurnLmp_FR_Flt 973;
BA_ "FlexKomIsMotorola" SG_ 643 TurnLmp_FR_Flt 1;
BA_ "FlexKomComment" SG_ 643 TurnLmp_FR_Flt "Turn indication lamp front fault";
BA_ "GenSigTimeout_IC" SG_ 643 TurnLmp_RL_Flt 10500;
BA_ "GenSigSNA" SG_ 643 TurnLmp_RL_Flt "0h";
BA_ "GenSigSendType" SG_ 643 TurnLmp_RL_Flt 5;
BA_ "GenSigCycleTime" SG_ 643 TurnLmp_RL_Flt 1000;
BA_ "FlexKomSigStartValue" SG_ 643 TurnLmp_RL_Flt "00h";
BA_ "FlexKomSigStartPos" SG_ 643 TurnLmp_RL_Flt 25;
BA_ "FlexKomSigName" SG_ 643 TurnLmp_RL_Flt "TurnLmp_R_Flt";
BA_ "FlexKomSigLaenge" SG_ 643 TurnLmp_RL_Flt 2;
BA_ "FlexKomSID" SG_ 643 TurnLmp_RL_Flt 1033;
BA_ "FlexKomIsMotorola" SG_ 643 TurnLmp_RL_Flt 1;
BA_ "FlexKomComment" SG_ 643 TurnLmp_RL_Flt "Turn indication lamp rear fault";
BA_ "GenSigTimeout_IC" SG_ 643 TurnLmp_RR_Flt 10500;
BA_ "GenSigSNA" SG_ 643 TurnLmp_RR_Flt "0h";
BA_ "GenSigSendType" SG_ 643 TurnLmp_RR_Flt 5;
BA_ "GenSigCycleTime" SG_ 643 TurnLmp_RR_Flt 1000;
BA_ "FlexKomSigStartValue" SG_ 643 TurnLmp_RR_Flt "00h";
BA_ "FlexKomSigStartPos" SG_ 643 TurnLmp_RR_Flt 25;
BA_ "FlexKomSigName" SG_ 643 TurnLmp_RR_Flt "TurnLmp_R_Flt";
BA_ "FlexKomSigLaenge" SG_ 643 TurnLmp_RR_Flt 2;
BA_ "FlexKomSID" SG_ 643 TurnLmp_RR_Flt 1033;
BA_ "FlexKomIsMotorola" SG_ 643 TurnLmp_RR_Flt 1;
BA_ "FlexKomComment" SG_ 643 TurnLmp_RR_Flt "Turn indication lamp rear fault";
BA_ "GenSigTimeout_SCCM" SG_ 643 ACC_DLY_ACT 10500;
BA_ "GenSigTimeout_IC" SG_ 643 ACC_DLY_ACT 10500;
BA_ "GenSigSNA" SG_ 643 ACC_DLY_ACT "0h";
BA_ "GenSigSendType" SG_ 643 ACC_DLY_ACT 5;
BA_ "GenSigCycleTime" SG_ 643 ACC_DLY_ACT 1000;
BA_ "FlexKomSigStartValue" SG_ 643 ACC_DLY_ACT "00h";
BA_ "FlexKomSigStartPos" SG_ 643 ACC_DLY_ACT 26;
BA_ "FlexKomSigName" SG_ 643 ACC_DLY_ACT "ACC_DLY_ACT";
BA_ "FlexKomSigLaenge" SG_ 643 ACC_DLY_ACT 1;
BA_ "FlexKomSID" SG_ 643 ACC_DLY_ACT 841;
BA_ "FlexKomIsMotorola" SG_ 643 ACC_DLY_ACT 1;
BA_ "FlexKomComment" SG_ 643 ACC_DLY_ACT "Accessory Delay Active";
BA_ "GenSigStartValue" SG_ 643 WPR_SYS_OFF 1;
BA_ "GenSigSNA" SG_ 643 WPR_SYS_OFF "1h";
BA_ "GenSigCycleTime" SG_ 643 WPR_SYS_OFF 1000;
BA_ "FlexKomSigStartValue" SG_ 643 WPR_SYS_OFF "01h";
BA_ "FlexKomSigStartPos" SG_ 643 WPR_SYS_OFF 47;
BA_ "FlexKomSigName" SG_ 643 WPR_SYS_OFF "WPR_SYS_STAT";
BA_ "FlexKomSigLaenge" SG_ 643 WPR_SYS_OFF 8;
BA_ "FlexKomSID" SG_ 643 WPR_SYS_OFF 1048;
BA_ "FlexKomIsMotorola" SG_ 643 WPR_SYS_OFF 1;
BA_ "FlexKomComment" SG_ 643 WPR_SYS_OFF "Wiper System Status";
BA_ "GenSigSNA" SG_ 643 WPR_SYS_LOW "0h";
BA_ "GenSigCycleTime" SG_ 643 WPR_SYS_LOW 1000;
BA_ "FlexKomSigStartValue" SG_ 643 WPR_SYS_LOW "01h";
BA_ "FlexKomSigStartPos" SG_ 643 WPR_SYS_LOW 47;
BA_ "FlexKomSigName" SG_ 643 WPR_SYS_LOW "WPR_SYS_STAT";
BA_ "FlexKomSigLaenge" SG_ 643 WPR_SYS_LOW 8;
BA_ "FlexKomSID" SG_ 643 WPR_SYS_LOW 1048;
BA_ "FlexKomIsMotorola" SG_ 643 WPR_SYS_LOW 1;
BA_ "FlexKomComment" SG_ 643 WPR_SYS_LOW "Wiper System Status";
BA_ "GenSigSNA" SG_ 643 WPR_SYS_HIGH "0h";
BA_ "GenSigCycleTime" SG_ 643 WPR_SYS_HIGH 1000;
BA_ "FlexKomSigStartValue" SG_ 643 WPR_SYS_HIGH "01h";
BA_ "FlexKomSigStartPos" SG_ 643 WPR_SYS_HIGH 47;
BA_ "FlexKomSigName" SG_ 643 WPR_SYS_HIGH "WPR_SYS_STAT";
BA_ "FlexKomSigLaenge" SG_ 643 WPR_SYS_HIGH 8;
BA_ "FlexKomSID" SG_ 643 WPR_SYS_HIGH 1048;
BA_ "FlexKomIsMotorola" SG_ 643 WPR_SYS_HIGH 1;
BA_ "FlexKomComment" SG_ 643 WPR_SYS_HIGH "Wiper System Status";
BA_ "GenSigSNA" SG_ 643 WPR_SYS_INT "0h";
BA_ "GenSigCycleTime" SG_ 643 WPR_SYS_INT 1000;
BA_ "FlexKomSigStartValue" SG_ 643 WPR_SYS_INT "01h";
BA_ "FlexKomSigStartPos" SG_ 643 WPR_SYS_INT 47;
BA_ "FlexKomSigName" SG_ 643 WPR_SYS_INT "WPR_SYS_STAT";
BA_ "FlexKomSigLaenge" SG_ 643 WPR_SYS_INT 8;
BA_ "FlexKomSID" SG_ 643 WPR_SYS_INT 1048;
BA_ "FlexKomIsMotorola" SG_ 643 WPR_SYS_INT 1;
BA_ "FlexKomComment" SG_ 643 WPR_SYS_INT "Wiper System Status";
BA_ "GenSigSNA" SG_ 643 WPR_SYS_AUTO "0h";
BA_ "GenSigCycleTime" SG_ 643 WPR_SYS_AUTO 1000;
BA_ "FlexKomSigStartValue" SG_ 643 WPR_SYS_AUTO "01h";
BA_ "FlexKomSigStartPos" SG_ 643 WPR_SYS_AUTO 47;
BA_ "FlexKomSigName" SG_ 643 WPR_SYS_AUTO "WPR_SYS_STAT";
BA_ "FlexKomSigLaenge" SG_ 643 WPR_SYS_AUTO 8;
BA_ "FlexKomSID" SG_ 643 WPR_SYS_AUTO 1048;
BA_ "FlexKomIsMotorola" SG_ 643 WPR_SYS_AUTO 1;
BA_ "FlexKomComment" SG_ 643 WPR_SYS_AUTO "Wiper System Status";
BA_ "GenSigSNA" SG_ 643 WPR_SYS_MIST "0h";
BA_ "GenSigCycleTime" SG_ 643 WPR_SYS_MIST 1000;
BA_ "FlexKomSigStartValue" SG_ 643 WPR_SYS_MIST "01h";
BA_ "FlexKomSigStartPos" SG_ 643 WPR_SYS_MIST 47;
BA_ "FlexKomSigName" SG_ 643 WPR_SYS_MIST "WPR_SYS_STAT";
BA_ "FlexKomSigLaenge" SG_ 643 WPR_SYS_MIST 8;
BA_ "FlexKomSID" SG_ 643 WPR_SYS_MIST 1048;
BA_ "FlexKomIsMotorola" SG_ 643 WPR_SYS_MIST 1;
BA_ "FlexKomComment" SG_ 643 WPR_SYS_MIST "Wiper System Status";
BA_ "GenSigSNA" SG_ 643 WPR_SYS_WASH "0h";
BA_ "GenSigCycleTime" SG_ 643 WPR_SYS_WASH 1000;
BA_ "FlexKomSigStartValue" SG_ 643 WPR_SYS_WASH "01h";
BA_ "FlexKomSigStartPos" SG_ 643 WPR_SYS_WASH 47;
BA_ "FlexKomSigName" SG_ 643 WPR_SYS_WASH "WPR_SYS_STAT";
BA_ "FlexKomSigLaenge" SG_ 643 WPR_SYS_WASH 8;
BA_ "FlexKomSID" SG_ 643 WPR_SYS_WASH 1048;
BA_ "FlexKomIsMotorola" SG_ 643 WPR_SYS_WASH 1;
BA_ "FlexKomComment" SG_ 643 WPR_SYS_WASH "Wiper System Status";
BA_ "GenSigSNA" SG_ 643 WPR_SYS_FLT "0h";
BA_ "GenSigCycleTime" SG_ 643 WPR_SYS_FLT 1000;
BA_ "FlexKomSigStartValue" SG_ 643 WPR_SYS_FLT "01h";
BA_ "FlexKomSigStartPos" SG_ 643 WPR_SYS_FLT 47;
BA_ "FlexKomSigName" SG_ 643 WPR_SYS_FLT "WPR_SYS_STAT";
BA_ "FlexKomSigLaenge" SG_ 643 WPR_SYS_FLT 8;
BA_ "FlexKomSID" SG_ 643 WPR_SYS_FLT 1048;
BA_ "FlexKomIsMotorola" SG_ 643 WPR_SYS_FLT 1;
BA_ "FlexKomComment" SG_ 643 WPR_SYS_FLT "Wiper System Status";
BA_ "GenSigTimeout_IC" SG_ 643 RemSt_Inhibit 10500;
BA_ "GenSigTimeout_ETM" SG_ 643 RemSt_Inhibit 10500;
BA_ "GenSigSNA" SG_ 643 RemSt_Inhibit "FFh";
BA_ "GenSigSendType" SG_ 643 RemSt_Inhibit 5;
BA_ "GenSigCycleTime" SG_ 643 RemSt_Inhibit 1000;
BA_ "FlexKomSigStartValue" SG_ 643 RemSt_Inhibit "00h";
BA_ "FlexKomSigStartPos" SG_ 643 RemSt_Inhibit 39;
BA_ "FlexKomSigName" SG_ 643 RemSt_Inhibit "RemSt_Inhibit";
BA_ "FlexKomSigLaenge" SG_ 643 RemSt_Inhibit 8;
BA_ "FlexKomSID" SG_ 643 RemSt_Inhibit 1047;
BA_ "FlexKomIsMotorola" SG_ 643 RemSt_Inhibit 1;
BA_ "FlexKomComment" SG_ 643 RemSt_Inhibit "Remote start inhibit";
BA_ "RID" SG_ 649 TRAC_PSD "1155";
BA_ "GenSigSNA" SG_ 649 TRAC_PSD "0h";
BA_ "GenSigSendType" SG_ 649 TRAC_PSD 5;
BA_ "GenSigCycleTime" SG_ 649 TRAC_PSD 1000;
BA_ "FlexKomSigStartValue" SG_ 649 TRAC_PSD "00h";
BA_ "FlexKomSigStartPos" SG_ 649 TRAC_PSD 19;
BA_ "FlexKomSigName" SG_ 649 TRAC_PSD "TRAC_PSD";
BA_ "FlexKomSigLaenge" SG_ 649 TRAC_PSD 1;
BA_ "FlexKomSID" SG_ 649 TRAC_PSD 424;
BA_ "FlexKomIsMotorola" SG_ 649 TRAC_PSD 1;
BA_ "FlexKomComment" SG_ 649 TRAC_PSD "Traction on/off button pressed; [0] = Not Pressed,";
BA_ "RID" SG_ 649 phone_pop_up_active "3052";
BA_ "GenSigTimeout_IC" SG_ 649 phone_pop_up_active 10500;
BA_ "GenSigSNA" SG_ 649 phone_pop_up_active "0h";
BA_ "GenSigSendType" SG_ 649 phone_pop_up_active 5;
BA_ "GenSigCycleTime" SG_ 649 phone_pop_up_active 1000;
BA_ "FlexKomSigStartValue" SG_ 649 phone_pop_up_active "00h";
BA_ "FlexKomSigStartPos" SG_ 649 phone_pop_up_active 30;
BA_ "FlexKomSigName" SG_ 649 phone_pop_up_active "phone_pop_up_active";
BA_ "FlexKomSigLaenge" SG_ 649 phone_pop_up_active 1;
BA_ "FlexKomSID" SG_ 649 phone_pop_up_active 2527;
BA_ "FlexKomIsMotorola" SG_ 649 phone_pop_up_active 1;
BA_ "FlexKomComment" SG_ 649 phone_pop_up_active "Phone pop up is active; True = [1]";
BA_ "GenSigTimeout_IC" SG_ 649 AHB_ENBL 10500;
BA_ "GenSigSNA" SG_ 649 AHB_ENBL "0h";
BA_ "GenSigSendType" SG_ 649 AHB_ENBL 5;
BA_ "GenSigCycleTime" SG_ 649 AHB_ENBL 1000;
BA_ "FlexKomSigStartValue" SG_ 649 AHB_ENBL "00h";
BA_ "FlexKomSigStartPos" SG_ 649 AHB_ENBL 36;
BA_ "FlexKomSigName" SG_ 649 AHB_ENBL "AHB_ENBL";
BA_ "FlexKomSigLaenge" SG_ 649 AHB_ENBL 1;
BA_ "FlexKomSID" SG_ 649 AHB_ENBL 733;
BA_ "FlexKomIsMotorola" SG_ 649 AHB_ENBL 1;
BA_ "FlexKomComment" SG_ 649 AHB_ENBL "Auto highbeam enable";
BA_ "RID" SG_ 649 HVAC_CLNT_FLW_MIN "2885";
BA_ "GenSigStartValue" SG_ 649 HVAC_CLNT_FLW_MIN 255;
BA_ "GenSigSNA" SG_ 649 HVAC_CLNT_FLW_MIN "FFh";
BA_ "GenSigSendType" SG_ 649 HVAC_CLNT_FLW_MIN 5;
BA_ "GenSigCycleTime" SG_ 649 HVAC_CLNT_FLW_MIN 1000;
BA_ "FlexKomSigStartValue" SG_ 649 HVAC_CLNT_FLW_MIN "FFh";
BA_ "FlexKomSigStartPos" SG_ 649 HVAC_CLNT_FLW_MIN 47;
BA_ "FlexKomSigName" SG_ 649 HVAC_CLNT_FLW_MIN "HVAC_CLNT_FLW_MIN";
BA_ "FlexKomSigLaenge" SG_ 649 HVAC_CLNT_FLW_MIN 8;
BA_ "FlexKomSID" SG_ 649 HVAC_CLNT_FLW_MIN 1527;
BA_ "FlexKomIsMotorola" SG_ 649 HVAC_CLNT_FLW_MIN 1;
BA_ "FlexKomComment" SG_ 649 HVAC_CLNT_FLW_MIN "HVAC coolant flow minimum request";
BA_ "RID" SG_ 649 ICS_btn_17 "2096";
BA_ "GenSigSNA" SG_ 649 ICS_btn_17 "0h";
BA_ "GenSigSendType" SG_ 649 ICS_btn_17 5;
BA_ "GenSigCycleTime" SG_ 649 ICS_btn_17 1000;
BA_ "FlexKomSigStartValue" SG_ 649 ICS_btn_17 "00h";
BA_ "FlexKomSigStartPos" SG_ 649 ICS_btn_17 52;
BA_ "FlexKomSigName" SG_ 649 ICS_btn_17 "ICS_btn_17";
BA_ "FlexKomSigLaenge" SG_ 649 ICS_btn_17 1;
BA_ "FlexKomSID" SG_ 649 ICS_btn_17 1840;
BA_ "FlexKomIsMotorola" SG_ 649 ICS_btn_17 1;
BA_ "FlexKomComment" SG_ 649 ICS_btn_17 "PTS Off pressed";
BA_ "RID" SG_ 650 SS_Stat_Left "6531";
BA_ "GenSigStartValue" SG_ 650 SS_Stat_Left 7;
BA_ "GenSigSNA" SG_ 650 SS_Stat_Left "7h";
BA_ "GenSigSendType" SG_ 650 SS_Stat_Left 5;
BA_ "GenSigCycleTime" SG_ 650 SS_Stat_Left 1000;
BA_ "FlexKomSigStartValue" SG_ 650 SS_Stat_Left "00000000003F0000h";
BA_ "FlexKomSigStartPos" SG_ 650 SS_Stat_Left 7;
BA_ "FlexKomSigName" SG_ 650 SS_Stat_Left "GW_I_C2_pkt";
BA_ "FlexKomSigLaenge" SG_ 650 SS_Stat_Left 64;
BA_ "FlexKomSID" SG_ 650 SS_Stat_Left 2784;
BA_ "FlexKomIsMotorola" SG_ 650 SS_Stat_Left 1;
BA_ "FlexKomComment" SG_ 650 SS_Stat_Left "GW_I_C2 packet";
BA_ "RID" SG_ 650 SS_Stat_Right "6530";
BA_ "GenSigStartValue" SG_ 650 SS_Stat_Right 7;
BA_ "GenSigSNA" SG_ 650 SS_Stat_Right "7h";
BA_ "GenSigSendType" SG_ 650 SS_Stat_Right 5;
BA_ "GenSigCycleTime" SG_ 650 SS_Stat_Right 1000;
BA_ "FlexKomSigStartValue" SG_ 650 SS_Stat_Right "00000000003F0000h";
BA_ "FlexKomSigStartPos" SG_ 650 SS_Stat_Right 7;
BA_ "FlexKomSigName" SG_ 650 SS_Stat_Right "GW_I_C2_pkt";
BA_ "FlexKomSigLaenge" SG_ 650 SS_Stat_Right 64;
BA_ "FlexKomSID" SG_ 650 SS_Stat_Right 2784;
BA_ "FlexKomIsMotorola" SG_ 650 SS_Stat_Right 1;
BA_ "FlexKomComment" SG_ 650 SS_Stat_Right "GW_I_C2 packet";
BA_ "RID" SG_ 650 ChargeNow "6625";
BA_ "GenSigSNA" SG_ 650 ChargeNow "0";
BA_ "GenSigSendType" SG_ 650 ChargeNow 5;
BA_ "GenSigCycleTime" SG_ 650 ChargeNow 1000;
BA_ "FlexKomSigStartValue" SG_ 650 ChargeNow "00000000003F0000h";
BA_ "FlexKomSigStartPos" SG_ 650 ChargeNow 7;
BA_ "FlexKomSigName" SG_ 650 ChargeNow "GW_I_C2_pkt";
BA_ "FlexKomSigLaenge" SG_ 650 ChargeNow 64;
BA_ "FlexKomSID" SG_ 650 ChargeNow 2784;
BA_ "FlexKomIsMotorola" SG_ 650 ChargeNow 1;
BA_ "FlexKomComment" SG_ 650 ChargeNow "GW_I_C2 packet";
BA_ "RID" SG_ 650 ChargeNow_TBM "6682";
BA_ "GenSigSNA" SG_ 650 ChargeNow_TBM "0";
BA_ "GenSigSendType" SG_ 650 ChargeNow_TBM 5;
BA_ "GenSigCycleTime" SG_ 650 ChargeNow_TBM 1000;
BA_ "FlexKomSigStartValue" SG_ 650 ChargeNow_TBM "00000000003F0000h";
BA_ "FlexKomSigStartPos" SG_ 650 ChargeNow_TBM 7;
BA_ "FlexKomSigName" SG_ 650 ChargeNow_TBM "GW_I_C2_pkt";
BA_ "FlexKomSigLaenge" SG_ 650 ChargeNow_TBM 64;
BA_ "FlexKomSID" SG_ 650 ChargeNow_TBM 2784;
BA_ "FlexKomIsMotorola" SG_ 650 ChargeNow_TBM 1;
BA_ "FlexKomComment" SG_ 650 ChargeNow_TBM "GW_I_C2 packet";
BA_ "RID" SG_ 650 PreCondCabinSts "6714";
BA_ "GenSigSNA" SG_ 650 PreCondCabinSts "3h";
BA_ "GenSigSendType" SG_ 650 PreCondCabinSts 5;
BA_ "GenSigCycleTime" SG_ 650 PreCondCabinSts 1000;
BA_ "FlexKomSigStartValue" SG_ 650 PreCondCabinSts "00000000003F0000h";
BA_ "FlexKomSigStartPos" SG_ 650 PreCondCabinSts 7;
BA_ "FlexKomSigName" SG_ 650 PreCondCabinSts "GW_I_C2_pkt";
BA_ "FlexKomSigLaenge" SG_ 650 PreCondCabinSts 64;
BA_ "FlexKomSID" SG_ 650 PreCondCabinSts 2784;
BA_ "FlexKomIsMotorola" SG_ 650 PreCondCabinSts 1;
BA_ "FlexKomComment" SG_ 650 PreCondCabinSts "GW_I_C2 packet";
BA_ "RID" SG_ 650 SOSFailSts "6841";
BA_ "GenSigSNA" SG_ 650 SOSFailSts "0h";
BA_ "GenSigSendType" SG_ 650 SOSFailSts 5;
BA_ "GenSigCycleTime" SG_ 650 SOSFailSts 1000;
BA_ "FlexKomSigStartValue" SG_ 650 SOSFailSts "00000000003F0000h";
BA_ "FlexKomSigStartPos" SG_ 650 SOSFailSts 7;
BA_ "FlexKomSigName" SG_ 650 SOSFailSts "GW_I_C2_pkt";
BA_ "FlexKomSigLaenge" SG_ 650 SOSFailSts 64;
BA_ "FlexKomSID" SG_ 650 SOSFailSts 2784;
BA_ "FlexKomIsMotorola" SG_ 650 SOSFailSts 1;
BA_ "FlexKomComment" SG_ 650 SOSFailSts "GW_I_C2 packet";
BA_ "RID" SG_ 651 HILL_DES_RQ_ICS "5077";
BA_ "GenSigSNA" SG_ 651 HILL_DES_RQ_ICS "3h";
BA_ "GenSigSendType" SG_ 651 HILL_DES_RQ_ICS 5;
BA_ "GenSigCycleTime" SG_ 651 HILL_DES_RQ_ICS 1000;
BA_ "FlexKomSigStartValue" SG_ 651 HILL_DES_RQ_ICS "00h";
BA_ "FlexKomSigStartPos" SG_ 651 HILL_DES_RQ_ICS 50;
BA_ "FlexKomSigName" SG_ 651 HILL_DES_RQ_ICS "HILL_DES_RQ_ICS";
BA_ "FlexKomSigLaenge" SG_ 651 HILL_DES_RQ_ICS 2;
BA_ "FlexKomSID" SG_ 651 HILL_DES_RQ_ICS 2638;
BA_ "FlexKomIsMotorola" SG_ 651 HILL_DES_RQ_ICS 1;
BA_ "FlexKomComment" SG_ 651 HILL_DES_RQ_ICS "Hill descent or select speed status";
BA_ "GenSigSNA" SG_ 656 UConnSeed1 "0h";
BA_ "GenSigSendType" SG_ 656 UConnSeed1 1;
BA_ "FlexKomSigStartValue" SG_ 656 UConnSeed1 "00000000h";
BA_ "FlexKomSigStartPos" SG_ 656 UConnSeed1 7;
BA_ "FlexKomSigName" SG_ 656 UConnSeed1 "RF_CharPkt";
BA_ "FlexKomSigLaenge" SG_ 656 UConnSeed1 32;
BA_ "FlexKomSID" SG_ 656 UConnSeed1 1794;
BA_ "FlexKomIsMotorola" SG_ 656 UConnSeed1 1;
BA_ "FlexKomComment" SG_ 656 UConnSeed1 "RF hub characters";
BA_ "GenSigSNA" SG_ 656 UConnSeed2 "0h";
BA_ "GenSigSendType" SG_ 656 UConnSeed2 1;
BA_ "FlexKomSigStartValue" SG_ 656 UConnSeed2 "00000000h";
BA_ "FlexKomSigStartPos" SG_ 656 UConnSeed2 7;
BA_ "FlexKomSigName" SG_ 656 UConnSeed2 "RF_CharPkt";
BA_ "FlexKomSigLaenge" SG_ 656 UConnSeed2 32;
BA_ "FlexKomSID" SG_ 656 UConnSeed2 1794;
BA_ "FlexKomIsMotorola" SG_ 656 UConnSeed2 1;
BA_ "FlexKomComment" SG_ 656 UConnSeed2 "RF hub characters";
BA_ "GenSigSNA" SG_ 656 UConnSeed3 "0h";
BA_ "GenSigSendType" SG_ 656 UConnSeed3 1;
BA_ "FlexKomSigStartValue" SG_ 656 UConnSeed3 "00000000h";
BA_ "FlexKomSigStartPos" SG_ 656 UConnSeed3 7;
BA_ "FlexKomSigName" SG_ 656 UConnSeed3 "RF_CharPkt";
BA_ "FlexKomSigLaenge" SG_ 656 UConnSeed3 32;
BA_ "FlexKomSID" SG_ 656 UConnSeed3 1794;
BA_ "FlexKomIsMotorola" SG_ 656 UConnSeed3 1;
BA_ "FlexKomComment" SG_ 656 UConnSeed3 "RF hub characters";
BA_ "GenSigSNA" SG_ 656 UConnSeed4 "0h";
BA_ "GenSigSendType" SG_ 656 UConnSeed4 1;
BA_ "FlexKomSigStartValue" SG_ 656 UConnSeed4 "00000000h";
BA_ "FlexKomSigStartPos" SG_ 656 UConnSeed4 7;
BA_ "FlexKomSigName" SG_ 656 UConnSeed4 "RF_CharPkt";
BA_ "FlexKomSigLaenge" SG_ 656 UConnSeed4 32;
BA_ "FlexKomSID" SG_ 656 UConnSeed4 1794;
BA_ "FlexKomIsMotorola" SG_ 656 UConnSeed4 1;
BA_ "FlexKomComment" SG_ 656 UConnSeed4 "RF hub characters";
BA_ "GenSigTimeout_IC" SG_ 657 FT_FOG_RQ 10500;
BA_ "GenSigSNA" SG_ 657 FT_FOG_RQ "0h";
BA_ "GenSigSendType" SG_ 657 FT_FOG_RQ 5;
BA_ "GenSigCycleTime" SG_ 657 FT_FOG_RQ 1000;
BA_ "FlexKomSigStartValue" SG_ 657 FT_FOG_RQ "00h";
BA_ "FlexKomSigStartPos" SG_ 657 FT_FOG_RQ 2;
BA_ "FlexKomSigName" SG_ 657 FT_FOG_RQ "FT_FOG_RQ";
BA_ "FlexKomSigLaenge" SG_ 657 FT_FOG_RQ 1;
BA_ "FlexKomSID" SG_ 657 FT_FOG_RQ 758;
BA_ "FlexKomIsMotorola" SG_ 657 FT_FOG_RQ 1;
BA_ "FlexKomComment" SG_ 657 FT_FOG_RQ "Front fog request; off=[0], on=[1]";
BA_ "GenSigTimeout_IC" SG_ 657 R_FOG_RQ 10500;
BA_ "GenSigSNA" SG_ 657 R_FOG_RQ "0h";
BA_ "GenSigSendType" SG_ 657 R_FOG_RQ 5;
BA_ "GenSigCycleTime" SG_ 657 R_FOG_RQ 1000;
BA_ "FlexKomSigStartValue" SG_ 657 R_FOG_RQ "00h";
BA_ "FlexKomSigStartPos" SG_ 657 R_FOG_RQ 3;
BA_ "FlexKomSigName" SG_ 657 R_FOG_RQ "R_FOG_RQ";
BA_ "FlexKomSigLaenge" SG_ 657 R_FOG_RQ 1;
BA_ "FlexKomSID" SG_ 657 R_FOG_RQ 427;
BA_ "FlexKomIsMotorola" SG_ 657 R_FOG_RQ 1;
BA_ "FlexKomComment" SG_ 657 R_FOG_RQ "Rear fog request; [0] = off, [1] = on";
BA_ "GenSigTimeout_RF_HUB" SG_ 657 REV_GEAR 10500;
BA_ "GenSigTimeout_PTS" SG_ 657 REV_GEAR 3500;
BA_ "GenSigTimeout_ORC" SG_ 657 REV_GEAR 3500;
BA_ "GenSigTimeout_IC" SG_ 657 REV_GEAR 10500;
BA_ "GenSigSNA" SG_ 657 REV_GEAR "0h";
BA_ "GenSigSendType" SG_ 657 REV_GEAR 5;
BA_ "GenSigCycleTime" SG_ 657 REV_GEAR 1000;
BA_ "FlexKomSigStartValue" SG_ 657 REV_GEAR "00h";
BA_ "FlexKomSigStartPos" SG_ 657 REV_GEAR 4;
BA_ "FlexKomSigName" SG_ 657 REV_GEAR "REV_GEAR";
BA_ "FlexKomSigLaenge" SG_ 657 REV_GEAR 1;
BA_ "FlexKomSID" SG_ 657 REV_GEAR 685;
BA_ "FlexKomIsMotorola" SG_ 657 REV_GEAR 1;
BA_ "FlexKomComment" SG_ 657 REV_GEAR "Reverse Gear (manual trans)";
BA_ "GenSigTimeout_RF_HUB" SG_ 657 DR_LK_STAT 10500;
BA_ "GenSigTimeout_IC" SG_ 657 DR_LK_STAT 10500;
BA_ "GenSigStartValue" SG_ 657 DR_LK_STAT 3;
BA_ "GenSigSNA" SG_ 657 DR_LK_STAT "3h";
BA_ "GenSigSendType" SG_ 657 DR_LK_STAT 5;
BA_ "GenSigCycleTime" SG_ 657 DR_LK_STAT 1000;
BA_ "FlexKomSigStartValue" SG_ 657 DR_LK_STAT "03h";
BA_ "FlexKomSigStartPos" SG_ 657 DR_LK_STAT 6;
BA_ "FlexKomSigName" SG_ 657 DR_LK_STAT "DR_LK_STAT";
BA_ "FlexKomSigLaenge" SG_ 657 DR_LK_STAT 2;
BA_ "FlexKomSID" SG_ 657 DR_LK_STAT 861;
BA_ "FlexKomIsMotorola" SG_ 657 DR_LK_STAT 1;
BA_ "FlexKomComment" SG_ 657 DR_LK_STAT "Door lock status";
BA_ "GenSigTimeout_RF_HUB" SG_ 657 FOB_SrchRq 5500;
BA_ "GenSigSNA" SG_ 657 FOB_SrchRq "0h";
BA_ "GenSigSendType" SG_ 657 FOB_SrchRq 5;
BA_ "GenSigCycleTime" SG_ 657 FOB_SrchRq 1000;
BA_ "FlexKomSigStartValue" SG_ 657 FOB_SrchRq "00h";
BA_ "FlexKomSigStartPos" SG_ 657 FOB_SrchRq 9;
BA_ "FlexKomSigName" SG_ 657 FOB_SrchRq "FOB_SrchRq";
BA_ "FlexKomSigLaenge" SG_ 657 FOB_SrchRq 2;
BA_ "FlexKomSID" SG_ 657 FOB_SrchRq 1392;
BA_ "FlexKomIsMotorola" SG_ 657 FOB_SrchRq 1;
BA_ "FlexKomComment" SG_ 657 FOB_SrchRq "FOB search request";
BA_ "RID" SG_ 657 AHB_ACT "971";
BA_ "GenSigTimeout_IC" SG_ 657 AHB_ACT 10500;
BA_ "GenSigSNA" SG_ 657 AHB_ACT "0h";
BA_ "GenSigSendType" SG_ 657 AHB_ACT 5;
BA_ "GenSigCycleTime" SG_ 657 AHB_ACT 1000;
BA_ "FlexKomSigStartValue" SG_ 657 AHB_ACT "00h";
BA_ "FlexKomSigStartPos" SG_ 657 AHB_ACT 14;
BA_ "FlexKomSigName" SG_ 657 AHB_ACT "AHB_ACT";
BA_ "FlexKomSigLaenge" SG_ 657 AHB_ACT 1;
BA_ "FlexKomSID" SG_ 657 AHB_ACT 732;
BA_ "FlexKomIsMotorola" SG_ 657 AHB_ACT 1;
BA_ "FlexKomComment" SG_ 657 AHB_ACT "Automatic high beam active";
BA_ "GenSigTimeout_IC" SG_ 657 PARK_LMP_ON 10500;
BA_ "GenSigSNA" SG_ 657 PARK_LMP_ON "0h";
BA_ "GenSigSendType" SG_ 657 PARK_LMP_ON 5;
BA_ "GenSigCycleTime" SG_ 657 PARK_LMP_ON 1000;
BA_ "FlexKomSigStartValue" SG_ 657 PARK_LMP_ON "00h";
BA_ "FlexKomSigStartPos" SG_ 657 PARK_LMP_ON 16;
BA_ "FlexKomSigName" SG_ 657 PARK_LMP_ON "PARK_LMP_ON";
BA_ "FlexKomSigLaenge" SG_ 657 PARK_LMP_ON 1;
BA_ "FlexKomSID" SG_ 657 PARK_LMP_ON 767;
BA_ "FlexKomIsMotorola" SG_ 657 PARK_LMP_ON 1;
BA_ "FlexKomComment" SG_ 657 PARK_LMP_ON "Parklamps are on; off=[0], on=[1]";
BA_ "GenSigTimeout_TBM" SG_ 657 DRV_AJAR 10500;
BA_ "GenSigTimeout_RF_HUB" SG_ 657 DRV_AJAR 10500;
BA_ "GenSigTimeout_IC" SG_ 657 DRV_AJAR 10500;
BA_ "GenSigSNA" SG_ 657 DRV_AJAR "0h";
BA_ "GenSigSendType" SG_ 657 DRV_AJAR 5;
BA_ "GenSigCycleTime" SG_ 657 DRV_AJAR 1000;
BA_ "FlexKomSigStartValue" SG_ 657 DRV_AJAR "00h";
BA_ "FlexKomSigStartPos" SG_ 657 DRV_AJAR 22;
BA_ "FlexKomSigName" SG_ 657 DRV_AJAR "DR_AJAR";
BA_ "FlexKomSigLaenge" SG_ 657 DRV_AJAR 6;
BA_ "FlexKomSID" SG_ 657 DRV_AJAR 797;
BA_ "FlexKomIsMotorola" SG_ 657 DRV_AJAR 1;
BA_ "FlexKomComment" SG_ 657 DRV_AJAR "Door ajar";
BA_ "GenSigTimeout_TBM" SG_ 657 PSG_AJAR 10500;
BA_ "GenSigTimeout_RF_HUB" SG_ 657 PSG_AJAR 10500;
BA_ "GenSigTimeout_ORC" SG_ 657 PSG_AJAR 3500;
BA_ "GenSigTimeout_IC" SG_ 657 PSG_AJAR 10500;
BA_ "GenSigSNA" SG_ 657 PSG_AJAR "0h";
BA_ "GenSigSendType" SG_ 657 PSG_AJAR 5;
BA_ "GenSigCycleTime" SG_ 657 PSG_AJAR 1000;
BA_ "FlexKomSigStartValue" SG_ 657 PSG_AJAR "00h";
BA_ "FlexKomSigStartPos" SG_ 657 PSG_AJAR 22;
BA_ "FlexKomSigName" SG_ 657 PSG_AJAR "DR_AJAR";
BA_ "FlexKomSigLaenge" SG_ 657 PSG_AJAR 6;
BA_ "FlexKomSID" SG_ 657 PSG_AJAR 797;
BA_ "FlexKomIsMotorola" SG_ 657 PSG_AJAR 1;
BA_ "FlexKomComment" SG_ 657 PSG_AJAR "Door ajar";
BA_ "GenSigTimeout_TBM" SG_ 657 L_R_AJAR 10500;
BA_ "GenSigTimeout_RF_HUB" SG_ 657 L_R_AJAR 10500;
BA_ "GenSigTimeout_IC" SG_ 657 L_R_AJAR 10500;
BA_ "GenSigSNA" SG_ 657 L_R_AJAR "0h";
BA_ "GenSigSendType" SG_ 657 L_R_AJAR 5;
BA_ "GenSigCycleTime" SG_ 657 L_R_AJAR 1000;
BA_ "FlexKomSigStartValue" SG_ 657 L_R_AJAR "00h";
BA_ "FlexKomSigStartPos" SG_ 657 L_R_AJAR 22;
BA_ "FlexKomSigName" SG_ 657 L_R_AJAR "DR_AJAR";
BA_ "FlexKomSigLaenge" SG_ 657 L_R_AJAR 6;
BA_ "FlexKomSID" SG_ 657 L_R_AJAR 797;
BA_ "FlexKomIsMotorola" SG_ 657 L_R_AJAR 1;
BA_ "FlexKomComment" SG_ 657 L_R_AJAR "Door ajar";
BA_ "GenSigTimeout_TBM" SG_ 657 R_R_AJAR 10500;
BA_ "GenSigTimeout_RF_HUB" SG_ 657 R_R_AJAR 10500;
BA_ "GenSigTimeout_IC" SG_ 657 R_R_AJAR 10500;
BA_ "GenSigSNA" SG_ 657 R_R_AJAR "0h";
BA_ "GenSigSendType" SG_ 657 R_R_AJAR 5;
BA_ "GenSigCycleTime" SG_ 657 R_R_AJAR 1000;
BA_ "FlexKomSigStartValue" SG_ 657 R_R_AJAR "00h";
BA_ "FlexKomSigStartPos" SG_ 657 R_R_AJAR 22;
BA_ "FlexKomSigName" SG_ 657 R_R_AJAR "DR_AJAR";
BA_ "FlexKomSigLaenge" SG_ 657 R_R_AJAR 6;
BA_ "FlexKomSID" SG_ 657 R_R_AJAR 797;
BA_ "FlexKomIsMotorola" SG_ 657 R_R_AJAR 1;
BA_ "FlexKomComment" SG_ 657 R_R_AJAR "Door ajar";
BA_ "GenSigTimeout_TBM" SG_ 657 TLG_AJAR 10500;
BA_ "GenSigTimeout_RF_HUB" SG_ 657 TLG_AJAR 10500;
BA_ "GenSigTimeout_IC" SG_ 657 TLG_AJAR 10500;
BA_ "GenSigSNA" SG_ 657 TLG_AJAR "0h";
BA_ "GenSigSendType" SG_ 657 TLG_AJAR 5;
BA_ "GenSigCycleTime" SG_ 657 TLG_AJAR 1000;
BA_ "FlexKomSigStartValue" SG_ 657 TLG_AJAR "00h";
BA_ "FlexKomSigStartPos" SG_ 657 TLG_AJAR 22;
BA_ "FlexKomSigName" SG_ 657 TLG_AJAR "DR_AJAR";
BA_ "FlexKomSigLaenge" SG_ 657 TLG_AJAR 6;
BA_ "FlexKomSID" SG_ 657 TLG_AJAR 797;
BA_ "FlexKomIsMotorola" SG_ 657 TLG_AJAR 1;
BA_ "FlexKomComment" SG_ 657 TLG_AJAR "Door ajar";
BA_ "GenSigTimeout_RF_HUB" SG_ 657 PARK_BRK_EGD 10500;
BA_ "GenSigTimeout_IC" SG_ 657 PARK_BRK_EGD 10500;
BA_ "GenSigTimeout_DTCM" SG_ 657 PARK_BRK_EGD 10500;
BA_ "GenSigSNA" SG_ 657 PARK_BRK_EGD "0h";
BA_ "GenSigSendType" SG_ 657 PARK_BRK_EGD 5;
BA_ "GenSigCycleTime" SG_ 657 PARK_BRK_EGD 1000;
BA_ "FlexKomSigStartValue" SG_ 657 PARK_BRK_EGD "00h";
BA_ "FlexKomSigStartPos" SG_ 657 PARK_BRK_EGD 23;
BA_ "FlexKomSigName" SG_ 657 PARK_BRK_EGD "PARK_BRK_EGD";
BA_ "FlexKomSigLaenge" SG_ 657 PARK_BRK_EGD 1;
BA_ "FlexKomSID" SG_ 657 PARK_BRK_EGD 805;
BA_ "FlexKomIsMotorola" SG_ 657 PARK_BRK_EGD 1;
BA_ "FlexKomComment" SG_ 657 PARK_BRK_EGD "Park brake switch engaged";
BA_ "GenSigTimeout_RF_HUB" SG_ 657 IGN_OFF_TIME_LNG 10500;
BA_ "GenSigTimeout_IC" SG_ 657 IGN_OFF_TIME_LNG 10500;
BA_ "GenSigTimeout_DTCM" SG_ 657 IGN_OFF_TIME_LNG 10500;
BA_ "GenSigStartValue" SG_ 657 IGN_OFF_TIME_LNG 4095;
BA_ "GenSigSNA" SG_ 657 IGN_OFF_TIME_LNG "FFFh";
BA_ "GenSigSendType" SG_ 657 IGN_OFF_TIME_LNG 5;
BA_ "GenSigCycleTime" SG_ 657 IGN_OFF_TIME_LNG 1000;
BA_ "FlexKomSigStartValue" SG_ 657 IGN_OFF_TIME_LNG "0FFFh";
BA_ "FlexKomSigStartPos" SG_ 657 IGN_OFF_TIME_LNG 31;
BA_ "FlexKomSigName" SG_ 657 IGN_OFF_TIME_LNG "IGN_OFF_TIME_LNG";
BA_ "FlexKomSigLaenge" SG_ 657 IGN_OFF_TIME_LNG 16;
BA_ "FlexKomSID" SG_ 657 IGN_OFF_TIME_LNG 998;
BA_ "FlexKomIsMotorola" SG_ 657 IGN_OFF_TIME_LNG 1;
BA_ "FlexKomComment" SG_ 657 IGN_OFF_TIME_LNG "Time since last ignition on (long)";
BA_ "GenSigTimeout_RF_HUB" SG_ 657 SHIP_STAT 10500;
BA_ "GenSigTimeout_ORC" SG_ 657 SHIP_STAT 3500;
BA_ "GenSigTimeout_IC" SG_ 657 SHIP_STAT 10500;
BA_ "GenSigTimeout_DTCM" SG_ 657 SHIP_STAT 10500;
BA_ "GenSigStartValue" SG_ 657 SHIP_STAT 3;
BA_ "GenSigSNA" SG_ 657 SHIP_STAT "3h";
BA_ "GenSigSendType" SG_ 657 SHIP_STAT 5;
BA_ "GenSigCycleTime" SG_ 657 SHIP_STAT 1000;
BA_ "FlexKomSigStartValue" SG_ 657 SHIP_STAT "03h";
BA_ "FlexKomSigStartPos" SG_ 657 SHIP_STAT 29;
BA_ "FlexKomSigName" SG_ 657 SHIP_STAT "SHIP_STAT";
BA_ "FlexKomSigLaenge" SG_ 657 SHIP_STAT 2;
BA_ "FlexKomSID" SG_ 657 SHIP_STAT 869;
BA_ "FlexKomIsMotorola" SG_ 657 SHIP_STAT 1;
BA_ "FlexKomComment" SG_ 657 SHIP_STAT "Shipping status";
BA_ "GenSigTimeout_PTS" SG_ 657 TurnInd_LT_ON 10500;
BA_ "GenSigTimeout_IC" SG_ 657 TurnInd_LT_ON 10500;
BA_ "GenSigSNA" SG_ 657 TurnInd_LT_ON "0h";
BA_ "GenSigSendType" SG_ 657 TurnInd_LT_ON 5;
BA_ "GenSigCycleTime" SG_ 657 TurnInd_LT_ON 1000;
BA_ "FlexKomSigStartValue" SG_ 657 TurnInd_LT_ON "00h";
BA_ "FlexKomSigStartPos" SG_ 657 TurnInd_LT_ON 31;
BA_ "FlexKomSigName" SG_ 657 TurnInd_LT_ON "TurnInd_STAT";
BA_ "FlexKomSigLaenge" SG_ 657 TurnInd_LT_ON 2;
BA_ "FlexKomSID" SG_ 657 TurnInd_LT_ON 759;
BA_ "FlexKomIsMotorola" SG_ 657 TurnInd_LT_ON 1;
BA_ "FlexKomComment" SG_ 657 TurnInd_LT_ON "Turn indication status";
BA_ "GenSigTimeout_PTS" SG_ 657 TurnInd_RT_ON 10500;
BA_ "GenSigTimeout_IC" SG_ 657 TurnInd_RT_ON 10500;
BA_ "GenSigSNA" SG_ 657 TurnInd_RT_ON "0h";
BA_ "GenSigSendType" SG_ 657 TurnInd_RT_ON 5;
BA_ "GenSigCycleTime" SG_ 657 TurnInd_RT_ON 1000;
BA_ "FlexKomSigStartValue" SG_ 657 TurnInd_RT_ON "00h";
BA_ "FlexKomSigStartPos" SG_ 657 TurnInd_RT_ON 31;
BA_ "FlexKomSigName" SG_ 657 TurnInd_RT_ON "TurnInd_STAT";
BA_ "FlexKomSigLaenge" SG_ 657 TurnInd_RT_ON 2;
BA_ "FlexKomSID" SG_ 657 TurnInd_RT_ON 759;
BA_ "FlexKomIsMotorola" SG_ 657 TurnInd_RT_ON 1;
BA_ "FlexKomComment" SG_ 657 TurnInd_RT_ON "Turn indication status";
BA_ "GenSigTimeout_SCCM" SG_ 657 DAY_LGT_MD 10500;
BA_ "GenSigTimeout_RF_HUB" SG_ 657 DAY_LGT_MD 10500;
BA_ "GenSigTimeout_IC" SG_ 657 DAY_LGT_MD 10500;
BA_ "GenSigTimeout_ESM" SG_ 657 DAY_LGT_MD 10500;
BA_ "GenSigSNA" SG_ 657 DAY_LGT_MD "0h";
BA_ "GenSigSendType" SG_ 657 DAY_LGT_MD 5;
BA_ "GenSigCycleTime" SG_ 657 DAY_LGT_MD 1000;
BA_ "FlexKomSigStartValue" SG_ 657 DAY_LGT_MD "000000h";
BA_ "FlexKomSigStartPos" SG_ 657 DAY_LGT_MD 47;
BA_ "FlexKomSigName" SG_ 657 DAY_LGT_MD "IntLtSt_PT";
BA_ "FlexKomSigLaenge" SG_ 657 DAY_LGT_MD 24;
BA_ "FlexKomSID" SG_ 657 DAY_LGT_MD 1417;
BA_ "FlexKomIsMotorola" SG_ 657 DAY_LGT_MD 1;
BA_ "FlexKomComment" SG_ 657 DAY_LGT_MD "Interior lighting status powertrain";
BA_ "GenSigStartValue" SG_ 657 PTC_REL1_STAT 3;
BA_ "GenSigSNA" SG_ 657 PTC_REL1_STAT "3h";
BA_ "GenSigSendType" SG_ 657 PTC_REL1_STAT 5;
BA_ "GenSigCycleTime" SG_ 657 PTC_REL1_STAT 1000;
BA_ "FlexKomSigStartValue" SG_ 657 PTC_REL1_STAT "3Fh";
BA_ "FlexKomSigStartPos" SG_ 657 PTC_REL1_STAT 47;
BA_ "FlexKomSigName" SG_ 657 PTC_REL1_STAT "PTC_REL_STAT";
BA_ "FlexKomSigLaenge" SG_ 657 PTC_REL1_STAT 6;
BA_ "FlexKomSID" SG_ 657 PTC_REL1_STAT 859;
BA_ "FlexKomIsMotorola" SG_ 657 PTC_REL1_STAT 1;
BA_ "FlexKomComment" SG_ 657 PTC_REL1_STAT "PTC relays status";
BA_ "GenSigStartValue" SG_ 657 PTC_REL2_STAT 3;
BA_ "GenSigSNA" SG_ 657 PTC_REL2_STAT "3h";
BA_ "GenSigSendType" SG_ 657 PTC_REL2_STAT 5;
BA_ "GenSigCycleTime" SG_ 657 PTC_REL2_STAT 1000;
BA_ "FlexKomSigStartValue" SG_ 657 PTC_REL2_STAT "3Fh";
BA_ "FlexKomSigStartPos" SG_ 657 PTC_REL2_STAT 47;
BA_ "FlexKomSigName" SG_ 657 PTC_REL2_STAT "PTC_REL_STAT";
BA_ "FlexKomSigLaenge" SG_ 657 PTC_REL2_STAT 6;
BA_ "FlexKomSID" SG_ 657 PTC_REL2_STAT 859;
BA_ "FlexKomIsMotorola" SG_ 657 PTC_REL2_STAT 1;
BA_ "FlexKomComment" SG_ 657 PTC_REL2_STAT "PTC relays status";
BA_ "GenSigStartValue" SG_ 657 PTC_REL3_STAT 3;
BA_ "GenSigSNA" SG_ 657 PTC_REL3_STAT "3h";
BA_ "GenSigSendType" SG_ 657 PTC_REL3_STAT 5;
BA_ "GenSigCycleTime" SG_ 657 PTC_REL3_STAT 1000;
BA_ "FlexKomSigStartValue" SG_ 657 PTC_REL3_STAT "3Fh";
BA_ "FlexKomSigStartPos" SG_ 657 PTC_REL3_STAT 47;
BA_ "FlexKomSigName" SG_ 657 PTC_REL3_STAT "PTC_REL_STAT";
BA_ "FlexKomSigLaenge" SG_ 657 PTC_REL3_STAT 6;
BA_ "FlexKomSID" SG_ 657 PTC_REL3_STAT 859;
BA_ "FlexKomIsMotorola" SG_ 657 PTC_REL3_STAT 1;
BA_ "FlexKomComment" SG_ 657 PTC_REL3_STAT "PTC relays status";
BA_ "GenSigTimeout_SCCM" SG_ 657 PANEL_INTS 10500;
BA_ "GenSigTimeout_RF_HUB" SG_ 657 PANEL_INTS 10500;
BA_ "GenSigTimeout_IC" SG_ 657 PANEL_INTS 10500;
BA_ "GenSigTimeout_ESM" SG_ 657 PANEL_INTS 10500;
BA_ "GenSigSNA" SG_ 657 PANEL_INTS "FFh";
BA_ "GenSigSendType" SG_ 657 PANEL_INTS 5;
BA_ "GenSigCycleTime" SG_ 657 PANEL_INTS 1000;
BA_ "FlexKomSigStartValue" SG_ 657 PANEL_INTS "000000h";
BA_ "FlexKomSigStartPos" SG_ 657 PANEL_INTS 47;
BA_ "FlexKomSigName" SG_ 657 PANEL_INTS "IntLtSt_PT";
BA_ "FlexKomSigLaenge" SG_ 657 PANEL_INTS 24;
BA_ "FlexKomSID" SG_ 657 PANEL_INTS 1417;
BA_ "FlexKomIsMotorola" SG_ 657 PANEL_INTS 1;
BA_ "FlexKomComment" SG_ 657 PANEL_INTS "Interior lighting status powertrain";
BA_ "GenSigSNA" SG_ 657 FT_WPR_NOT_PRK "0h";
BA_ "GenSigSendType" SG_ 657 FT_WPR_NOT_PRK 5;
BA_ "GenSigCycleTime" SG_ 657 FT_WPR_NOT_PRK 1000;
BA_ "FlexKomSigStartValue" SG_ 657 FT_WPR_NOT_PRK "00h";
BA_ "FlexKomSigStartPos" SG_ 657 FT_WPR_NOT_PRK 56;
BA_ "FlexKomSigName" SG_ 657 FT_WPR_NOT_PRK "FT_WPR_NOT_PRK";
BA_ "FlexKomSigLaenge" SG_ 657 FT_WPR_NOT_PRK 1;
BA_ "FlexKomSID" SG_ 657 FT_WPR_NOT_PRK 1046;
BA_ "FlexKomIsMotorola" SG_ 657 FT_WPR_NOT_PRK 1;
BA_ "FlexKomComment" SG_ 657 FT_WPR_NOT_PRK "Front wiper outside park position";
BA_ "GenSigTimeout_IC" SG_ 657 LOBEAM_ON 10500;
BA_ "GenSigSNA" SG_ 657 LOBEAM_ON "0h";
BA_ "GenSigSendType" SG_ 657 LOBEAM_ON 5;
BA_ "GenSigCycleTime" SG_ 657 LOBEAM_ON 1000;
BA_ "FlexKomSigStartValue" SG_ 657 LOBEAM_ON "00h";
BA_ "FlexKomSigStartPos" SG_ 657 LOBEAM_ON 57;
BA_ "FlexKomSigName" SG_ 657 LOBEAM_ON "LOBEAM_ON";
BA_ "FlexKomSigLaenge" SG_ 657 LOBEAM_ON 1;
BA_ "FlexKomSID" SG_ 657 LOBEAM_ON 883;
BA_ "FlexKomIsMotorola" SG_ 657 LOBEAM_ON 1;
BA_ "FlexKomComment" SG_ 657 LOBEAM_ON "Low beam is on; off=[0], on=[1]";
BA_ "GenSigTimeout_IC" SG_ 657 HIBEAM_ON 10500;
BA_ "GenSigSNA" SG_ 657 HIBEAM_ON "0h";
BA_ "GenSigSendType" SG_ 657 HIBEAM_ON 5;
BA_ "GenSigCycleTime" SG_ 657 HIBEAM_ON 1000;
BA_ "FlexKomSigStartValue" SG_ 657 HIBEAM_ON "00h";
BA_ "FlexKomSigStartPos" SG_ 657 HIBEAM_ON 58;
BA_ "FlexKomSigName" SG_ 657 HIBEAM_ON "HIBEAM_ON";
BA_ "FlexKomSigLaenge" SG_ 657 HIBEAM_ON 1;
BA_ "FlexKomSID" SG_ 657 HIBEAM_ON 884;
BA_ "FlexKomIsMotorola" SG_ 657 HIBEAM_ON 1;
BA_ "FlexKomComment" SG_ 657 HIBEAM_ON "High beam is on; off=[0], on=[1]";
BA_ "GenSigTimeout_TBM" SG_ 657 BRK_FLUID_LO 10500;
BA_ "GenSigTimeout_IC" SG_ 657 BRK_FLUID_LO 10500;
BA_ "GenSigTimeout_ETM" SG_ 657 BRK_FLUID_LO 10500;
BA_ "GenSigSNA" SG_ 657 BRK_FLUID_LO "0h";
BA_ "GenSigSendType" SG_ 657 BRK_FLUID_LO 5;
BA_ "GenSigCycleTime" SG_ 657 BRK_FLUID_LO 1000;
BA_ "FlexKomSigStartValue" SG_ 657 BRK_FLUID_LO "00h";
BA_ "FlexKomSigStartPos" SG_ 657 BRK_FLUID_LO 62;
BA_ "FlexKomSigName" SG_ 657 BRK_FLUID_LO "BRK_FLUID_LO";
BA_ "FlexKomSigLaenge" SG_ 657 BRK_FLUID_LO 1;
BA_ "FlexKomSID" SG_ 657 BRK_FLUID_LO 885;
BA_ "FlexKomIsMotorola" SG_ 657 BRK_FLUID_LO 1;
BA_ "FlexKomComment" SG_ 657 BRK_FLUID_LO "Low brake fluid warning; low = [1]";
BA_ "GenSigTimeout_TBM" SG_ 657 WASH_FLUID_LO 10500;
BA_ "GenSigTimeout_IC" SG_ 657 WASH_FLUID_LO 10500;
BA_ "GenSigTimeout_ETM" SG_ 657 WASH_FLUID_LO 10500;
BA_ "GenSigSNA" SG_ 657 WASH_FLUID_LO "0h";
BA_ "GenSigSendType" SG_ 657 WASH_FLUID_LO 5;
BA_ "GenSigCycleTime" SG_ 657 WASH_FLUID_LO 1000;
BA_ "FlexKomSigStartValue" SG_ 657 WASH_FLUID_LO "00h";
BA_ "FlexKomSigStartPos" SG_ 657 WASH_FLUID_LO 63;
BA_ "FlexKomSigName" SG_ 657 WASH_FLUID_LO "WASH_FLUID_LO";
BA_ "FlexKomSigLaenge" SG_ 657 WASH_FLUID_LO 1;
BA_ "FlexKomSID" SG_ 657 WASH_FLUID_LO 965;
BA_ "FlexKomIsMotorola" SG_ 657 WASH_FLUID_LO 1;
BA_ "FlexKomComment" SG_ 657 WASH_FLUID_LO "Low washer fluid warning (1=Fluid is low)";
BA_ "GenSigTimeout_TBM" SG_ 662 TPM_IndLmp_On_Rq 10500;
BA_ "GenSigTimeout_ORC" SG_ 662 TPM_IndLmp_On_Rq 3500;
BA_ "GenSigTimeout_IC" SG_ 662 TPM_IndLmp_On_Rq 5500;
BA_ "GenSigTimeout_ETM" SG_ 662 TPM_IndLmp_On_Rq 10500;
BA_ "GenSigSNA" SG_ 662 TPM_IndLmp_On_Rq "3h";
BA_ "GenSigSendType" SG_ 662 TPM_IndLmp_On_Rq 5;
BA_ "GenSigCycleTime" SG_ 662 TPM_IndLmp_On_Rq 1000;
BA_ "FlexKomSigStartValue" SG_ 662 TPM_IndLmp_On_Rq "000000FFFFFFFFFFh";
BA_ "FlexKomSigStartPos" SG_ 662 TPM_IndLmp_On_Rq 7;
BA_ "FlexKomSigName" SG_ 662 TPM_IndLmp_On_Rq "TPM_A1_PKT";
BA_ "FlexKomSigLaenge" SG_ 662 TPM_IndLmp_On_Rq 64;
BA_ "FlexKomSID" SG_ 662 TPM_IndLmp_On_Rq 866;
BA_ "FlexKomIsMotorola" SG_ 662 TPM_IndLmp_On_Rq 1;
BA_ "FlexKomComment" SG_ 662 TPM_IndLmp_On_Rq "Tire Pressure Packet";
BA_ "GenSigTimeout_ORC" SG_ 662 TPM_Chime_Rq 3500;
BA_ "GenSigTimeout_IC" SG_ 662 TPM_Chime_Rq 10500;
BA_ "GenSigSNA" SG_ 662 TPM_Chime_Rq "0h";
BA_ "GenSigSendType" SG_ 662 TPM_Chime_Rq 5;
BA_ "GenSigCycleTime" SG_ 662 TPM_Chime_Rq 1000;
BA_ "FlexKomSigStartValue" SG_ 662 TPM_Chime_Rq "000000FFFFFFFFFFh";
BA_ "FlexKomSigStartPos" SG_ 662 TPM_Chime_Rq 7;
BA_ "FlexKomSigName" SG_ 662 TPM_Chime_Rq "TPM_A1_PKT";
BA_ "FlexKomSigLaenge" SG_ 662 TPM_Chime_Rq 64;
BA_ "FlexKomSID" SG_ 662 TPM_Chime_Rq 866;
BA_ "FlexKomIsMotorola" SG_ 662 TPM_Chime_Rq 1;
BA_ "FlexKomComment" SG_ 662 TPM_Chime_Rq "Tire Pressure Packet";
BA_ "GenSigTimeout_ORC" SG_ 662 TPM_Sys_Stat 3500;
BA_ "GenSigTimeout_IC" SG_ 662 TPM_Sys_Stat 10500;
BA_ "GenSigSNA" SG_ 662 TPM_Sys_Stat "7h";
BA_ "GenSigSendType" SG_ 662 TPM_Sys_Stat 5;
BA_ "GenSigCycleTime" SG_ 662 TPM_Sys_Stat 1000;
BA_ "FlexKomSigStartValue" SG_ 662 TPM_Sys_Stat "000000FFFFFFFFFFh";
BA_ "FlexKomSigStartPos" SG_ 662 TPM_Sys_Stat 7;
BA_ "FlexKomSigName" SG_ 662 TPM_Sys_Stat "TPM_A1_PKT";
BA_ "FlexKomSigLaenge" SG_ 662 TPM_Sys_Stat 64;
BA_ "FlexKomSID" SG_ 662 TPM_Sys_Stat 866;
BA_ "FlexKomIsMotorola" SG_ 662 TPM_Sys_Stat 1;
BA_ "FlexKomComment" SG_ 662 TPM_Sys_Stat "Tire Pressure Packet";
BA_ "GenSigTimeout_ORC" SG_ 662 TireFL 3500;
BA_ "GenSigTimeout_IC" SG_ 662 TireFL 10500;
BA_ "GenSigTimeout_ETM" SG_ 662 TireFL 10500;
BA_ "GenSigSNA" SG_ 662 TireFL "3h";
BA_ "GenSigSendType" SG_ 662 TireFL 5;
BA_ "GenSigCycleTime" SG_ 662 TireFL 1000;
BA_ "FlexKomSigStartValue" SG_ 662 TireFL "000000FFFFFFFFFFh";
BA_ "FlexKomSigStartPos" SG_ 662 TireFL 7;
BA_ "FlexKomSigName" SG_ 662 TireFL "TPM_A1_PKT";
BA_ "FlexKomSigLaenge" SG_ 662 TireFL 64;
BA_ "FlexKomSID" SG_ 662 TireFL 866;
BA_ "FlexKomIsMotorola" SG_ 662 TireFL 1;
BA_ "FlexKomComment" SG_ 662 TireFL "Tire Pressure Packet";
BA_ "GenSigTimeout_ORC" SG_ 662 TireFR 3500;
BA_ "GenSigTimeout_IC" SG_ 662 TireFR 10500;
BA_ "GenSigTimeout_ETM" SG_ 662 TireFR 10500;
BA_ "GenSigSNA" SG_ 662 TireFR "3h";
BA_ "GenSigSendType" SG_ 662 TireFR 5;
BA_ "GenSigCycleTime" SG_ 662 TireFR 1000;
BA_ "FlexKomSigStartValue" SG_ 662 TireFR "000000FFFFFFFFFFh";
BA_ "FlexKomSigStartPos" SG_ 662 TireFR 7;
BA_ "FlexKomSigName" SG_ 662 TireFR "TPM_A1_PKT";
BA_ "FlexKomSigLaenge" SG_ 662 TireFR 64;
BA_ "FlexKomSID" SG_ 662 TireFR 866;
BA_ "FlexKomIsMotorola" SG_ 662 TireFR 1;
BA_ "FlexKomComment" SG_ 662 TireFR "Tire Pressure Packet";
BA_ "GenSigTimeout_ORC" SG_ 662 TireRR 3500;
BA_ "GenSigTimeout_IC" SG_ 662 TireRR 10500;
BA_ "GenSigTimeout_ETM" SG_ 662 TireRR 10500;
BA_ "GenSigSNA" SG_ 662 TireRR "3h";
BA_ "GenSigSendType" SG_ 662 TireRR 5;
BA_ "GenSigCycleTime" SG_ 662 TireRR 1000;
BA_ "FlexKomSigStartValue" SG_ 662 TireRR "000000FFFFFFFFFFh";
BA_ "FlexKomSigStartPos" SG_ 662 TireRR 7;
BA_ "FlexKomSigName" SG_ 662 TireRR "TPM_A1_PKT";
BA_ "FlexKomSigLaenge" SG_ 662 TireRR 64;
BA_ "FlexKomSID" SG_ 662 TireRR 866;
BA_ "FlexKomIsMotorola" SG_ 662 TireRR 1;
BA_ "FlexKomComment" SG_ 662 TireRR "Tire Pressure Packet";
BA_ "GenSigTimeout_ORC" SG_ 662 TireRL 3500;
BA_ "GenSigTimeout_IC" SG_ 662 TireRL 10500;
BA_ "GenSigTimeout_ETM" SG_ 662 TireRL 10500;
BA_ "GenSigSNA" SG_ 662 TireRL "3h";
BA_ "GenSigSendType" SG_ 662 TireRL 5;
BA_ "GenSigCycleTime" SG_ 662 TireRL 1000;
BA_ "FlexKomSigStartValue" SG_ 662 TireRL "000000FFFFFFFFFFh";
BA_ "FlexKomSigStartPos" SG_ 662 TireRL 7;
BA_ "FlexKomSigName" SG_ 662 TireRL "TPM_A1_PKT";
BA_ "FlexKomSigLaenge" SG_ 662 TireRL 64;
BA_ "FlexKomSID" SG_ 662 TireRL 866;
BA_ "FlexKomIsMotorola" SG_ 662 TireRL 1;
BA_ "FlexKomComment" SG_ 662 TireRL "Tire Pressure Packet";
BA_ "GenSigTimeout_TBM" SG_ 662 TirePressFL 10500;
BA_ "GenSigTimeout_ORC" SG_ 662 TirePressFL 3500;
BA_ "GenSigTimeout_IC" SG_ 662 TirePressFL 10500;
BA_ "GenSigStartValue" SG_ 662 TirePressFL 255;
BA_ "GenSigSNA" SG_ 662 TirePressFL "FFh";
BA_ "GenSigSendType" SG_ 662 TirePressFL 5;
BA_ "GenSigCycleTime" SG_ 662 TirePressFL 1000;
BA_ "FlexKomSigStartValue" SG_ 662 TirePressFL "000000FFFFFFFFFFh";
BA_ "FlexKomSigStartPos" SG_ 662 TirePressFL 7;
BA_ "FlexKomSigName" SG_ 662 TirePressFL "TPM_A1_PKT";
BA_ "FlexKomSigLaenge" SG_ 662 TirePressFL 64;
BA_ "FlexKomSID" SG_ 662 TirePressFL 866;
BA_ "FlexKomIsMotorola" SG_ 662 TirePressFL 1;
BA_ "FlexKomComment" SG_ 662 TirePressFL "Tire Pressure Packet";
BA_ "GenSigTimeout_TBM" SG_ 662 TirePressFR 10500;
BA_ "GenSigTimeout_ORC" SG_ 662 TirePressFR 3500;
BA_ "GenSigTimeout_IC" SG_ 662 TirePressFR 10500;
BA_ "GenSigStartValue" SG_ 662 TirePressFR 255;
BA_ "GenSigSNA" SG_ 662 TirePressFR "FFh";
BA_ "GenSigSendType" SG_ 662 TirePressFR 5;
BA_ "GenSigCycleTime" SG_ 662 TirePressFR 1000;
BA_ "FlexKomSigStartValue" SG_ 662 TirePressFR "000000FFFFFFFFFFh";
BA_ "FlexKomSigStartPos" SG_ 662 TirePressFR 7;
BA_ "FlexKomSigName" SG_ 662 TirePressFR "TPM_A1_PKT";
BA_ "FlexKomSigLaenge" SG_ 662 TirePressFR 64;
BA_ "FlexKomSID" SG_ 662 TirePressFR 866;
BA_ "FlexKomIsMotorola" SG_ 662 TirePressFR 1;
BA_ "FlexKomComment" SG_ 662 TirePressFR "Tire Pressure Packet";
BA_ "GenSigTimeout_TBM" SG_ 662 TirePressRL 10500;
BA_ "GenSigTimeout_ORC" SG_ 662 TirePressRL 3500;
BA_ "GenSigTimeout_IC" SG_ 662 TirePressRL 10500;
BA_ "GenSigStartValue" SG_ 662 TirePressRL 255;
BA_ "GenSigSNA" SG_ 662 TirePressRL "FFh";
BA_ "GenSigSendType" SG_ 662 TirePressRL 5;
BA_ "GenSigCycleTime" SG_ 662 TirePressRL 1000;
BA_ "FlexKomSigStartValue" SG_ 662 TirePressRL "000000FFFFFFFFFFh";
BA_ "FlexKomSigStartPos" SG_ 662 TirePressRL 7;
BA_ "FlexKomSigName" SG_ 662 TirePressRL "TPM_A1_PKT";
BA_ "FlexKomSigLaenge" SG_ 662 TirePressRL 64;
BA_ "FlexKomSID" SG_ 662 TirePressRL 866;
BA_ "FlexKomIsMotorola" SG_ 662 TirePressRL 1;
BA_ "FlexKomComment" SG_ 662 TirePressRL "Tire Pressure Packet";
BA_ "GenSigTimeout_TBM" SG_ 662 TirePressRR 10500;
BA_ "GenSigTimeout_ORC" SG_ 662 TirePressRR 3500;
BA_ "GenSigTimeout_IC" SG_ 662 TirePressRR 10500;
BA_ "GenSigStartValue" SG_ 662 TirePressRR 255;
BA_ "GenSigSNA" SG_ 662 TirePressRR "FFh";
BA_ "GenSigSendType" SG_ 662 TirePressRR 5;
BA_ "GenSigCycleTime" SG_ 662 TirePressRR 1000;
BA_ "FlexKomSigStartValue" SG_ 662 TirePressRR "000000FFFFFFFFFFh";
BA_ "FlexKomSigStartPos" SG_ 662 TirePressRR 7;
BA_ "FlexKomSigName" SG_ 662 TirePressRR "TPM_A1_PKT";
BA_ "FlexKomSigLaenge" SG_ 662 TirePressRR 64;
BA_ "FlexKomSID" SG_ 662 TirePressRR 866;
BA_ "FlexKomIsMotorola" SG_ 662 TirePressRR 1;
BA_ "FlexKomComment" SG_ 662 TirePressRR "Tire Pressure Packet";
BA_ "GenSigTimeout_TBM" SG_ 662 TPM_HornChirp 10500;
BA_ "GenSigTimeout_ORC" SG_ 662 TPM_HornChirp 3500;
BA_ "GenSigTimeout_IC" SG_ 662 TPM_HornChirp 5500;
BA_ "GenSigTimeout_ETM" SG_ 662 TPM_HornChirp 10500;
BA_ "GenSigTimeout_CBC" SG_ 662 TPM_HornChirp 10500;
BA_ "GenSigSNA" SG_ 662 TPM_HornChirp "3h";
BA_ "GenSigSendType" SG_ 662 TPM_HornChirp 5;
BA_ "GenSigCycleTime" SG_ 662 TPM_HornChirp 1000;
BA_ "FlexKomSigStartValue" SG_ 662 TPM_HornChirp "000000FFFFFFFFFFh";
BA_ "FlexKomSigStartPos" SG_ 662 TPM_HornChirp 7;
BA_ "FlexKomSigName" SG_ 662 TPM_HornChirp "TPM_A1_PKT";
BA_ "FlexKomSigLaenge" SG_ 662 TPM_HornChirp 64;
BA_ "FlexKomSID" SG_ 662 TPM_HornChirp 866;
BA_ "FlexKomIsMotorola" SG_ 662 TPM_HornChirp 1;
BA_ "FlexKomComment" SG_ 662 TPM_HornChirp "Tire Pressure Packet";
BA_ "GenSigTimeout_TBM" SG_ 662 TPM_HazardFlash 10500;
BA_ "GenSigTimeout_ORC" SG_ 662 TPM_HazardFlash 3500;
BA_ "GenSigTimeout_IC" SG_ 662 TPM_HazardFlash 5500;
BA_ "GenSigTimeout_ETM" SG_ 662 TPM_HazardFlash 10500;
BA_ "GenSigTimeout_CBC" SG_ 662 TPM_HazardFlash 10500;
BA_ "GenSigSNA" SG_ 662 TPM_HazardFlash "0h";
BA_ "GenSigSendType" SG_ 662 TPM_HazardFlash 5;
BA_ "GenSigCycleTime" SG_ 662 TPM_HazardFlash 1000;
BA_ "FlexKomSigStartValue" SG_ 662 TPM_HazardFlash "000000FFFFFFFFFFh";
BA_ "FlexKomSigStartPos" SG_ 662 TPM_HazardFlash 7;
BA_ "FlexKomSigName" SG_ 662 TPM_HazardFlash "TPM_A1_PKT";
BA_ "FlexKomSigLaenge" SG_ 662 TPM_HazardFlash 64;
BA_ "FlexKomSID" SG_ 662 TPM_HazardFlash 866;
BA_ "FlexKomIsMotorola" SG_ 662 TPM_HazardFlash 1;
BA_ "FlexKomComment" SG_ 662 TPM_HazardFlash "Tire Pressure Packet";
BA_ "RID" SG_ 662 TFASts_TPM "6478";
BA_ "GenSigTimeout_CBC" SG_ 662 TFASts_TPM 10500;
BA_ "GenSigSNA" SG_ 662 TFASts_TPM "0h";
BA_ "GenSigSendType" SG_ 662 TFASts_TPM 5;
BA_ "GenSigCycleTime" SG_ 662 TFASts_TPM 1000;
BA_ "FlexKomSigStartValue" SG_ 662 TFASts_TPM "000000FFFFFFFFFFh";
BA_ "FlexKomSigStartPos" SG_ 662 TFASts_TPM 7;
BA_ "FlexKomSigName" SG_ 662 TFASts_TPM "TPM_A1_PKT";
BA_ "FlexKomSigLaenge" SG_ 662 TFASts_TPM 64;
BA_ "FlexKomSID" SG_ 662 TFASts_TPM 866;
BA_ "FlexKomIsMotorola" SG_ 662 TFASts_TPM 1;
BA_ "FlexKomComment" SG_ 662 TFASts_TPM "Tire Pressure Packet";
BA_ "RID" SG_ 662 STFASysEnableFault "6541";
BA_ "GenSigSNA" SG_ 662 STFASysEnableFault "0h";
BA_ "GenSigSendType" SG_ 662 STFASysEnableFault 5;
BA_ "GenSigCycleTime" SG_ 662 STFASysEnableFault 1000;
BA_ "FlexKomSigStartValue" SG_ 662 STFASysEnableFault "000000FFFFFFFFFFh";
BA_ "FlexKomSigStartPos" SG_ 662 STFASysEnableFault 7;
BA_ "FlexKomSigName" SG_ 662 STFASysEnableFault "TPM_A1_PKT";
BA_ "FlexKomSigLaenge" SG_ 662 STFASysEnableFault 64;
BA_ "FlexKomSID" SG_ 662 STFASysEnableFault 866;
BA_ "FlexKomIsMotorola" SG_ 662 STFASysEnableFault 1;
BA_ "FlexKomComment" SG_ 662 STFASysEnableFault "Tire Pressure Packet";
BA_ "RID" SG_ 663 SpSt_Pad1 "1933";
BA_ "GenSigSNA" SG_ 663 SpSt_Pad1 "7h";
BA_ "GenSigSendType" SG_ 663 SpSt_Pad1 5;
BA_ "GenSigCycleTime" SG_ 663 SpSt_Pad1 1000;
BA_ "FlexKomSigStartValue" SG_ 663 SpSt_Pad1 "00h";
BA_ "FlexKomSigStartPos" SG_ 663 SpSt_Pad1 52;
BA_ "FlexKomSigName" SG_ 663 SpSt_Pad1 "SpSt_Pad1";
BA_ "FlexKomSigLaenge" SG_ 663 SpSt_Pad1 3;
BA_ "FlexKomSID" SG_ 663 SpSt_Pad1 1959;
BA_ "FlexKomIsMotorola" SG_ 663 SpSt_Pad1 1;
BA_ "FlexKomComment" SG_ 663 SpSt_Pad1 "Stop / start switch - pad 1";
BA_ "RID" SG_ 663 SpSt_Pad2 "1934";
BA_ "GenSigSNA" SG_ 663 SpSt_Pad2 "7h";
BA_ "GenSigSendType" SG_ 663 SpSt_Pad2 5;
BA_ "GenSigCycleTime" SG_ 663 SpSt_Pad2 1000;
BA_ "FlexKomSigStartValue" SG_ 663 SpSt_Pad2 "00h";
BA_ "FlexKomSigStartPos" SG_ 663 SpSt_Pad2 55;
BA_ "FlexKomSigName" SG_ 663 SpSt_Pad2 "SpSt_Pad2";
BA_ "FlexKomSigLaenge" SG_ 663 SpSt_Pad2 3;
BA_ "FlexKomSID" SG_ 663 SpSt_Pad2 1960;
BA_ "FlexKomIsMotorola" SG_ 663 SpSt_Pad2 1;
BA_ "FlexKomComment" SG_ 663 SpSt_Pad2 "Stop / start switch - pad 2";
BA_ "RID" SG_ 673 TorqueUnit "1994";
BA_ "GenSigSNA" SG_ 673 TorqueUnit "0h";
BA_ "GenSigSendType" SG_ 673 TorqueUnit 5;
BA_ "GenSigCycleTime" SG_ 673 TorqueUnit 1000;
BA_ "FlexKomSigStartValue" SG_ 673 TorqueUnit "00h";
BA_ "FlexKomSigStartPos" SG_ 673 TorqueUnit 7;
BA_ "FlexKomSigName" SG_ 673 TorqueUnit "TorqueUnit";
BA_ "FlexKomSigLaenge" SG_ 673 TorqueUnit 1;
BA_ "FlexKomSID" SG_ 673 TorqueUnit 1998;
BA_ "FlexKomIsMotorola" SG_ 673 TorqueUnit 1;
BA_ "FlexKomComment" SG_ 673 TorqueUnit "Torque units; Foot Pounds (ft-lb) = [1]";
BA_ "RID" SG_ 673 LANG_C "1797";
BA_ "GenSigTimeout_CBC" SG_ 673 LANG_C 10500;
BA_ "GenSigStartValue" SG_ 673 LANG_C 31;
BA_ "GenSigSNA" SG_ 673 LANG_C "1Fh";
BA_ "GenSigSendType" SG_ 673 LANG_C 5;
BA_ "GenSigCycleTime" SG_ 673 LANG_C 1000;
BA_ "FlexKomSigStartValue" SG_ 673 LANG_C "3Eh";
BA_ "FlexKomSigStartPos" SG_ 673 LANG_C 15;
BA_ "FlexKomSigName" SG_ 673 LANG_C "CFG_STAT_C";
BA_ "FlexKomSigLaenge" SG_ 673 LANG_C 6;
BA_ "FlexKomSID" SG_ 673 LANG_C 1804;
BA_ "FlexKomIsMotorola" SG_ 673 LANG_C 1;
BA_ "FlexKomComment" SG_ 673 LANG_C "Configuration status";
BA_ "RID" SG_ 673 RDY_DRV_STAT_CSO "5028";
BA_ "GenSigSNA" SG_ 673 RDY_DRV_STAT_CSO "0h";
BA_ "GenSigSendType" SG_ 673 RDY_DRV_STAT_CSO 5;
BA_ "GenSigCycleTime" SG_ 673 RDY_DRV_STAT_CSO 1000;
BA_ "FlexKomSigStartValue" SG_ 673 RDY_DRV_STAT_CSO "00h";
BA_ "FlexKomSigStartPos" SG_ 673 RDY_DRV_STAT_CSO 17;
BA_ "FlexKomSigName" SG_ 673 RDY_DRV_STAT_CSO "RDY_DRV_STAT_CSO";
BA_ "FlexKomSigLaenge" SG_ 673 RDY_DRV_STAT_CSO 1;
BA_ "FlexKomSID" SG_ 673 RDY_DRV_STAT_CSO 2592;
BA_ "FlexKomIsMotorola" SG_ 673 RDY_DRV_STAT_CSO 1;
BA_ "FlexKomComment" SG_ 673 RDY_DRV_STAT_CSO "Ready to drive popup status enable/disable; Disabl";
BA_ "RID" SG_ 673 UNIT_SET_CSO "5045";
BA_ "GenSigTimeout_CBC" SG_ 673 UNIT_SET_CSO 10500;
BA_ "GenSigSNA" SG_ 673 UNIT_SET_CSO "0h";
BA_ "GenSigSendType" SG_ 673 UNIT_SET_CSO 5;
BA_ "GenSigCycleTime" SG_ 673 UNIT_SET_CSO 1000;
BA_ "FlexKomSigStartValue" SG_ 673 UNIT_SET_CSO "00h";
BA_ "FlexKomSigStartPos" SG_ 673 UNIT_SET_CSO 25;
BA_ "FlexKomSigName" SG_ 673 UNIT_SET_CSO "UNIT_SET_CSO";
BA_ "FlexKomSigLaenge" SG_ 673 UNIT_SET_CSO 2;
BA_ "FlexKomSID" SG_ 673 UNIT_SET_CSO 2602;
BA_ "FlexKomIsMotorola" SG_ 673 UNIT_SET_CSO 1;
BA_ "FlexKomComment" SG_ 673 UNIT_SET_CSO "Unit set status enable/disable";
BA_ "RID" SG_ 673 PowerUnit "2007";
BA_ "GenSigTimeout_CBC" SG_ 673 PowerUnit 10500;
BA_ "GenSigSNA" SG_ 673 PowerUnit "0h";
BA_ "GenSigSendType" SG_ 673 PowerUnit 5;
BA_ "GenSigCycleTime" SG_ 673 PowerUnit 1000;
BA_ "FlexKomSigStartValue" SG_ 673 PowerUnit "00h";
BA_ "FlexKomSigStartPos" SG_ 673 PowerUnit 35;
BA_ "FlexKomSigName" SG_ 673 PowerUnit "PowerUnit";
BA_ "FlexKomSigLaenge" SG_ 673 PowerUnit 2;
BA_ "FlexKomSID" SG_ 673 PowerUnit 1999;
BA_ "FlexKomIsMotorola" SG_ 673 PowerUnit 1;
BA_ "FlexKomComment" SG_ 673 PowerUnit "Power units";
BA_ "RID" SG_ 673 PressureUnit "1998";
BA_ "GenSigTimeout_CBC" SG_ 673 PressureUnit 10500;
BA_ "GenSigSNA" SG_ 673 PressureUnit "0h";
BA_ "GenSigSendType" SG_ 673 PressureUnit 5;
BA_ "GenSigCycleTime" SG_ 673 PressureUnit 1000;
BA_ "FlexKomSigStartValue" SG_ 673 PressureUnit "00h";
BA_ "FlexKomSigStartPos" SG_ 673 PressureUnit 37;
BA_ "FlexKomSigName" SG_ 673 PressureUnit "PressureUnit";
BA_ "FlexKomSigLaenge" SG_ 673 PressureUnit 2;
BA_ "FlexKomSID" SG_ 673 PressureUnit 2000;
BA_ "FlexKomIsMotorola" SG_ 673 PressureUnit 1;
BA_ "FlexKomComment" SG_ 673 PressureUnit "Pressure units";
BA_ "RID" SG_ 673 DistanceUnit "1992";
BA_ "GenSigSNA" SG_ 673 DistanceUnit "0h";
BA_ "GenSigSendType" SG_ 673 DistanceUnit 5;
BA_ "GenSigCycleTime" SG_ 673 DistanceUnit 1000;
BA_ "FlexKomSigStartValue" SG_ 673 DistanceUnit "00h";
BA_ "FlexKomSigStartPos" SG_ 673 DistanceUnit 50;
BA_ "FlexKomSigName" SG_ 673 DistanceUnit "DistanceUnit";
BA_ "FlexKomSigLaenge" SG_ 673 DistanceUnit 1;
BA_ "FlexKomSID" SG_ 673 DistanceUnit 2002;
BA_ "FlexKomIsMotorola" SG_ 673 DistanceUnit 1;
BA_ "FlexKomComment" SG_ 673 DistanceUnit "Distance (odometer) units; Miles = [1]";
BA_ "RID" SG_ 673 SpeedUnit "2000";
BA_ "GenSigSNA" SG_ 673 SpeedUnit "0h";
BA_ "GenSigSendType" SG_ 673 SpeedUnit 5;
BA_ "GenSigCycleTime" SG_ 673 SpeedUnit 1000;
BA_ "FlexKomSigStartValue" SG_ 673 SpeedUnit "00h";
BA_ "FlexKomSigStartPos" SG_ 673 SpeedUnit 51;
BA_ "FlexKomSigName" SG_ 673 SpeedUnit "SpeedUnit";
BA_ "FlexKomSigLaenge" SG_ 673 SpeedUnit 1;
BA_ "FlexKomSID" SG_ 673 SpeedUnit 2004;
BA_ "FlexKomIsMotorola" SG_ 673 SpeedUnit 1;
BA_ "FlexKomComment" SG_ 673 SpeedUnit "Speed (speedometer) units; Miles = [1]";
BA_ "RID" SG_ 673 TemperatureUnit "2004";
BA_ "GenSigSNA" SG_ 673 TemperatureUnit "0h";
BA_ "GenSigSendType" SG_ 673 TemperatureUnit 5;
BA_ "GenSigCycleTime" SG_ 673 TemperatureUnit 1000;
BA_ "FlexKomSigStartValue" SG_ 673 TemperatureUnit "00h";
BA_ "FlexKomSigStartPos" SG_ 673 TemperatureUnit 52;
BA_ "FlexKomSigName" SG_ 673 TemperatureUnit "TemperatureUnit";
BA_ "FlexKomSigLaenge" SG_ 673 TemperatureUnit 1;
BA_ "FlexKomSID" SG_ 673 TemperatureUnit 2003;
BA_ "FlexKomIsMotorola" SG_ 673 TemperatureUnit 1;
BA_ "FlexKomComment" SG_ 673 TemperatureUnit "Temperature units; Farenheit = [1]";
BA_ "RID" SG_ 673 ConsumptionUnit "2002";
BA_ "GenSigTimeout_CBC" SG_ 673 ConsumptionUnit 10500;
BA_ "GenSigSNA" SG_ 673 ConsumptionUnit "7h";
BA_ "GenSigSendType" SG_ 673 ConsumptionUnit 5;
BA_ "GenSigCycleTime" SG_ 673 ConsumptionUnit 1000;
BA_ "FlexKomSigStartValue" SG_ 673 ConsumptionUnit "00h";
BA_ "FlexKomSigStartPos" SG_ 673 ConsumptionUnit 55;
BA_ "FlexKomSigName" SG_ 673 ConsumptionUnit "ConsumptionUnit";
BA_ "FlexKomSigLaenge" SG_ 673 ConsumptionUnit 3;
BA_ "FlexKomSID" SG_ 673 ConsumptionUnit 2005;
BA_ "FlexKomIsMotorola" SG_ 673 ConsumptionUnit 1;
BA_ "FlexKomComment" SG_ 673 ConsumptionUnit "Fuel consumption units";
BA_ "GenSigStartValue" SG_ 676 MAP_4_Bar 511;
BA_ "GenSigSNA" SG_ 676 MAP_4_Bar "1FFh";
BA_ "GenSigCycleTime" SG_ 676 MAP_4_Bar 100;
BA_ "FlexKomSigStartValue" SG_ 676 MAP_4_Bar "01FFh";
BA_ "FlexKomSigStartPos" SG_ 676 MAP_4_Bar 7;
BA_ "FlexKomSigName" SG_ 676 MAP_4_Bar "MAP_4_Bar";
BA_ "FlexKomSigLaenge" SG_ 676 MAP_4_Bar 16;
BA_ "FlexKomSID" SG_ 676 MAP_4_Bar 2688;
BA_ "FlexKomIsMotorola" SG_ 676 MAP_4_Bar 1;
BA_ "FlexKomComment" SG_ 676 MAP_4_Bar "Engine manifold pressure (4 bar range)";
BA_ "GenSigTimeout_IC" SG_ 676 ECM_WARN_EXT 1050;
BA_ "GenSigSNA" SG_ 676 ECM_WARN_EXT "1Fh";
BA_ "GenSigCycleTime" SG_ 676 ECM_WARN_EXT 100;
BA_ "FlexKomSigStartValue" SG_ 676 ECM_WARN_EXT "00h";
BA_ "FlexKomSigStartPos" SG_ 676 ECM_WARN_EXT 28;
BA_ "FlexKomSigName" SG_ 676 ECM_WARN_EXT "ECM_WARN_EXT";
BA_ "FlexKomSigLaenge" SG_ 676 ECM_WARN_EXT 5;
BA_ "FlexKomSID" SG_ 676 ECM_WARN_EXT 2727;
BA_ "FlexKomIsMotorola" SG_ 676 ECM_WARN_EXT 1;
BA_ "FlexKomComment" SG_ 676 ECM_WARN_EXT "HMI extended warnings";
BA_ "GenSigSNA" SG_ 676 TransWarmup_Enbl_Rq "0h";
BA_ "GenSigCycleTime" SG_ 676 TransWarmup_Enbl_Rq 100;
BA_ "FlexKomSigStartValue" SG_ 676 TransWarmup_Enbl_Rq "00h";
BA_ "FlexKomSigStartPos" SG_ 676 TransWarmup_Enbl_Rq 20;
BA_ "FlexKomSigName" SG_ 676 TransWarmup_Enbl_Rq "TransWarmup_Enbl_Rq";
BA_ "FlexKomSigLaenge" SG_ 676 TransWarmup_Enbl_Rq 1;
BA_ "FlexKomSID" SG_ 676 TransWarmup_Enbl_Rq 2790;
BA_ "FlexKomIsMotorola" SG_ 676 TransWarmup_Enbl_Rq 1;
BA_ "FlexKomComment" SG_ 676 TransWarmup_Enbl_Rq "Enable and disable flag for transmission warm up f";
BA_ "GenSigSNA" SG_ 676 MC_ECM_B11 "0h";
BA_ "GenSigCycleTime" SG_ 676 MC_ECM_B11 100;
BA_ "FlexKomSigStartValue" SG_ 676 MC_ECM_B11 "00h";
BA_ "FlexKomSigStartPos" SG_ 676 MC_ECM_B11 55;
BA_ "FlexKomSigName" SG_ 676 MC_ECM_B11 "MC_ECM_B11";
BA_ "FlexKomSigLaenge" SG_ 676 MC_ECM_B11 4;
BA_ "FlexKomSID" SG_ 676 MC_ECM_B11 2792;
BA_ "FlexKomIsMotorola" SG_ 676 MC_ECM_B11 1;
BA_ "FlexKomComment" SG_ 676 MC_ECM_B11 "Message Counter";
BA_ "GenSigSNA" SG_ 676 TransWarmup_Min_RPM "FFh";
BA_ "GenSigCycleTime" SG_ 676 TransWarmup_Min_RPM 100;
BA_ "FlexKomSigStartValue" SG_ 676 TransWarmup_Min_RPM "00h";
BA_ "FlexKomSigStartPos" SG_ 676 TransWarmup_Min_RPM 39;
BA_ "FlexKomSigName" SG_ 676 TransWarmup_Min_RPM "TransWarmup_Min_RPM";
BA_ "FlexKomSigLaenge" SG_ 676 TransWarmup_Min_RPM 8;
BA_ "FlexKomSID" SG_ 676 TransWarmup_Min_RPM 2791;
BA_ "FlexKomIsMotorola" SG_ 676 TransWarmup_Min_RPM 1;
BA_ "FlexKomComment" SG_ 676 TransWarmup_Min_RPM "Enable and disable flag for transmission warm up f";
BA_ "GenSigStartValue" SG_ 676 CRC_ECM_B11 255;
BA_ "GenSigSNA" SG_ 676 CRC_ECM_B11 "FFh";
BA_ "GenSigCycleTime" SG_ 676 CRC_ECM_B11 100;
BA_ "FlexKomSigStartValue" SG_ 676 CRC_ECM_B11 "FFh";
BA_ "FlexKomSigStartPos" SG_ 676 CRC_ECM_B11 63;
BA_ "FlexKomSigName" SG_ 676 CRC_ECM_B11 "CRC_ECM_B11";
BA_ "FlexKomSigLaenge" SG_ 676 CRC_ECM_B11 8;
BA_ "FlexKomSID" SG_ 676 CRC_ECM_B11 2793;
BA_ "FlexKomIsMotorola" SG_ 676 CRC_ECM_B11 1;
BA_ "FlexKomComment" SG_ 676 CRC_ECM_B11 "CRC-Checksum Byte 1 - 7 according to SAE J1850";
BA_ "GenSigTimeout_IC" SG_ 679 MsgFobBattLow 10500;
BA_ "GenSigSNA" SG_ 679 MsgFobBattLow "3h";
BA_ "GenSigSendType" SG_ 679 MsgFobBattLow 5;
BA_ "GenSigCycleTime" SG_ 679 MsgFobBattLow 1000;
BA_ "FlexKomSigStartValue" SG_ 679 MsgFobBattLow "0000000000000000h";
BA_ "FlexKomSigStartPos" SG_ 679 MsgFobBattLow 7;
BA_ "FlexKomSigName" SG_ 679 MsgFobBattLow "RFMsgPkt";
BA_ "FlexKomSigLaenge" SG_ 679 MsgFobBattLow 64;
BA_ "FlexKomSID" SG_ 679 MsgFobBattLow 1038;
BA_ "FlexKomIsMotorola" SG_ 679 MsgFobBattLow 1;
BA_ "FlexKomComment" SG_ 679 MsgFobBattLow "RF message packet";
BA_ "GenSigTimeout_IC" SG_ 679 MsgFobNotFnd 10500;
BA_ "GenSigSNA" SG_ 679 MsgFobNotFnd "3h";
BA_ "GenSigSendType" SG_ 679 MsgFobNotFnd 5;
BA_ "GenSigCycleTime" SG_ 679 MsgFobNotFnd 1000;
BA_ "FlexKomSigStartValue" SG_ 679 MsgFobNotFnd "0000000000000000h";
BA_ "FlexKomSigStartPos" SG_ 679 MsgFobNotFnd 7;
BA_ "FlexKomSigName" SG_ 679 MsgFobNotFnd "RFMsgPkt";
BA_ "FlexKomSigLaenge" SG_ 679 MsgFobNotFnd 64;
BA_ "FlexKomSID" SG_ 679 MsgFobNotFnd 1038;
BA_ "FlexKomIsMotorola" SG_ 679 MsgFobNotFnd 1;
BA_ "FlexKomComment" SG_ 679 MsgFobNotFnd "RF message packet";
BA_ "GenSigTimeout_IC" SG_ 679 MsgNotInPark 10500;
BA_ "GenSigSNA" SG_ 679 MsgNotInPark "3h";
BA_ "GenSigSendType" SG_ 679 MsgNotInPark 5;
BA_ "GenSigCycleTime" SG_ 679 MsgNotInPark 1000;
BA_ "FlexKomSigStartValue" SG_ 679 MsgNotInPark "0000000000000000h";
BA_ "FlexKomSigStartPos" SG_ 679 MsgNotInPark 7;
BA_ "FlexKomSigName" SG_ 679 MsgNotInPark "RFMsgPkt";
BA_ "FlexKomSigLaenge" SG_ 679 MsgNotInPark 64;
BA_ "FlexKomSID" SG_ 679 MsgNotInPark 1038;
BA_ "FlexKomIsMotorola" SG_ 679 MsgNotInPark 1;
BA_ "FlexKomComment" SG_ 679 MsgNotInPark "RF message packet";
BA_ "GenSigTimeout_IC" SG_ 679 MsgKG1 10500;
BA_ "GenSigSNA" SG_ 679 MsgKG1 "3h";
BA_ "GenSigSendType" SG_ 679 MsgKG1 5;
BA_ "GenSigCycleTime" SG_ 679 MsgKG1 1000;
BA_ "FlexKomSigStartValue" SG_ 679 MsgKG1 "0000000000000000h";
BA_ "FlexKomSigStartPos" SG_ 679 MsgKG1 7;
BA_ "FlexKomSigName" SG_ 679 MsgKG1 "RFMsgPkt";
BA_ "FlexKomSigLaenge" SG_ 679 MsgKG1 64;
BA_ "FlexKomSID" SG_ 679 MsgKG1 1038;
BA_ "FlexKomIsMotorola" SG_ 679 MsgKG1 1;
BA_ "FlexKomComment" SG_ 679 MsgKG1 "RF message packet";
BA_ "GenSigTimeout_IC" SG_ 679 MsgKG2 10500;
BA_ "GenSigSNA" SG_ 679 MsgKG2 "3h";
BA_ "GenSigSendType" SG_ 679 MsgKG2 5;
BA_ "GenSigCycleTime" SG_ 679 MsgKG2 1000;
BA_ "FlexKomSigStartValue" SG_ 679 MsgKG2 "0000000000000000h";
BA_ "FlexKomSigStartPos" SG_ 679 MsgKG2 7;
BA_ "FlexKomSigName" SG_ 679 MsgKG2 "RFMsgPkt";
BA_ "FlexKomSigLaenge" SG_ 679 MsgKG2 64;
BA_ "FlexKomSID" SG_ 679 MsgKG2 1038;
BA_ "FlexKomIsMotorola" SG_ 679 MsgKG2 1;
BA_ "FlexKomComment" SG_ 679 MsgKG2 "RF message packet";
BA_ "GenSigTimeout_CBC" SG_ 679 FOB_SrchRslt 10500;
BA_ "GenSigSNA" SG_ 679 FOB_SrchRslt "0h";
BA_ "GenSigSendType" SG_ 679 FOB_SrchRslt 5;
BA_ "GenSigCycleTime" SG_ 679 FOB_SrchRslt 1000;
BA_ "FlexKomSigStartValue" SG_ 679 FOB_SrchRslt "0000000000000000h";
BA_ "FlexKomSigStartPos" SG_ 679 FOB_SrchRslt 7;
BA_ "FlexKomSigName" SG_ 679 FOB_SrchRslt "RFMsgPkt";
BA_ "FlexKomSigLaenge" SG_ 679 FOB_SrchRslt 64;
BA_ "FlexKomSID" SG_ 679 FOB_SrchRslt 1038;
BA_ "FlexKomIsMotorola" SG_ 679 FOB_SrchRslt 1;
BA_ "FlexKomComment" SG_ 679 FOB_SrchRslt "RF message packet";
BA_ "GenSigSNA" SG_ 679 FOB_SrchFLT "0h";
BA_ "GenSigSendType" SG_ 679 FOB_SrchFLT 5;
BA_ "GenSigCycleTime" SG_ 679 FOB_SrchFLT 1000;
BA_ "FlexKomSigStartValue" SG_ 679 FOB_SrchFLT "0000000000000000h";
BA_ "FlexKomSigStartPos" SG_ 679 FOB_SrchFLT 7;
BA_ "FlexKomSigName" SG_ 679 FOB_SrchFLT "RFMsgPkt";
BA_ "FlexKomSigLaenge" SG_ 679 FOB_SrchFLT 64;
BA_ "FlexKomSID" SG_ 679 FOB_SrchFLT 1038;
BA_ "FlexKomIsMotorola" SG_ 679 FOB_SrchFLT 1;
BA_ "FlexKomComment" SG_ 679 FOB_SrchFLT "RF message packet";
BA_ "GenSigSNA" SG_ 679 FOBinTRUNK "0h";
BA_ "GenSigSendType" SG_ 679 FOBinTRUNK 5;
BA_ "GenSigCycleTime" SG_ 679 FOBinTRUNK 1000;
BA_ "FlexKomSigStartValue" SG_ 679 FOBinTRUNK "0000000000000000h";
BA_ "FlexKomSigStartPos" SG_ 679 FOBinTRUNK 7;
BA_ "FlexKomSigName" SG_ 679 FOBinTRUNK "RFMsgPkt";
BA_ "FlexKomSigLaenge" SG_ 679 FOBinTRUNK 64;
BA_ "FlexKomSID" SG_ 679 FOBinTRUNK 1038;
BA_ "FlexKomIsMotorola" SG_ 679 FOBinTRUNK 1;
BA_ "FlexKomComment" SG_ 679 FOBinTRUNK "RF message packet";
BA_ "GenSigSNA" SG_ 679 FOBinINT "0h";
BA_ "GenSigSendType" SG_ 679 FOBinINT 5;
BA_ "GenSigCycleTime" SG_ 679 FOBinINT 1000;
BA_ "FlexKomSigStartValue" SG_ 679 FOBinINT "0000000000000000h";
BA_ "FlexKomSigStartPos" SG_ 679 FOBinINT 7;
BA_ "FlexKomSigName" SG_ 679 FOBinINT "RFMsgPkt";
BA_ "FlexKomSigLaenge" SG_ 679 FOBinINT 64;
BA_ "FlexKomSID" SG_ 679 FOBinINT 1038;
BA_ "FlexKomIsMotorola" SG_ 679 FOBinINT 1;
BA_ "FlexKomComment" SG_ 679 FOBinINT "RF message packet";
BA_ "GenSigSNA" SG_ 679 FOB_ExtRT "0h";
BA_ "GenSigSendType" SG_ 679 FOB_ExtRT 5;
BA_ "GenSigCycleTime" SG_ 679 FOB_ExtRT 1000;
BA_ "FlexKomSigStartValue" SG_ 679 FOB_ExtRT "0000000000000000h";
BA_ "FlexKomSigStartPos" SG_ 679 FOB_ExtRT 7;
BA_ "FlexKomSigName" SG_ 679 FOB_ExtRT "RFMsgPkt";
BA_ "FlexKomSigLaenge" SG_ 679 FOB_ExtRT 64;
BA_ "FlexKomSID" SG_ 679 FOB_ExtRT 1038;
BA_ "FlexKomIsMotorola" SG_ 679 FOB_ExtRT 1;
BA_ "FlexKomComment" SG_ 679 FOB_ExtRT "RF message packet";
BA_ "GenSigSNA" SG_ 679 FOB_ExtLT "0h";
BA_ "GenSigSendType" SG_ 679 FOB_ExtLT 5;
BA_ "GenSigCycleTime" SG_ 679 FOB_ExtLT 1000;
BA_ "FlexKomSigStartValue" SG_ 679 FOB_ExtLT "000000h";
BA_ "FlexKomSigStartPos" SG_ 679 FOB_ExtLT 7;
BA_ "FlexKomSigName" SG_ 679 FOB_ExtLT "RFMsgPkt";
BA_ "FlexKomSigLaenge" SG_ 679 FOB_ExtLT 64;
BA_ "FlexKomSID" SG_ 679 FOB_ExtLT 1038;
BA_ "FlexKomIsMotorola" SG_ 679 FOB_ExtLT 1;
BA_ "FlexKomComment" SG_ 679 FOB_ExtLT "RF message packet";
BA_ "GenSigSNA" SG_ 679 FOB_ExtRR "0h";
BA_ "GenSigSendType" SG_ 679 FOB_ExtRR 5;
BA_ "GenSigCycleTime" SG_ 679 FOB_ExtRR 1000;
BA_ "FlexKomSigStartValue" SG_ 679 FOB_ExtRR "0000000000000000h";
BA_ "FlexKomSigStartPos" SG_ 679 FOB_ExtRR 7;
BA_ "FlexKomSigName" SG_ 679 FOB_ExtRR "RFMsgPkt";
BA_ "FlexKomSigLaenge" SG_ 679 FOB_ExtRR 64;
BA_ "FlexKomSID" SG_ 679 FOB_ExtRR 1038;
BA_ "FlexKomIsMotorola" SG_ 679 FOB_ExtRR 1;
BA_ "FlexKomComment" SG_ 679 FOB_ExtRR "RF message packet";
BA_ "GenSigTimeout_IC" SG_ 685 CBC_AUX1_Type 10500;
BA_ "GenSigSNA" SG_ 685 CBC_AUX1_Type "0h";
BA_ "GenSigSendType" SG_ 685 CBC_AUX1_Type 5;
BA_ "GenSigCycleTime" SG_ 685 CBC_AUX1_Type 1000;
BA_ "FlexKomSigStartValue" SG_ 685 CBC_AUX1_Type "000007000000FFFFh";
BA_ "FlexKomSigStartPos" SG_ 685 CBC_AUX1_Type 7;
BA_ "FlexKomSigName" SG_ 685 CBC_AUX1_Type "CBC_Cfg2_Pkt";
BA_ "FlexKomSigLaenge" SG_ 685 CBC_AUX1_Type 64;
BA_ "FlexKomSID" SG_ 685 CBC_AUX1_Type 1957;
BA_ "FlexKomIsMotorola" SG_ 685 CBC_AUX1_Type 1;
BA_ "FlexKomComment" SG_ 685 CBC_AUX1_Type "Configuration status CBC 2";
BA_ "GenSigTimeout_IC" SG_ 685 CBC_AUX2_Type 10500;
BA_ "GenSigSNA" SG_ 685 CBC_AUX2_Type "0h";
BA_ "GenSigSendType" SG_ 685 CBC_AUX2_Type 5;
BA_ "GenSigCycleTime" SG_ 685 CBC_AUX2_Type 1000;
BA_ "FlexKomSigStartValue" SG_ 685 CBC_AUX2_Type "000007000000FFFFh";
BA_ "FlexKomSigStartPos" SG_ 685 CBC_AUX2_Type 7;
BA_ "FlexKomSigName" SG_ 685 CBC_AUX2_Type "CBC_Cfg2_Pkt";
BA_ "FlexKomSigLaenge" SG_ 685 CBC_AUX2_Type 64;
BA_ "FlexKomSID" SG_ 685 CBC_AUX2_Type 1957;
BA_ "FlexKomIsMotorola" SG_ 685 CBC_AUX2_Type 1;
BA_ "FlexKomComment" SG_ 685 CBC_AUX2_Type "Configuration status CBC 2";
BA_ "GenSigTimeout_IC" SG_ 685 CBC_AUX3_Type 10500;
BA_ "GenSigSNA" SG_ 685 CBC_AUX3_Type "0h";
BA_ "GenSigSendType" SG_ 685 CBC_AUX3_Type 5;
BA_ "GenSigCycleTime" SG_ 685 CBC_AUX3_Type 1000;
BA_ "FlexKomSigStartValue" SG_ 685 CBC_AUX3_Type "000007000000FFFFh";
BA_ "FlexKomSigStartPos" SG_ 685 CBC_AUX3_Type 7;
BA_ "FlexKomSigName" SG_ 685 CBC_AUX3_Type "CBC_Cfg2_Pkt";
BA_ "FlexKomSigLaenge" SG_ 685 CBC_AUX3_Type 64;
BA_ "FlexKomSID" SG_ 685 CBC_AUX3_Type 1957;
BA_ "FlexKomIsMotorola" SG_ 685 CBC_AUX3_Type 1;
BA_ "FlexKomComment" SG_ 685 CBC_AUX3_Type "Configuration status CBC 2";
BA_ "GenSigTimeout_IC" SG_ 685 CBC_AUX4_Type 10500;
BA_ "GenSigSNA" SG_ 685 CBC_AUX4_Type "0h";
BA_ "GenSigSendType" SG_ 685 CBC_AUX4_Type 5;
BA_ "GenSigCycleTime" SG_ 685 CBC_AUX4_Type 1000;
BA_ "FlexKomSigStartValue" SG_ 685 CBC_AUX4_Type "000007000000FFFFh";
BA_ "FlexKomSigStartPos" SG_ 685 CBC_AUX4_Type 7;
BA_ "FlexKomSigName" SG_ 685 CBC_AUX4_Type "CBC_Cfg2_Pkt";
BA_ "FlexKomSigLaenge" SG_ 685 CBC_AUX4_Type 64;
BA_ "FlexKomSID" SG_ 685 CBC_AUX4_Type 1957;
BA_ "FlexKomIsMotorola" SG_ 685 CBC_AUX4_Type 1;
BA_ "FlexKomComment" SG_ 685 CBC_AUX4_Type "Configuration status CBC 2";
BA_ "GenSigTimeout_IC" SG_ 685 CBC_AUX1_PWRMD 10500;
BA_ "GenSigSNA" SG_ 685 CBC_AUX1_PWRMD "0h";
BA_ "GenSigSendType" SG_ 685 CBC_AUX1_PWRMD 5;
BA_ "GenSigCycleTime" SG_ 685 CBC_AUX1_PWRMD 1000;
BA_ "FlexKomSigStartValue" SG_ 685 CBC_AUX1_PWRMD "000007000000FFFFh";
BA_ "FlexKomSigStartPos" SG_ 685 CBC_AUX1_PWRMD 7;
BA_ "FlexKomSigName" SG_ 685 CBC_AUX1_PWRMD "CBC_Cfg2_Pkt";
BA_ "FlexKomSigLaenge" SG_ 685 CBC_AUX1_PWRMD 64;
BA_ "FlexKomSID" SG_ 685 CBC_AUX1_PWRMD 1957;
BA_ "FlexKomIsMotorola" SG_ 685 CBC_AUX1_PWRMD 1;
BA_ "FlexKomComment" SG_ 685 CBC_AUX1_PWRMD "Configuration status CBC 2";
BA_ "GenSigTimeout_IC" SG_ 685 CBC_AUX2_PWRMD 10500;
BA_ "GenSigSNA" SG_ 685 CBC_AUX2_PWRMD "0h";
BA_ "GenSigSendType" SG_ 685 CBC_AUX2_PWRMD 5;
BA_ "GenSigCycleTime" SG_ 685 CBC_AUX2_PWRMD 1000;
BA_ "FlexKomSigStartValue" SG_ 685 CBC_AUX2_PWRMD "000007000000FFFFh";
BA_ "FlexKomSigStartPos" SG_ 685 CBC_AUX2_PWRMD 7;
BA_ "FlexKomSigName" SG_ 685 CBC_AUX2_PWRMD "CBC_Cfg2_Pkt";
BA_ "FlexKomSigLaenge" SG_ 685 CBC_AUX2_PWRMD 64;
BA_ "FlexKomSID" SG_ 685 CBC_AUX2_PWRMD 1957;
BA_ "FlexKomIsMotorola" SG_ 685 CBC_AUX2_PWRMD 1;
BA_ "FlexKomComment" SG_ 685 CBC_AUX2_PWRMD "Configuration status CBC 2";
BA_ "GenSigTimeout_IC" SG_ 685 CBC_AUX3_PWRMD 10500;
BA_ "GenSigSNA" SG_ 685 CBC_AUX3_PWRMD "0h";
BA_ "GenSigSendType" SG_ 685 CBC_AUX3_PWRMD 5;
BA_ "GenSigCycleTime" SG_ 685 CBC_AUX3_PWRMD 1000;
BA_ "FlexKomSigStartValue" SG_ 685 CBC_AUX3_PWRMD "000007000000FFFFh";
BA_ "FlexKomSigStartPos" SG_ 685 CBC_AUX3_PWRMD 7;
BA_ "FlexKomSigName" SG_ 685 CBC_AUX3_PWRMD "CBC_Cfg2_Pkt";
BA_ "FlexKomSigLaenge" SG_ 685 CBC_AUX3_PWRMD 64;
BA_ "FlexKomSID" SG_ 685 CBC_AUX3_PWRMD 1957;
BA_ "FlexKomIsMotorola" SG_ 685 CBC_AUX3_PWRMD 1;
BA_ "FlexKomComment" SG_ 685 CBC_AUX3_PWRMD "Configuration status CBC 2";
BA_ "GenSigTimeout_IC" SG_ 685 CBC_AUX4_PWRMD 10500;
BA_ "GenSigSNA" SG_ 685 CBC_AUX4_PWRMD "0h";
BA_ "GenSigSendType" SG_ 685 CBC_AUX4_PWRMD 5;
BA_ "GenSigCycleTime" SG_ 685 CBC_AUX4_PWRMD 1000;
BA_ "FlexKomSigStartValue" SG_ 685 CBC_AUX4_PWRMD "000007000000FFFFh";
BA_ "FlexKomSigStartPos" SG_ 685 CBC_AUX4_PWRMD 7;
BA_ "FlexKomSigName" SG_ 685 CBC_AUX4_PWRMD "CBC_Cfg2_Pkt";
BA_ "FlexKomSigLaenge" SG_ 685 CBC_AUX4_PWRMD 64;
BA_ "FlexKomSID" SG_ 685 CBC_AUX4_PWRMD 1957;
BA_ "FlexKomIsMotorola" SG_ 685 CBC_AUX4_PWRMD 1;
BA_ "FlexKomComment" SG_ 685 CBC_AUX4_PWRMD "Configuration status CBC 2";
BA_ "GenSigTimeout_IC" SG_ 685 CBC_AUX1_HLEnbl 10500;
BA_ "GenSigSNA" SG_ 685 CBC_AUX1_HLEnbl "0h";
BA_ "GenSigSendType" SG_ 685 CBC_AUX1_HLEnbl 5;
BA_ "GenSigCycleTime" SG_ 685 CBC_AUX1_HLEnbl 1000;
BA_ "FlexKomSigStartValue" SG_ 685 CBC_AUX1_HLEnbl "000007000000FFFFh";
BA_ "FlexKomSigStartPos" SG_ 685 CBC_AUX1_HLEnbl 7;
BA_ "FlexKomSigName" SG_ 685 CBC_AUX1_HLEnbl "CBC_Cfg2_Pkt";
BA_ "FlexKomSigLaenge" SG_ 685 CBC_AUX1_HLEnbl 64;
BA_ "FlexKomSID" SG_ 685 CBC_AUX1_HLEnbl 1957;
BA_ "FlexKomIsMotorola" SG_ 685 CBC_AUX1_HLEnbl 1;
BA_ "FlexKomComment" SG_ 685 CBC_AUX1_HLEnbl "Configuration status CBC 2";
BA_ "GenSigTimeout_IC" SG_ 685 CBC_AUX2_HLEnbl 10500;
BA_ "GenSigSNA" SG_ 685 CBC_AUX2_HLEnbl "0h";
BA_ "GenSigSendType" SG_ 685 CBC_AUX2_HLEnbl 5;
BA_ "GenSigCycleTime" SG_ 685 CBC_AUX2_HLEnbl 1000;
BA_ "FlexKomSigStartValue" SG_ 685 CBC_AUX2_HLEnbl "000007000000FFFFh";
BA_ "FlexKomSigStartPos" SG_ 685 CBC_AUX2_HLEnbl 7;
BA_ "FlexKomSigName" SG_ 685 CBC_AUX2_HLEnbl "CBC_Cfg2_Pkt";
BA_ "FlexKomSigLaenge" SG_ 685 CBC_AUX2_HLEnbl 64;
BA_ "FlexKomSID" SG_ 685 CBC_AUX2_HLEnbl 1957;
BA_ "FlexKomIsMotorola" SG_ 685 CBC_AUX2_HLEnbl 1;
BA_ "FlexKomComment" SG_ 685 CBC_AUX2_HLEnbl "Configuration status CBC 2";
BA_ "GenSigTimeout_IC" SG_ 685 CBC_AUX3_HLEnbl 10500;
BA_ "GenSigSNA" SG_ 685 CBC_AUX3_HLEnbl "0h";
BA_ "GenSigSendType" SG_ 685 CBC_AUX3_HLEnbl 5;
BA_ "GenSigCycleTime" SG_ 685 CBC_AUX3_HLEnbl 1000;
BA_ "FlexKomSigStartValue" SG_ 685 CBC_AUX3_HLEnbl "000007000000FFFFh";
BA_ "FlexKomSigStartPos" SG_ 685 CBC_AUX3_HLEnbl 7;
BA_ "FlexKomSigName" SG_ 685 CBC_AUX3_HLEnbl "CBC_Cfg2_Pkt";
BA_ "FlexKomSigLaenge" SG_ 685 CBC_AUX3_HLEnbl 64;
BA_ "FlexKomSID" SG_ 685 CBC_AUX3_HLEnbl 1957;
BA_ "FlexKomIsMotorola" SG_ 685 CBC_AUX3_HLEnbl 1;
BA_ "FlexKomComment" SG_ 685 CBC_AUX3_HLEnbl "Configuration status CBC 2";
BA_ "GenSigTimeout_IC" SG_ 685 CBC_AUX4_HLEnbl 10500;
BA_ "GenSigSNA" SG_ 685 CBC_AUX4_HLEnbl "0h";
BA_ "GenSigSendType" SG_ 685 CBC_AUX4_HLEnbl 5;
BA_ "GenSigCycleTime" SG_ 685 CBC_AUX4_HLEnbl 1000;
BA_ "FlexKomSigStartValue" SG_ 685 CBC_AUX4_HLEnbl "000007000000FFFFh";
BA_ "FlexKomSigStartPos" SG_ 685 CBC_AUX4_HLEnbl 7;
BA_ "FlexKomSigName" SG_ 685 CBC_AUX4_HLEnbl "CBC_Cfg2_Pkt";
BA_ "FlexKomSigLaenge" SG_ 685 CBC_AUX4_HLEnbl 64;
BA_ "FlexKomSID" SG_ 685 CBC_AUX4_HLEnbl 1957;
BA_ "FlexKomIsMotorola" SG_ 685 CBC_AUX4_HLEnbl 1;
BA_ "FlexKomComment" SG_ 685 CBC_AUX4_HLEnbl "Configuration status CBC 2";
BA_ "GenSigTimeout_IC" SG_ 685 Cfg_Aux_PTO 10500;
BA_ "GenSigStartValue" SG_ 685 Cfg_Aux_PTO 7;
BA_ "GenSigSNA" SG_ 685 Cfg_Aux_PTO "7h";
BA_ "GenSigSendType" SG_ 685 Cfg_Aux_PTO 5;
BA_ "GenSigCycleTime" SG_ 685 Cfg_Aux_PTO 1000;
BA_ "FlexKomSigStartValue" SG_ 685 Cfg_Aux_PTO "000007000000FFFFh";
BA_ "FlexKomSigStartPos" SG_ 685 Cfg_Aux_PTO 7;
BA_ "FlexKomSigName" SG_ 685 Cfg_Aux_PTO "CBC_Cfg2_Pkt";
BA_ "FlexKomSigLaenge" SG_ 685 Cfg_Aux_PTO 64;
BA_ "FlexKomSID" SG_ 685 Cfg_Aux_PTO 1957;
BA_ "FlexKomIsMotorola" SG_ 685 Cfg_Aux_PTO 1;
BA_ "FlexKomComment" SG_ 685 Cfg_Aux_PTO "Configuration status CBC 2";
BA_ "RID" SG_ 689 FT_HVAC_BLW_FN_SP "1070";
BA_ "GenSigTimeout_IC" SG_ 689 FT_HVAC_BLW_FN_SP 10500;
BA_ "GenSigStartValue" SG_ 689 FT_HVAC_BLW_FN_SP 127;
BA_ "GenSigSNA" SG_ 689 FT_HVAC_BLW_FN_SP "7Fh";
BA_ "GenSigSendType" SG_ 689 FT_HVAC_BLW_FN_SP 5;
BA_ "GenSigCycleTime" SG_ 689 FT_HVAC_BLW_FN_SP 1000;
BA_ "FlexKomSigStartValue" SG_ 689 FT_HVAC_BLW_FN_SP "7F8FFFFF7Fh";
BA_ "FlexKomSigStartPos" SG_ 689 FT_HVAC_BLW_FN_SP 7;
BA_ "FlexKomSigName" SG_ 689 FT_HVAC_BLW_FN_SP "GW_Dev";
BA_ "FlexKomSigLaenge" SG_ 689 FT_HVAC_BLW_FN_SP 40;
BA_ "FlexKomSID" SG_ 689 FT_HVAC_BLW_FN_SP 1445;
BA_ "FlexKomIsMotorola" SG_ 689 FT_HVAC_BLW_FN_SP 1;
BA_ "FlexKomComment" SG_ 689 FT_HVAC_BLW_FN_SP "Temporary development packet - route signals from ";
BA_ "RID" SG_ 689 DRV_TEMP_DR_POS "1232";
BA_ "GenSigStartValue" SG_ 689 DRV_TEMP_DR_POS 127;
BA_ "GenSigSNA" SG_ 689 DRV_TEMP_DR_POS "7Fh";
BA_ "GenSigSendType" SG_ 689 DRV_TEMP_DR_POS 5;
BA_ "GenSigCycleTime" SG_ 689 DRV_TEMP_DR_POS 1000;
BA_ "FlexKomSigStartValue" SG_ 689 DRV_TEMP_DR_POS "7F8FFFFF7Fh";
BA_ "FlexKomSigStartPos" SG_ 689 DRV_TEMP_DR_POS 7;
BA_ "FlexKomSigName" SG_ 689 DRV_TEMP_DR_POS "GW_Dev";
BA_ "FlexKomSigLaenge" SG_ 689 DRV_TEMP_DR_POS 40;
BA_ "FlexKomSID" SG_ 689 DRV_TEMP_DR_POS 1445;
BA_ "FlexKomIsMotorola" SG_ 689 DRV_TEMP_DR_POS 1;
BA_ "FlexKomComment" SG_ 689 DRV_TEMP_DR_POS "Temporary development packet - route signals from ";
BA_ "RID" SG_ 689 PAS_TEMP_DR_POS "1205";
BA_ "GenSigStartValue" SG_ 689 PAS_TEMP_DR_POS 127;
BA_ "GenSigSNA" SG_ 689 PAS_TEMP_DR_POS "7Fh";
BA_ "GenSigSendType" SG_ 689 PAS_TEMP_DR_POS 5;
BA_ "GenSigCycleTime" SG_ 689 PAS_TEMP_DR_POS 1000;
BA_ "FlexKomSigStartValue" SG_ 689 PAS_TEMP_DR_POS "7F8FFFFF7Fh";
BA_ "FlexKomSigStartPos" SG_ 689 PAS_TEMP_DR_POS 7;
BA_ "FlexKomSigName" SG_ 689 PAS_TEMP_DR_POS "GW_Dev";
BA_ "FlexKomSigLaenge" SG_ 689 PAS_TEMP_DR_POS 40;
BA_ "FlexKomSID" SG_ 689 PAS_TEMP_DR_POS 1445;
BA_ "FlexKomIsMotorola" SG_ 689 PAS_TEMP_DR_POS 1;
BA_ "FlexKomComment" SG_ 689 PAS_TEMP_DR_POS "Temporary development packet - route signals from ";
BA_ "GenSigSNA" SG_ 698 UConnReqAuthCode "FFFFh";
BA_ "GenSigSendType" SG_ 698 UConnReqAuthCode 8;
BA_ "GenSigCycleTimeActive" SG_ 698 UConnReqAuthCode 100;
BA_ "FlexKomSigStartValue" SG_ 698 UConnReqAuthCode "00000000h";
BA_ "FlexKomSigStartPos" SG_ 698 UConnReqAuthCode 7;
BA_ "FlexKomSigName" SG_ 698 UConnReqAuthCode "Uconnect_1_Pkt";
BA_ "FlexKomSigLaenge" SG_ 698 UConnReqAuthCode 32;
BA_ "FlexKomSID" SG_ 698 UConnReqAuthCode 1772;
BA_ "FlexKomIsMotorola" SG_ 698 UConnReqAuthCode 1;
BA_ "FlexKomComment" SG_ 698 UConnReqAuthCode "Uconnect_1_Pkt";
BA_ "GenSigSNA" SG_ 698 UConnReqFOBNum "Fh";
BA_ "GenSigSendType" SG_ 698 UConnReqFOBNum 8;
BA_ "GenSigCycleTimeActive" SG_ 698 UConnReqFOBNum 100;
BA_ "FlexKomSigStartValue" SG_ 698 UConnReqFOBNum "00000000h";
BA_ "FlexKomSigStartPos" SG_ 698 UConnReqFOBNum 7;
BA_ "FlexKomSigName" SG_ 698 UConnReqFOBNum "Uconnect_1_Pkt";
BA_ "FlexKomSigLaenge" SG_ 698 UConnReqFOBNum 32;
BA_ "FlexKomSID" SG_ 698 UConnReqFOBNum 1772;
BA_ "FlexKomIsMotorola" SG_ 698 UConnReqFOBNum 1;
BA_ "FlexKomComment" SG_ 698 UConnReqFOBNum "Uconnect_1_Pkt";
BA_ "GenSigSNA" SG_ 698 UConnReq "1Fh";
BA_ "GenSigSendType" SG_ 698 UConnReq 8;
BA_ "GenSigCycleTimeActive" SG_ 698 UConnReq 100;
BA_ "FlexKomSigStartValue" SG_ 698 UConnReq "00000000h";
BA_ "FlexKomSigStartPos" SG_ 698 UConnReq 7;
BA_ "FlexKomSigName" SG_ 698 UConnReq "Uconnect_1_Pkt";
BA_ "FlexKomSigLaenge" SG_ 698 UConnReq 32;
BA_ "FlexKomSID" SG_ 698 UConnReq 1772;
BA_ "FlexKomIsMotorola" SG_ 698 UConnReq 1;
BA_ "FlexKomComment" SG_ 698 UConnReq "Uconnect_1_Pkt";
VAL_ 599 SBR2ndRowCSeatSts 0 "PSG_SEAT_OK" 2 "PSG_SEAT_NOK" 3 "SEAT_EMPTY" 4 "FAULT_OC" 5 "FAULT_SC" 6 "SNA" 7 "REMOVE_SEAT" ;
VAL_ 599 SBR2ndRowLSeatSts 0 "PSG_SEAT_OK" 2 "PSG_SEAT_NOK" 3 "SEAT_EMPTY" 4 "FAULT_OC" 5 "FAULT_SC" 6 "SNA" 7 "REMOVE_SEAT" ;
VAL_ 599 SBR2ndRowRSeatSts 0 "PSG_SEAT_OK" 2 "PSG_SEAT_NOK" 3 "SEAT_EMPTY" 4 "FAULT_OC" 5 "FAULT_SC" 6 "SNA" 7 "REMOVE_SEAT" ;
VAL_ 601 PsgSeatOCSts 0 "CLASS0" 1 "CLASS1" 3 "CLASS3" 4 "CLASS4" 15 "SNA" ;
VAL_ 601 PsgSeatSBRSts 0 "CLASS0" 1 "CLASS1" 15 "SNA" ;
VAL_ 605 PwrTop_Cmd 0 "NOT_ACTIVE" 1 "OPEN_ACTIVE" 2 "CLS_ACTIVE" 3 "SNA" ;
VAL_ 605 PwrTop_Pos 0 "DEF" 1 "PARTIAL_OPEN" 2 "FULL_OPEN" 3 "FULL_CLS" ;
VAL_ 605 AxleLckrSEL_SW 0 "NOT_PSD" 1 "UP_PSD" 2 "DOWN_PSD" 3 "SNA" ;
VAL_ 605 AxleLckrOFF_SW 0 "NOT_PSD" 1 "PSD" 3 "SNA" ;
VAL_ 605 PwrTop_Stat 0 "DEF" 1 "OBSTRUCTED" 2 "SPEED_INH" 3 "COLD_INH" 4 "LATCHED" 7 "SNA" ;
VAL_ 605 PwrTop_Cal 0 "DEF" 1 "PT_UNCAL" 2 "PT_CAL_IN_PROG" 3 "PT_CAL_INTERUPT" 4 "PT_CAL_COMPLETE" 5 "PT_UNCAL_ENG_OFF" 7 "SNA" ;
VAL_ 605 TGW_AUD_MD2_CAB_DR 0 "NONE" 1 "Android_Auto" 2 "Apple_CarPlay" 3 "Music_Muted" 4 "Baidu_CarLife" 5 "Amazon_Alexa" ;
VAL_ 607 CBC_Reset_Flag 0 "DEFAULT" 2 "CBC_RESET_STATUS" 3 "SNA" ;
VAL_ 607 HRD_TOP_OFF 0 "TOP_ON" 1 "TOP_OFF" ;
VAL_ 607 GlobDrvMdSts 0 "NONE" 1 "AUTO" 2 "SPORT" 3 "TRACK" 4 "SNOW" 5 "VALET" 6 "ROCK" 7 "TOW" 8 "ECO" 9 "LAUNCH" 10 "ALL" 11 "CUSTOM" 12 "MUD" 13 "SAND" 14 "PLUS" 15 "ICE" 16 "DYNAMIC" 17 "OFFROAD" 31 "SNA" ;
VAL_ 607 EngineOffTimer 4095 "SNA" ;
VAL_ 607 HL_MD 0 "Off" 1 "Park_Lamps" 2 "Low_Beams" 3 "Auto" 4 "Short_Circuit" 5 "Open_Circuit" 7 "SNA" ;
VAL_ 609 IBS_Q_received 65535 "SNA" ;
VAL_ 609 IBS_Q_released 65535 "SNA" ;
VAL_ 609 IBS_Tm_Lst_Reset_Sec 65535 "SNA" ;
VAL_ 609 IBS_Tm_Lst_Reset_Days 4095 "SNA" ;
VAL_ 611 EstTimeofChrg_Lv2 2047 "SNA" ;
VAL_ 611 ChargingLevel 0 "Default_NoLevel" 1 "Level_1_AC" 2 "Level_2_AC" 3 "Level_3_AC" 4 "Level_1_DC" 5 "Level_2_DC" 6 "PlugInNotDet" 7 "PPI_1_No_Drive" 8 "PPI_2_OK_Drive" 15 "SNA" ;
VAL_ 611 EstTimeofChrg_Lv1 8191 "SNA" ;
VAL_ 611 MIL_OnRq_BPCM 0 "FALSE" 1 "TRUE" ;
VAL_ 611 HtrCoreInletTemp 255 "SNA" ;
VAL_ 611 ChargingSysSts 0 "NotCharging" 1 "Charging" 2 "ChargeInterrupted" 3 "ChargeComplete" 7 "SNA" ;
VAL_ 611 CompStat 0 "NormalOperation" 1 "DegradedOperation" 2 "Inoperative" 3 "Reserved1" 4 "Reserved2" 5 "Reserved3" 6 "Reserved4" 15 "SNA" ;
VAL_ 611 CabinPreCondReqStat 0 "DEFAULT" 1 "PRE" 2 "SPR" 3 "PRE_OFF" 4 "PRF" 5 "NOT_OK" 6 "BCC" 7 "BCS" 8 "STOPPED_DUE_TO_SOC" 9 "REJECTED_NOT_PLUGGED_IN" 15 "SNA" ;
VAL_ 611 HVBatCntctrStat 0 "Open" 1 "Precharging" 2 "Closed" 3 "Precharge_Failed" 4 "Precharge_Inhibited" 7 "SNA" ;
VAL_ 611 V2L_DischargingSysStat 0 "Inactive" 1 "Active" 2 "Faulted" 7 "SNA" ;
VAL_ 613 DrvMd_PopUpRqst 0 "TM0" 1 "TM1" 2 "TM2" 3 "TM3" 4 "TM4" 5 "TM5" 6 "TM6" 7 "TM7" 8 "TM8" 9 "TM9" 10 "TM10" 11 "TM11" 12 "TM12" 13 "TM13" 14 "TM14" 15 "TM15" 16 "TM16" 17 "TM17" 18 "TM18" 19 "TM19" 20 "TM20" 21 "TM21" 22 "TM22" 255 "SNA" ;
VAL_ 613 DriverDoorOnOffSts 0 "DOOR_ON" 1 "DOOR_OFF" 2 "FLT" 3 "SNA" ;
VAL_ 613 PsngrDoorOnOffSts 0 "DOOR_ON" 1 "DOOR_OFF" 2 "FLT" 3 "SNA" ;
VAL_ 613 LHRDoorOnOffSts 0 "DOOR_ON" 1 "DOOR_OFF" 2 "FLT" 3 "SNA" ;
VAL_ 613 RHRDoorOnOffSts 0 "DOOR_ON" 1 "DOOR_OFF" 2 "FLT" 3 "SNA" ;
VAL_ 621 ElecCoolantHtrPwr 255 "SNA" ;
VAL_ 621 ElecClntHtrInletTemp 255 "SNA" ;
VAL_ 621 HTAuxPmpRPMAct 255 "SNA" ;
VAL_ 621 HVBat_CoolantLvlLo 0 "FALSE" 1 "TRUE" 3 "SNA" ;
VAL_ 621 HTAuxPmpMontrngRPM 0 "TRUE" 1 "FALSE" 3 "SNA" ;
VAL_ 623 SwayBarBtnRq 0 "NOT_PRESSED" 1 "PRESSED" 2 "STUCK" 3 "SNA" ;
VAL_ 623 HtrCorTmp_InTgt 255 "SNA" ;
VAL_ 623 VEH_INT_TEMP 65535 "SNA" ;
VAL_ 623 HVAC_Blwr_Perct 127 "SNA" ;
VAL_ 631 TCASE_SRV_RQ 0 "OFF" 1 "ON" 2 "BLINK" 3 "SNA" ;
VAL_ 631 Tcase4Lock 0 "OFF" 1 "ON" 2 "BLINK" 3 "SNA" ;
VAL_ 631 Tcase4Low 0 "OFF" 1 "ON" 2 "BLINK" 3 "SNA" ;
VAL_ 631 TcaseNtrlStat 0 "OFF" 1 "ON" 2 "BLINK" 3 "SNA" ;
VAL_ 631 TcaseAWD 0 "OFF" 1 "ON" 2 "BLINK" 3 "SNA" ;
VAL_ 631 RrAxleLkIndRq 0 "OFF" 1 "ON" 2 "BLINK" 3 "SNA" ;
VAL_ 631 CNT_DIFF_MOD 0 "FREE" 1 "LM" 2 "ESP" 3 "SNA" ;
VAL_ 631 Tcase2WD_Stat 0 "OFF" 1 "ON" 2 "BLINK" 3 "SNA" ;
VAL_ 631 DTCM_HMI_Rq 0 "NONE" 1 "SCREEN_1" 2 "SCREEN_2" 3 "SCREEN_3" 4 "SCREEN_4" 5 "SCREEN_5" 6 "SCREEN_6" 7 "SCREEN_7" 8 "SCREEN_8" 9 "SCREEN_9" 10 "SCREEN_10" 11 "SCREEN_11" 12 "SCREEN_12" 13 "SCREEN_13" 14 "SCREEN_14" 15 "SCREEN_15" 16 "SCREEN_16" 17 "SCREEN_17" 18 "SCREEN_18" 19 "SCREEN_19" 20 "SCREEN_20" 21 "SCREEN_21" 22 "SCREEN_22" 23 "SCREEN_23" 24 "SCREEN_24" 25 "SCREEN_25" 26 "SCREEN_26" 27 "SCREEN_27" 28 "SCREEN_28" 29 "SCREEN_29" 30 "SCREEN_30" 31 "SNA" ;
VAL_ 631 Ft_RrAxleLkIndRq 0 "OFF" 1 "ON" 2 "BLINK" 3 "SNA" ;
VAL_ 631 AxleLckrEVICDisplay 0 "NONE" 1 "SCREEN_1" 2 "SCREEN_2" 3 "SCREEN_3" 4 "SCREEN_4" 5 "SCREEN_5" 6 "SCREEN_6" 7 "SCREEN_7" 8 "SCREEN_8" 9 "SCREEN_9" 10 "SCREEN_10" 11 "SCREEN_11" 12 "SCREEN_12" 13 "SCREEN_13" 14 "SCREEN_14" 15 "SNA" ;
VAL_ 631 AxleLckrSts 0 "UNLOCKED" 1 "RR_LKD" 2 "FR_RR_LKD" 3 "SNA" ;
VAL_ 631 AXLELCKR_SRV_RQ 0 "OFF" 1 "ON" 2 "BLINK" 3 "SNA" ;
VAL_ 633 FuelMM_Sts 0 "INACTIVE" 1 "ACTIVE" 2 "DISABLED" ;
VAL_ 633 DisOilLifeRst 65535 "SNA" ;
VAL_ 633 OilLifeLeft 255 "SNA" ;
VAL_ 633 HoursOilLifeRst 4095 "SNA" ;
VAL_ 633 MntncSts 0 "NONE" 1 "SOON" 2 "NOW" 3 "SNA" ;
VAL_ 634 ODO 16777215 "SNA" ;
VAL_ 634 AvgFuelLvl 511 "SNA" ;
VAL_ 634 SRS_LMP_STAT 0 "SRS_LMP_OFF" 1 "SRS_LMP_ON" 2 "SRS_LMP_ON_IC" 3 "SNA" ;
VAL_ 635 Gas_Range 1023 "SNA" ;
VAL_ 635 Total_Range 2047 "SNA" ;
VAL_ 635 TSI_FeatureStatus 0 "Not_Active" 1 "Active" ;
VAL_ 641 IBS_R_Batt 2047 "SNA" ;
VAL_ 641 TGW_AUD_MD_CAB_DR 0 "AM_SEL" 1 "FM_SEL" 2 "MW_SEL" 3 "LW_SEL" 4 "INT_Disk_SEL" 5 "INT_HDD_SEL" 6 "INT_AUX_SEL" 7 "INT_SLOT_SEL" 8 "USB3_SEL" 9 "SDAR1_SEL" 10 "SW_SEL" 11 "VES_DVD1_SEL" 12 "TMM_SEL" 13 "VES_AUX1_SEL" 14 "VES_AUX2_SEL" 15 "SDARV_SEL" 16 "PPR_SEL" 18 "DAB_SEL" 19 "TGW_USB1_SEL" 20 "ES_SEL" 21 "VES_AUX3_SEL" 22 "VES_AUX4_SEL" 23 "PASS_BT1_SEL" 24 "TV_SEL" 25 "USB2_SEL" 26 "APPS_SEL" 27 "AUD_MUTED" 28 "IR_OFF" 29 "RAD_OFF" 30 "RAD_LOCK" 31 "SNA" ;
VAL_ 641 IBS_R_Batt_25 2047 "SNA" ;
VAL_ 641 Trns_DrvMdReq 0 "NP" 1 "STREET" 2 "VALET" 3 "SPORT" 4 "S_PLUS" 5 "TRACK" 6 "ECO" 7 "SNOW" 8 "ROCK" 9 "TOW" 10 "DRAG" 11 "MUD" 12 "SAND" 13 "BAJA" 15 "SNA" ;
VAL_ 641 PaddlesModeReq 0 "NONE" 1 "DIS" 2 "EN" 3 "SNA" ;
VAL_ 641 TBM_E_CALL_STS 0 "OFF" 1 "SOS_SERVICE" 2 "SOS_BATT" 3 "SOS_START" 4 "SOS_Call" 5 "SOS_EST" 6 "SOS_END" 7 "SOS_INCOM" 8 "SOS_UNABLE" 9 "SOS_START_CANCEL" 10 "OS_UPDATING" 11 "OS_UPDATED" 12 "BM_MSG1" 13 "BM_MSG2" 14 "BM_MSG3" 15 "SNA" ;
VAL_ 641 PSS_Display 0 "OK" 1 "L_OBS_DET" 2 "R_OBS_DET" 3 "L_STEP_DSBL" 4 "R_STEP_DSBL" 5 "PK" 6 "Reserved" 9 "BOTH_DEPLOYED" 10 "BOTH_RETRACTED" 15 "SNA" ;
VAL_ 643 WPR_SYS_OFF 1 "SNA" ;
VAL_ 643 WPR_SYS_LOW 0 "SNA" ;
VAL_ 643 WPR_SYS_HIGH 0 "SNA" ;
VAL_ 643 WPR_SYS_INT 0 "SNA" ;
VAL_ 643 WPR_SYS_AUTO 0 "SNA" ;
VAL_ 643 WPR_SYS_MIST 0 "SNA" ;
VAL_ 643 WPR_SYS_WASH 0 "SNA" ;
VAL_ 643 WPR_SYS_FLT 0 "SNA" ;
VAL_ 643 RemSt_Inhibit 0 "INHIBIT_DEFAUILT" 1 "TIME_OUT_RUN" 2 "TIME_OUT_CUST_MODE" 3 "KEY_IN_RUN" 4 "DRV_DOOR_AJAR" 5 "PASS_DOOR_AJAR" 6 "LR_DOOR_AJAR" 7 "RR_DOOR_AJAR" 8 "START_COUNTER" 9 "FAIL_COUNTER" 10 "LOW_RPM_SHUTDOWN" 11 "KEY_IN_IGN" 12 "BRAKE_PRESSED" 13 "HAZARD_LAMP_ON" 14 "NOT_IN_PARK" 15 "VEH_SPEED_HIGH" 16 "HOOD_AJAR" 17 "TRUNK_LIFTGATE" 18 "VTA_ALARM" 19 "PANIC_MODE" 20 "BATT_VOLT_HIGH" 21 "BATT_VOLT_LOW" 22 "POWER_LOSS" 23 "MIL_ON" 24 "OIL_PRESSURE_LOW" 25 "COOLANT_TEMP_HIGH" 26 "RPM_HIGH" 27 "CRANK_NO_START" 28 "REMOTE_OFF_RQ" 29 "RS_DISABLED_PREV" 30 "NOT_CONFIGURED" 31 "NO_HOOD_SWITCH" 32 "NO_AUTO_TRANS" 33 "NOT_ENABLED" 34 "INVALID_SKIM_KEY" 35 "IGN_SNA" 36 "IGN_NOT_LOCK" 37 "GLOW_PLUG_TIMEOUT" 38 "LOW_FUEL" 39 "ETC_LAMP_ON" 40 "LOGISTIC_MODE" 41 "COLD_START_LAMP" 42 "ESL_NOT_UNLOCK" 43 "RFHUB_HS_FAIL" 44 "PSA_Not_Active" 45 "ABORT_CRANKING_ENABLE" 255 "SNA" ;
VAL_ 649 HVAC_CLNT_FLW_MIN 0 "OPEN" 254 "CLOSE" 255 "SNA" ;
VAL_ 650 SS_Stat_Left 0 "Reserved" 1 "L_SS_RETRACTING" 2 "L_SS_DEPLOYING" 3 "L_SS_DEPLOYED" 4 "L_SS_IP_STATE" 5 "L_SS_RETRACTED" 6 "Reserved" 7 "SNA" ;
VAL_ 650 SS_Stat_Right 0 "Reserved" 1 "R_SS_RETRACTING" 2 "R_SS_DEPLOYING" 3 "R_SS_DEPLOYED" 4 "R_SS_IP_STATE" 5 "R_SS_RETRACTED" 6 "Reserved" 7 "SNA" ;
VAL_ 650 PreCondCabinSts 0 "OFF" 1 "ON" 2 "SPR" 3 "SNA" ;
VAL_ 650 SOSFailSts 0 "Fail_not_present" 1 "Fail_present" ;
VAL_ 651 HILL_DES_RQ_ICS 0 "NOT_PSD" 1 "PSD" 3 "SNA" ;
VAL_ 657 DR_LK_STAT 0 "LKD" 1 "DRV_DR_UNLKD" 2 "ALL_DR_UNLKD" 3 "SNA" ;
VAL_ 657 FOB_SrchRq 0 "NO_ACT" 1 "SEARCH" 2 "RCVD_RSLT" ;
VAL_ 657 IGN_OFF_TIME_LNG 4095 "SNA" ;
VAL_ 657 SHIP_STAT 0 "CUST_MD" 1 "ABBRV_MD" 2 "SHIP_MD" 3 "NOT_PROG" ;
VAL_ 657 PTC_REL1_STAT 0 "OFF" 1 "ON" 2 "FLT" 3 "SNA" ;
VAL_ 657 PTC_REL2_STAT 0 "OFF" 1 "ON" 2 "FLT" 3 "SNA" ;
VAL_ 657 PTC_REL3_STAT 0 "OFF" 1 "ON" 2 "FLT" 3 "SNA" ;
VAL_ 657 PANEL_INTS 255 "SNA" ;
VAL_ 662 TPM_IndLmp_On_Rq 0 "IND_LMP_OFF" 1 "IND_LMP_ON" 2 "IND_LMP_FLASH" 3 "SNA" ;
VAL_ 662 TPM_Sys_Stat 0 "NON_LOCALIZED" 1 "PERF_LOCALIZATION" 2 "LOCALIZATION_CMPLT" 3 "TPM_NA" 7 "SNA" ;
VAL_ 662 TireFL 0 "NORMAL" 1 "LOW" 2 "HIGH" 3 "SNA" ;
VAL_ 662 TireFR 0 "NORMAL" 1 "LOW" 2 "HIGH" 3 "SNA" ;
VAL_ 662 TireRR 0 "NORMAL" 1 "LOW" 2 "HIGH" 3 "SNA" ;
VAL_ 662 TireRL 0 "NORMAL" 1 "LOW" 2 "HIGH" 3 "SNA" ;
VAL_ 662 TirePressFL 255 "SNA" ;
VAL_ 662 TirePressFR 255 "SNA" ;
VAL_ 662 TirePressRL 255 "SNA" ;
VAL_ 662 TirePressRR 255 "SNA" ;
VAL_ 662 TPM_HornChirp 0 "HORN_CHIRP_OFF" 1 "SINGLE_HORN_CHIRP" 2 "MULTIPLE_HORN_CHIRP" 3 "SNA" ;
VAL_ 662 STFASysEnableFault 0 "Absent" 1 "Present" ;
VAL_ 663 SpSt_Pad1 0 "UN_PSD" 1 "PSD" 2 "S_GND" 3 "S_PLUS" 4 "IND" 7 "SNA" ;
VAL_ 663 SpSt_Pad2 0 "UN_PSD" 1 "PSD" 2 "S_GND" 3 "S_PLUS" 4 "IND" 7 "SNA" ;
VAL_ 673 LANG_C 0 "GERMAN" 1 "US_ENGLISH" 2 "FRENCH" 3 "ITALIAN" 4 "SPANISH" 5 "JAPANESE" 6 "PORTUGESE" 7 "DUTCH" 8 "UK_ENGLISH" 9 "MANDARIN_S" 10 "RUSSIAN" 11 "KOREAN" 12 "ARABIC" 13 "BRAZILIAN" 14 "MANDARIN_T" 15 "HINDI" 16 "TURKISH" 17 "POLISH" 31 "LANG_NO_CHG" ;
VAL_ 673 UNIT_SET_CSO 0 "UnitSet_1" 1 "UnitSet_2" 2 "UnitSet_3" 3 "UnitSet_4" ;
VAL_ 673 PowerUnit 0 "KW" 1 "HP_UK" 2 "HP_US" ;
VAL_ 673 PressureUnit 0 "KPA" 1 "BAR" 2 "PSI" ;
VAL_ 673 ConsumptionUnit 0 "KMPL" 1 "LP100KM" 2 "MPG_UK" 3 "MPG_US" 7 "SNA" ;
VAL_ 676 MAP_4_Bar 511 "SNA" ;
VAL_ 676 ECM_WARN_EXT 0 "NONE" 1 "WARN_EXT_1" 2 "WARN_EXT_2" 3 "WARN_EXT_3" 4 "WARN_EXT_4" 5 "WARN_EXT_5" 6 "WARN_EXT_6" 7 "WARN_EXT_7" 8 "WARN_EXT_8" 9 "WARN_EXT_9" 10 "WARN_EXT_10" 12 "WARN_EXT_12" 13 "WARN_EXT_13" 14 "WARN_EXT_14" 15 "WARN_EXT_15" 16 "WARN_EXT_16" 17 "WARN_EXT_17" 18 "WARN_EXT_18" 19 "WARN_EXT_19" 20 "WARN_EXT_20" 21 "WARN_EXT_21" 22 "WARN_EXT_22" 23 "WARN_EXT_23" 24 "WARN_EXT_24" 25 "WARN_EXT_25" ;
VAL_ 676 TransWarmup_Min_RPM 255 "SNA" ;
VAL_ 679 MsgFobBattLow 0 "MSG_DEFAULT" 1 "MSG_ACTIVE" 3 "SNA" ;
VAL_ 679 MsgFobNotFnd 0 "MSG_DEFAULT" 1 "MSG_ACTIVE" 3 "SNA" ;
VAL_ 679 MsgNotInPark 0 "MSG_DEFAULT" 1 "MSG_ACTIVE" 3 "SNA" ;
VAL_ 679 MsgKG1 0 "MSG_DEFAULT" 1 "MSG_ACTIVE" 3 "SNA" ;
VAL_ 679 MsgKG2 0 "MSG_DEFAULT" 1 "MSG_ACTIVE" 3 "SNA" ;
VAL_ 679 FOB_SrchRslt 0 "NO_ACT" 1 "SIP" 2 "COMPLETE" 3 "TIMEOUT" ;
VAL_ 685 Cfg_Aux_PTO 0 "NONE" 3 "FOUR_CUTOFF" 4 "FOUR" 5 "FIVE" 6 "SIX" 7 "SNA" ;
VAL_ 689 FT_HVAC_BLW_FN_SP 127 "SNA" ;
VAL_ 689 DRV_TEMP_DR_POS 127 "SNA" ;
VAL_ 689 PAS_TEMP_DR_POS 127 "SNA" ;
VAL_ 698 UConnReqAuthCode 65535 "SNA" ;
VAL_ 698 UConnReqFOBNum 0 "FOB_DEFAULT" 1 "FOB_1" 2 "FOB_2" 3 "FOB_3" 4 "FOB_4" 5 "FOB_5" 6 "FOB_6" 7 "FOB_7" 8 "FOB_8" 15 "SNA" ;
VAL_ 698 UConnReq 0 "NO_BASIC_REQUEST" 1 "LOCK_REQUEST" 2 "RELOCK_REQUEST" 3 "DRIVER_UNLOCK_REQUEST" 4 "ALL_UNLOCK_REQUEST" 5 "TRUNK_PLG_TOGGLE_REQUEST" 6 "LEFT_SLIDER_TOGGLE_REQUEST" 7 "RIGHT_SLIDER_TOGGLE_REQUEST" 8 "FLIPPER_GLASS_REQUEST" 9 "REMOTE_START_ON" 10 "REMOTE_START_OFF" 11 "GLOBAL_WINDOW_DOWN_REQUEST" 12 "OPEN_CONVERTIBLE_TOP" 13 "CLOSE_CONVERTIBLE_TOP" 14 "PANIC_TOGGLE_REQUEST" 15 "DRIVER_TOGGLE_REQUEST" 16 "PASSENGER_TOGGLE_REQUEST" 17 "ExtLightReq" 18 "AirSuspReq" 19 "AirSuspCancel" 20 "GLBL_WIN_UP_RQ" 21 "CAR_FINDER_REQUEST" 22 "TRUNK_PLG_BTN_PRESSED" 23 "TRUNK_PLG_STOP_REQUEST" 24 "TRUNK_PLG_OPEN_REQUEST" 25 "TRUNK_PLG_CLOSE_REQUEST" 26 "VTA_RQ" 27 "RAP_UNLOCK_REQUEST" 28 "ABORT_CRANKING_ON_REQUEST" 29 "ABORT_CRANKING_OFF_REQUEST" 30 "Remote_Headlights" 31 "SNA" ;
